[part 3 of 5: package /POWERTRAIN]
AUTOSAR XML (schema 3.2.2)
# Copyright (c) 2016 Daimler AG
package /POWERTRAIN  (continued)
  can cluster POWERTRAIN:  (continued)
    physical channel POWERTRAIN
      frame Ign_Veh_Stat_AR2: id 0x20, from CPC, to ASX ECM FFAP_STAR_2 FSCM ISM TCM, frame-length=8, can-addressing-mode=STANDARD  # Status Zündung/Fahrzeug / Ignition/vehicle state
        pdu Ign_Veh_Stat_AR2: length=64, unused-bit-pattern=0, cyclic-timing=repeating-time=0.1, event-controlled-timing=number-of-repeats=0, minimum-delay=0.0050  # Status Zündung/Fahrzeug / Ignition/vehicle state
          signal BusFlt_PrmntActv: start 35, 1 bit, little-endian, data-type=c01_NoFault_KeptAwake, init-value=lNO_FLT, transfer-property=TRIGGERED-ON-CHANGE, to ECM  # Bus fehlerhaft, permanent aktiv / Bus faulty, permanent active
          signal ContEngRun_Stat: start 36, 2 bit, little-endian, data-type=c02_ContEngRun_Stat, init-value=XDIS_9zsg7nirpdj3g8gia96831vcb/l3, transfer-property=TRIGGERED-ON-CHANGE, to ECM  # Status Motorweiterlaufschaltung / Continuous Engine Running State
          signal CRC_Ign_Stat_Pr2: start 0, 8 bit, little-endian, data-type=c08_CRC_woSNA, init-value=l34, transfer-property=PENDING, to ASX ECM FFAP_STAR_2 FSCM(timeout 1.05 s) ISM TCM  # CRC-Checksumme der Signal Gruppe gemäß AUTOSAR Profil 2 / CRC-checksum of signal group according to AUTOSAR Profile 2
          signal DidA_ExtTest_Pres: start 32, 1 bit, little-endian, data-type=DC_BOOL, init-value=XDIS_h5tcyk98kzbgrc5svasomeyt/lfalse, transfer-property=TRIGGERED-ON-CHANGE, to ASX ECM FFAP_STAR_2 FSCM ISM TCM  # DidA Externer Tester erkannt / DidA external tester present
          signal EngSt_Enbl_Rq_KG: start 28, 1 bit, little-endian, data-type=DC_BOOL, init-value=XDIS_h5tcyk98kzbgrc5svasomeyt/lfalse, transfer-property=TRIGGERED-ON-CHANGE, to ASX ECM FFAP_STAR_2 FSCM(timeout 1.05 s) ISM TCM  # Keyless Go Anlassbedingungen erfüllt / Enable engine start request
          signal ESL_Lk_Rq: start 18, 2 bit, little-endian, data-type=c02_ESL_Lk_Rq, init-value=XDIS_wgd5ub5vm3gd9qfahupgvut1/lDEFAULT, transfer-property=TRIGGERED-ON-CHANGE, to ASX ECM FFAP_STAR_2 FSCM(timeout 1.05 s) ISM TCM  # ELV Verriegelungsanforderung / ESL lock request
          signal Ign_On_StartProc_Inact: start 15, 1 bit, little-endian, data-type=DC_BOOL, init-value=XDIS_h5tcyk98kzbgrc5svasomeyt/lfalse, transfer-property=TRIGGERED-ON-CHANGE, to ASX ECM FFAP_STAR_2 FSCM(timeout 1.05 s) ISM TCM  # Zündung an/Motorstart aus / Ignition is on and starting procedure is inactive (15x)
          signal ISw_Stat: start 12, 3 bit, little-endian, data-type=c03_ISw_Stat, init-value=XDIS_15e0cs7gc4dn7o9pdwabj5z3d/l7, transfer-property=TRIGGERED-ON-CHANGE, to ASX ECM FFAP_STAR_2 FSCM(timeout 1.05 s) ISM TCM  # Klemmenstatus / Ignition switch state
          signal KG_IgnCtrl_Actv: start 16, 1 bit, little-endian, data-type=DC_BOOL, init-value=XDIS_h5tcyk98kzbgrc5svasomeyt/lfalse, transfer-property=TRIGGERED-ON-CHANGE, to ASX ECM FFAP_STAR_2 FSCM(timeout 1.05 s) ISM TCM  # Keyless Go Klemmenansteuerung aktiv / Keyless Go ignition control active
          signal KG_StartSw_Psd: start 17, 1 bit, little-endian, data-type=DC_BOOL, init-value=XDIS_h5tcyk98kzbgrc5svasomeyt/lfalse, transfer-property=TRIGGERED-ON-CHANGE, to ASX ECM FFAP_STAR_2 FSCM(timeout 1.05 s) ISM TCM  # Keyless Go Starttaster betätigt / Keyless Go start switch pressed
          signal Mobile_Chrg_Rq_EIS: start 38, 2 bit, little-endian, data-type=c03_Mobile_Chrg_Rq, init-value=XDIS_1pnuwiuijo5o0phdmlg74ub0g/l3, transfer-property=TRIGGERED-ON-CHANGE, to ECM  # Mobilgerät Status Ladeanforderung / Mobile device charging request
          signal RemSt_IgnCtrl_Actv: start 29, 1 bit, little-endian, data-type=DC_BOOL, init-value=XDIS_h5tcyk98kzbgrc5svasomeyt/lfalse, transfer-property=TRIGGERED-ON-CHANGE, to ASX ECM FFAP_STAR_2 FSCM(timeout 1.05 s) ISM TCM  # Klemmensteuerung Motorfernstart aktiv / Remote start ignition control active
          signal RemSt_IgnCtrl_Info: start 30, 2 bit, little-endian, data-type=c02_RemSt_IgnCtrl_Info, init-value=XDIS_f33ngg3qknqq6hf5cbz1jyfyc/lNO_RQ, transfer-property=TRIGGERED-ON-CHANGE, to ASX ECM FFAP_STAR_2 FSCM(timeout 1.05 s) ISM TCM  # Klemmensteuerung Motorfernstart Information / Remote start ignition control information
          signal RevGr_Engg: start 33, 2 bit, little-endian, data-type=c02_Disengg_Engg, init-value=XDIS_bjt3ib7wqik0sqxbiyd3ycy7c/l3, transfer-property=TRIGGERED-ON-CHANGE, to ECM  # Rückwärtsgang eingelegt / Reverse gear engaged
          signal SPCR_AcustWarn_Rq_EIS: start 23, 1 bit, little-endian, data-type=DC_BOOL, init-value=XDIS_h5tcyk98kzbgrc5svasomeyt/lfalse, transfer-property=TRIGGERED-ON-CHANGE, to ASX ECM FFAP_STAR_2 FSCM(timeout 1.05 s) ISM TCM  # Akustische Warnung SPCR / SPCR acoustical warning request
          signal SPCR_Conf_EIS: start 21, 2 bit, little-endian, data-type=c02_SPCR_Conf, init-value=lNOT_CONF, transfer-property=TRIGGERED-ON-CHANGE, to ASX ECM FFAP_STAR_2 FSCM(timeout 1.05 s) ISM TCM  # Konfiguration Stillstandskoordinator / Stop coordinator configuration
          signal SPCR_Flt_EIS: start 20, 1 bit, little-endian, data-type=DC_BOOL, init-value=XDIS_h5tcyk98kzbgrc5svasomeyt/lfalse, transfer-property=TRIGGERED-ON-CHANGE, to ASX ECM FFAP_STAR_2 FSCM(timeout 1.05 s) ISM TCM  # StopCoordinator Failure EIS
          signal SQC_Ign_Stat_Pr2: start 8, 4 bit, little-endian, data-type=c04_0_15_1_SNA_na, init-value=XDIS_2gdok7is6uk227cngmpgf9wxb/l0, transfer-property=PENDING, to ASX ECM FFAP_STAR_2 FSCM(timeout 1.05 s) ISM TCM  # Sequenzzähler / Sequence counter
          signal TxPkPosn_Emg_Rq: start 25, 1 bit, little-endian, data-type=DC_BOOL, init-value=XDIS_h5tcyk98kzbgrc5svasomeyt/lfalse, transfer-property=TRIGGERED-ON-CHANGE, to ASX ECM FFAP_STAR_2 FSCM(timeout 1.05 s) ISM TCM  # Anforderung Not-"P" / Transmission parking position emergency request
          signal TxPkPosn_Rq: start 24, 1 bit, little-endian, data-type=DC_BOOL, init-value=XDIS_h5tcyk98kzbgrc5svasomeyt/lfalse, transfer-property=TRIGGERED-ON-CHANGE, to ASX ECM FFAP_STAR_2 FSCM(timeout 1.05 s) ISM TCM  # EIS-Wunsch: "P" einlegen / Transmission parking position request
          signal TxPkPosn_Rq_SPCR_Enbl: start 27, 1 bit, little-endian, data-type=DC_BOOL, init-value=XDIS_h5tcyk98kzbgrc5svasomeyt/lfalse, transfer-property=TRIGGERED-ON-CHANGE, to ASX ECM FFAP_STAR_2 FSCM(timeout 1.05 s) ISM TCM  # SPCR-Wunsch: "P" einlegen erlaubt / Transmission parking position request enable
          signal TxPkPosnAuto_Enbl: start 26, 1 bit, little-endian, data-type=DC_BOOL, init-value=XDIS_h5tcyk98kzbgrc5svasomeyt/lfalse, transfer-property=TRIGGERED-ON-CHANGE, to ASX ECM FFAP_STAR_2 FSCM(timeout 1.05 s) ISM TCM  # Auto-"P" enabled / Transmission parking position auto enable
          signal Ign_Stat_Pr2_457i75qk4uen9ahb37ecxdhxz: little-endian, system-signal=[CRC_Ign_Stat_Pr2, EngSt_Enbl_Rq_KG, ESL_Lk_Rq, Ign_On_StartProc_Inact, ISw_Stat, KG_IgnCtrl_Actv, KG_StartSw_Psd, RemSt_IgnCtrl_Actv, RemSt_IgnCtrl_Info, SPCR_AcustWarn_Rq_EIS, SPCR_Conf_EIS, SPCR_Flt_EIS, SQC_Ign_Stat_Pr2, TxPkPosn_Emg_Rq, TxPkPosn_Rq, TxPkPosn_Rq_SPCR_Enbl, TxPkPosnAuto_Enbl], to ASX ECM FFAP_STAR_2 FSCM(timeout 1.05 s) ISM TCM  # Zündungsstatus (degraded) / Ignition state (degraded)
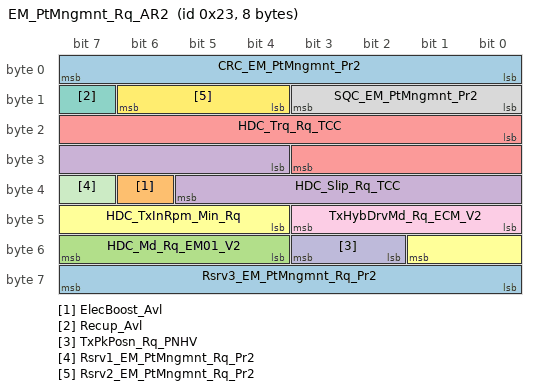
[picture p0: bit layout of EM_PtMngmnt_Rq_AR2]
      frame EM_PtMngmnt_Rq_AR2: id 0x23, from CPC, to ECM TCM, frame-length=8, can-addressing-mode=STANDARD
        pdu EM_PtMngmnt_Rq_AR2: length=64, unused-bit-pattern=0, cyclic-timing={repeating-time=0.02, starting-time=0.0050}
          signal CRC_EM_PtMngmnt_Pr2: start 0, 8 bit, little-endian, data-type=c08_CRC_woSNA, init-value=l74, to ECM TCM  # CRC-Checksumme der Signal Gruppe gemäß AUTOSAR Profil 2 / CRC-checksum of signal group according to AUTOSAR Profile 2
          signal ElecBoost_Avl: start 38, 1 bit, little-endian, data-type=DC_BOOL, init-value=XDIS_h5tcyk98kzbgrc5svasomeyt/lfalse, to ECM TCM  # Elektischer Boost verfügbar / Electrical boost available
          signal HDC_Md_Rq_EM01_V2: start 52, 4 bit, little-endian, data-type=c04_HDC_Md_Rq_EM, init-value=XDIS_8iaq8201r0988d05ciiqwp1g4/lIDLE, to ECM TCM  # Operation-Mode E-Maschine / Electric machine mode
          signal HDC_Slip_Rq_TCC: start 28, 10 bit, little-endian, data-type=c10_rpm_0_1022_1, init-value=XDIS_2gh0e6dr37noeqbe7360vka4a/l1023, to ECM TCM  # Slip request for torque converter lockup clutch
          signal HDC_Trq_Rq_TCC: start 16, 12 bit, little-endian, data-type=c12_Nm_m500_1547k5_0k5, init-value=XDIS_9p4jd6b80gmaaivpmq4d5qs5n/l0, to ECM TCM  # Torque request for torque converter lockup clutch
          signal HDC_TxInRpm_Min_Rq: start 44, 6 bit, little-endian, data-type=c06_rpm_0_6200_100, init-value=XDIS_5wlhhg7dgislovnjkmheyehg9/l63, to ECM TCM  # Anforderung min. Getriebeeingangsdrehzahl / Minimal transmission input RPM request
          signal Recup_Avl: start 15, 1 bit, little-endian, data-type=DC_BOOL, init-value=XDIS_h5tcyk98kzbgrc5svasomeyt/lfalse, to ECM TCM  # Rekuperation verfügbar / Recuperation available
          signal SQC_EM_PtMngmnt_Pr2: start 8, 4 bit, little-endian, data-type=c04_0_15_1_SNA_na, init-value=XDIS_2gdok7is6uk227cngmpgf9wxb/l0, to ECM TCM  # Sequenzzähler / Sequence counter
          signal TxHybDrvMd_Rq_ECM_V2: start 40, 4 bit, little-endian, data-type=c04_TxHybDrvMd_Rq_V2, init-value=lPT_DISENGG, to ECM TCM  # Anforderung Getriebe-Hybridmodus / Transmission hybrid driving mode request
          signal TxPkPosn_Rq_PNHV: start 50, 2 bit, little-endian, data-type=c02_PNHV_TxPkPosn_Rq, init-value=XDIS_dcnxhky8pp02zzvemp22clxcz/l3, to ECM TCM  # Kein Radmoment und keine Radbewegung erlaubt / No wheel torque and no wheel movement allowed
          signal Rsrv1_EM_PtMngmnt_Rq_Pr2: start 39, 1 bit, little-endian, data-type=Rsrv01, init-value=XDIS_e2uhxyvdu33zsyqfjnk549pp2/l0, to ECM TCM  # Reserviert für zukünftige Verwendung / Reserved for future use
          signal Rsrv2_EM_PtMngmnt_Rq_Pr2: start 12, 3 bit, little-endian, data-type=Rsrv03, init-value=XDIS_ds7bx5pu0edqfshg8l8g5rp9z/l0, to ECM TCM  # Reserviert für zukünftige Verwendung / Reserved for future use
          signal Rsrv3_EM_PtMngmnt_Rq_Pr2: start 56, 8 bit, little-endian, data-type=Rsrv08, init-value=XDIS_4flxbk4wkjkdew7cw07d9of66/l0, to ECM TCM  # Reserviert für zukünftige Verwendung / Reserved for future use
          signal EM_PtMngmnt_Pr2_3wxzgy1jeqdhai2x3bxoim0oa: little-endian, system-signal=[CRC_EM_PtMngmnt_Pr2, ElecBoost_Avl, HDC_Md_Rq_EM01_V2, HDC_Slip_Rq_TCC, HDC_Trq_Rq_TCC, HDC_TxInRpm_Min_Rq, Recup_Avl, Rsrv1_EM_PtMngmnt_Rq_Pr2, Rsrv2_EM_PtMngmnt_Rq_Pr2, Rsrv3_EM_PtMngmnt_Rq_Pr2, SQC_EM_PtMngmnt_Pr2, TxHybDrvMd_Rq_ECM_V2, TxPkPosn_Rq_PNHV], transfer-property=PENDING, to ECM TCM  # EM_PtMngmnt_Pr2 (degraded)
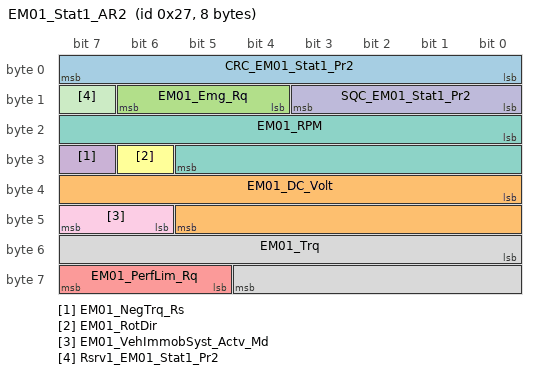
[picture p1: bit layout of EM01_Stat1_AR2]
      frame EM01_Stat1_AR2: id 0x27, from CPC, to ECM TCM, frame-length=8, can-addressing-mode=STANDARD
        pdu EM01_Stat1_AR2: length=64, unused-bit-pattern=0, cyclic-timing=repeating-time=0.01
          signal CRC_EM01_Stat1_Pr2: start 0, 8 bit, little-endian, data-type=c08_CRC_woSNA, init-value=l131, to ECM TCM  # CRC-Checksumme der Signal Gruppe gemäß AUTOSAR Profil 2 / CRC-checksum of signal group according to AUTOSAR Profile 2
          signal EM01_DC_Volt: start 32, 14 bit, little-endian, data-type=c14_V_0_1638k2_0k1, init-value=XDIS_9rrg0shmfwprce4xy23v3tfyt/l16383, to ECM TCM  # E-Maschine DC Spannung / Electric machine DC voltage
          signal EM01_Emg_Rq: start 12, 3 bit, little-endian, data-type=c03_EM01_Emg_Rq, init-value=XDIS_cd3oy5177qa3y14g9h238t663/lIDLE, to ECM TCM  # E-Maschine Notfall-Anforderung / Electric machine emergency request
          signal EM01_NegTrq_Rs: start 31, 1 bit, little-endian, data-type=c01_EM01_NegTrq_Rs, init-value=XDIS_91v13cnwelt8obxl65urhlwfi/lFALSE, to ECM TCM  # EM01 negative Moment-Rückmeldung / EM01 negative torque response
          signal EM01_PerfLim_Rq: start 61, 3 bit, little-endian, data-type=c03_EM01_Cool_Rq_V2, init-value=XDIS_9tk8nsfd7or9qg8w6lzymt0lv/l7, to ECM TCM  # Anforderung E-Maschine Leistungsbegrenzung / Electric machine performance limitation request
          signal EM01_RotDir: start 30, 1 bit, little-endian, data-type=c01_Dir_Same_Opposite, init-value=lSAME, to ECM TCM  # Drehrichtung E-Maschine 2 / Electric machine #2 rotation direction
          signal EM01_RPM: start 16, 14 bit, little-endian, data-type=c14_rpm_0_16382_1, init-value=XDIS_82nfehr3ho0td8jgmxjg4mj72/l16383, to ECM TCM  # Aktuelle Drehzahl E-Maschine / Actual rpm from electric machine
          signal EM01_Trq: start 48, 13 bit, little-endian, data-type=c13_Nm_m500_1547k5_0k25, init-value=XDIS_emg3258s4xg6nj4415gnzzldg/l8191, to ECM TCM  # Aktuelles Drehmoment E-Maschine 2 / Actual electric machine #2 crankshaft torque
          signal EM01_VehImmobSyst_Actv_Md: start 46, 2 bit, little-endian, data-type=c02_Rel_Lock_SNA, init-value=XDIS_9gn5j7uadcycp6vp4d1kfab5z/lREL, to ECM TCM  # FBS: Start Error, Wegfahrsperre aktiv / Vehicle immobilizing system active
          signal SQC_EM01_Stat1_Pr2: start 8, 4 bit, little-endian, data-type=c04_0_15_1_SNA_na, init-value=XDIS_2gdok7is6uk227cngmpgf9wxb/l0, to ECM TCM  # Sequenzzähler / Sequence counter
          signal Rsrv1_EM01_Stat1_Pr2: start 15, 1 bit, little-endian, data-type=Rsrv01, init-value=XDIS_e2uhxyvdu33zsyqfjnk549pp2/l0, to ECM TCM  # Reserviert für zukünftige Verwendung / Reserved for future use
          signal EM01_Stat1_Pr2_4hvri6w0u2vqjawx4ll81022i: little-endian, system-signal=[CRC_EM01_Stat1_Pr2, EM01_DC_Volt, EM01_Emg_Rq, EM01_NegTrq_Rs, EM01_PerfLim_Rq, EM01_RotDir, EM01_RPM, EM01_Trq, EM01_VehImmobSyst_Actv_Md, Rsrv1_EM01_Stat1_Pr2, SQC_EM01_Stat1_Pr2], transfer-property=PENDING, to ECM TCM  # EM01_Stat1_Pr2 (degraded)
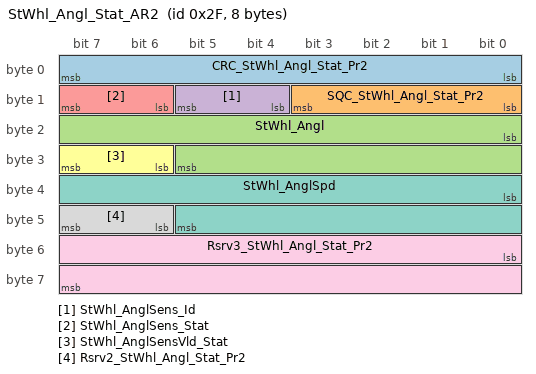
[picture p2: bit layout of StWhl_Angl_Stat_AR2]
      frame StWhl_Angl_Stat_AR2: id 0x2F, from CPC, to TCM, frame-length=8, can-addressing-mode=STANDARD  # Lenkradwinkel / Steering wheel angle
        pdu StWhl_Angl_Stat_AR2: length=64, unused-bit-pattern=0, cyclic-timing={repeating-time=0.1, starting-time=0.04}  # Lenkradwinkel / Steering wheel angle
          signal CRC_StWhl_Angl_Stat_Pr2: start 0, 8 bit, little-endian, data-type=c08_CRC_woSNA, init-value=l83, to TCM  # CRC-Checksumme der Signal Gruppe gemäß AUTOSAR Profil 2 / CRC-checksum of signal group according to AUTOSAR Profile 2
          signal SQC_StWhl_Angl_Stat_Pr2: start 8, 4 bit, little-endian, data-type=c04_0_15_1_SNA_na, init-value=XDIS_2gdok7is6uk227cngmpgf9wxb/l0, to TCM  # Sequenzzähler / Sequence counter
          signal StWhl_Angl: start 16, 14 bit, little-endian, data-type=c14_deg_m819k2_819_0k1, init-value=XDIS_7o500du5tkpdngqoew5gqb2da/l16383, to TCM  # Lenkradwinkel (+ = rechts) / Steering wheel angle (+ means right)
          signal StWhl_AnglSens_Id: start 12, 2 bit, little-endian, data-type=c02_StWhl_AnglSens_Id, init-value=lTEST, to TCM  # Identifikation Lenkradwinkelsensor / Steering wheel angle sensor identification
          signal StWhl_AnglSens_Stat: start 14, 2 bit, little-endian, data-type=c02_StWhl_AnglSens_Stat, init-value=lERR_INI, to TCM  # Status Lenkradwinkelsensor / Steering wheel angle sensor state
          signal StWhl_AnglSensVld_Stat: start 30, 2 bit, little-endian, data-type=c02_StWhl_AnglSensVld_Stat, init-value=lINVLD, to TCM  # Gültigkeitsstatus Lenkwinkelsensor / Steering wheel angle sensor validity state
          signal StWhl_AnglSpd: start 32, 14 bit, little-endian, data-type=c14_deg_p_s_m4096_4095_0k5, init-value=XDIS_bprucmwcs9loym60q0osalcwr/l16383, to TCM  # Lenkradwinkelgeschwindigkeit / Steering wheel angle speed
          signal Rsrv2_StWhl_Angl_Stat_Pr2: start 46, 2 bit, little-endian, data-type=Rsrv02, init-value=XDIS_7jeo5ges9wp8ufla3pohsuw83/l0, to TCM  # Reserviert für zukünftige Verwendung / Reserved for future use
          signal Rsrv3_StWhl_Angl_Stat_Pr2: start 48, 16 bit, little-endian, data-type=Rsrv16, init-value=XDIS_cvmn4avy0ja0228879wthq11/l16383, to TCM  # Reserviert für zukünftige Verwendung / Reserved for future use
          signal StWhl_Angl_Stat_Pr2_c4qb7b59jfa5oc3ih83ubw184: little-endian, system-signal=[CRC_StWhl_Angl_Stat_Pr2, Rsrv2_StWhl_Angl_Stat_Pr2, Rsrv3_StWhl_Angl_Stat_Pr2, SQC_StWhl_Angl_Stat_Pr2, StWhl_Angl, StWhl_AnglSens_Id, StWhl_AnglSens_Stat, StWhl_AnglSensVld_Stat, StWhl_AnglSpd], transfer-property=PENDING, to TCM  # Lenkradwinkel (degraded) / Steering wheel angle (degraded)
      frame SBW_Stat_AR2: id 0x37, from ISM TCM, to CPC ECM TCM, frame-length=8, can-addressing-mode=STANDARD
        pdu SBW_Stat_AR2: length=64, unused-bit-pattern=0, cyclic-timing={repeating-time=0.1, starting-time=0.04}, event-controlled-timing=number-of-repeats=0, minimum-delay=0.01
          signal CRC_SBW_Stat_Pr2: start 0, 8 bit, little-endian, data-type=c08_CRC_woSNA, init-value=l80, transfer-property=PENDING, to CPC ECM TCM  # CRC-Checksumme der Signal Gruppe gemäß AUTOSAR Profil 2 / CRC-checksum of signal group according to AUTOSAR Profile 2
          signal EmgPath_Enbl: start 12, 1 bit, little-endian, data-type=DC_BOOL, init-value=XDIS_h5tcyk98kzbgrc5svasomeyt/lfalse, transfer-property=TRIGGERED-ON-CHANGE, to CPC ECM TCM  # Notfallpfad freigegegeben / Emergency path enabled
          signal EmgPath_Volt: start 24, 8 bit, little-endian, data-type=c08_V_0_25k4_0k1, init-value=XDIS_6h0vlx83b98yborknhrn3o3li/l255, transfer-property=TRIGGERED-ON-CHANGE, to CPC ECM TCM  # Spannung Notfallpfad / Emergency path voltage
          signal ISM_LHOM: start 15, 1 bit, little-endian, data-type=DC_BOOL, init-value=XDIS_h5tcyk98kzbgrc5svasomeyt/lfalse, transfer-property=PENDING, to CPC ECM TCM  # ISM-Notlauf / Intelligent gear shift module in limp-home operation mode
          signal Key_P_Enbl: start 13, 1 bit, little-endian, data-type=DC_BOOL, init-value=XDIS_h5tcyk98kzbgrc5svasomeyt/lfalse, transfer-property=TRIGGERED-ON-CHANGE, to CPC ECM TCM  # Taste "P Einlegen" freigegeben / Key-P-engage enabled
          signal SHW_MnTrctAxl_D_DrvPosn_Enbl: start 52, 1 bit, little-endian, data-type=DC_BOOL, init-value=XDIS_h5tcyk98kzbgrc5svasomeyt/lfalse, transfer-property=TRIGGERED-ON-CHANGE, to CPC ECM TCM  # Hauptantriebsachse Fahrposition D verfügbar / Main traction axle driving position D enabled
          signal SHW_MnTrctAxl_DrvPosn_Tgt_Rq_TCM: start 48, 4 bit, little-endian, data-type=c04_Axl_DrvPosn_TCM, init-value=XDIS_efk9f76682gf9dv40xdoqarq5/l15, transfer-property=TRIGGERED-ON-CHANGE, to CPC ECM TCM  # Fahrstufenanforderungen von TCM / main traction axle driving position target request from TCM
          signal SHW_MnTrctAxl_Flt1: start 40, 1 bit, little-endian, data-type=DC_BOOL, init-value=XDIS_h5tcyk98kzbgrc5svasomeyt/lfalse, transfer-property=TRIGGERED-ON-CHANGE, to CPC ECM TCM  # Shift by wire Hauptantriebsachse Fehler 1 / Shift by wire main traction axle fault 1
          signal SHW_MnTrctAxl_Flt2: start 41, 1 bit, little-endian, data-type=DC_BOOL, init-value=XDIS_h5tcyk98kzbgrc5svasomeyt/lfalse, transfer-property=TRIGGERED-ON-CHANGE, to CPC ECM TCM  # Shift by wire Hauptantriebsachse Fehler 2 / Shift by wire main traction axle fault 2
          signal SHW_MnTrctAxl_Flt3: start 42, 1 bit, little-endian, data-type=DC_BOOL, init-value=XDIS_h5tcyk98kzbgrc5svasomeyt/lfalse, transfer-property=TRIGGERED-ON-CHANGE, to CPC ECM TCM  # Shift by wire Hauptantriebsachse Fehler 3 / Shift by wire main traction axle fault 3
          signal SHW_MnTrctAxl_Flt4: start 43, 1 bit, little-endian, data-type=DC_BOOL, init-value=XDIS_h5tcyk98kzbgrc5svasomeyt/lfalse, transfer-property=TRIGGERED-ON-CHANGE, to CPC ECM TCM  # Shift by wire Hauptantriebsachse Fehler 4 / Shift by wire main traction axle fault 4
          signal SHW_MnTrctAxl_Flt5: start 44, 1 bit, little-endian, data-type=DC_BOOL, init-value=XDIS_h5tcyk98kzbgrc5svasomeyt/lfalse, transfer-property=TRIGGERED-ON-CHANGE, to CPC ECM TCM  # Shift by wire Hauptantriebsachse Fehler 5 / Shift by wire main traction axle fault 5
          signal SHW_MnTrctAxl_Flt6: start 45, 1 bit, little-endian, data-type=DC_BOOL, init-value=XDIS_h5tcyk98kzbgrc5svasomeyt/lfalse, transfer-property=TRIGGERED-ON-CHANGE, to CPC ECM TCM  # Shift by wire Hauptantriebsachse Fehler 6 / Shift by wire main traction axle fault 6
          signal SHW_MnTrctAxl_Flt7: start 46, 1 bit, little-endian, data-type=DC_BOOL, init-value=XDIS_h5tcyk98kzbgrc5svasomeyt/lfalse, transfer-property=TRIGGERED-ON-CHANGE, to CPC ECM TCM  # Shift by wire Hauptantriebsachse Fehler 7 / Shift by wire main traction axle fault 7
          signal SHW_MnTrctAxl_Flt8: start 47, 1 bit, little-endian, data-type=DC_BOOL, init-value=XDIS_h5tcyk98kzbgrc5svasomeyt/lfalse, transfer-property=TRIGGERED-ON-CHANGE, to CPC ECM TCM  # Shift by wire Hauptantriebsachse Fehler 8 / Shift by wire main traction axle fault 8
          signal SHW_MnTrctAxl_N_DrvPosn_Enbl: start 53, 1 bit, little-endian, data-type=DC_BOOL, init-value=XDIS_h5tcyk98kzbgrc5svasomeyt/lfalse, transfer-property=TRIGGERED-ON-CHANGE, to CPC ECM TCM  # Hauptantriebsachse Fahrposition N verfügbar / Main traction axle driving position N enabled
          signal SHW_MnTrctAxl_P_DrvPosn_Enbl: start 55, 1 bit, little-endian, data-type=DC_BOOL, init-value=XDIS_h5tcyk98kzbgrc5svasomeyt/lfalse, transfer-property=TRIGGERED-ON-CHANGE, to CPC ECM TCM  # Hauptantriebsachse Fahrposition P verfügbar / Main traction axle driving position P enabled
          signal SHW_MnTrctAxl_R_DrvPosn_Enbl: start 54, 1 bit, little-endian, data-type=DC_BOOL, init-value=XDIS_h5tcyk98kzbgrc5svasomeyt/lfalse, transfer-property=TRIGGERED-ON-CHANGE, to CPC ECM TCM  # Hauptantriebsachse Fahrposition R verfügbar / Main traction axle driving position R enabled
          signal SPCR_Dsabl_Rq_ISM: start 14, 1 bit, little-endian, data-type=DC_BOOL, init-value=XDIS_h5tcyk98kzbgrc5svasomeyt/lfalse, transfer-property=TRIGGERED-ON-CHANGE, to CPC ECM TCM  # Anforderung Stillstandskoordinator (Hold/Stop) abschalten / Stop coordinator (Hold/Stop) disable request
          signal SQC_SBW_Stat_Pr2: start 8, 4 bit, little-endian, data-type=c04_0_15_1_SNA_na, init-value=XDIS_2gdok7is6uk227cngmpgf9wxb/l0, transfer-property=PENDING, to CPC ECM TCM  # Sequenzzähler / Sequence counter
          signal TSL_Posn_ISM: start 16, 4 bit, little-endian, data-type=c04_TSL_Posn, init-value=XDIS_1tyvwxaq4y58gqcagg85x4e42/l15, transfer-property=TRIGGERED-ON-CHANGE, to CPC ECM TCM  # Getriebewählhebelstellung / Transmission selector lever position
          signal TSL_Posn_ISM_Init: start 38, 2 bit, little-endian, data-type=c02_TSL_Posn_ISM_Init, init-value=lNO_INIT, transfer-property=TRIGGERED-ON-CHANGE, to CPC ECM TCM  # Getriebe-Wählhebel ursprüngliche Position / Transmission selector lever initial position
          signal TSL_Posn_P_ISM: start 37, 1 bit, little-endian, data-type=DC_BOOL, init-value=XDIS_h5tcyk98kzbgrc5svasomeyt/lfalse, transfer-property=TRIGGERED-ON-CHANGE, to CPC ECM TCM  # Getriebewählhebel sicher in Stellung P / Transmission selector lever has reached position P
          signal TSL_Posn_Target: start 20, 4 bit, little-endian, data-type=c04_TSL_Posn_Target, init-value=XDIS_bo54gn5pc8vza1o6cvxoet0d5/l15, transfer-property=TRIGGERED-ON-CHANGE, to CPC ECM TCM  # Ziel-Getriebewählhebelstellung / Transmission selector lever target position
          signal TSL_ShiftLk_Stat: start 32, 2 bit, little-endian, data-type=c02_TSL_ShiftLk_Stat, init-value=XDIS_7yalllmilw1ujjshxp2jku3lj/lIDLE, transfer-property=TRIGGERED-ON-CHANGE, to CPC ECM TCM  # Status Getriebewählhebel Shift-Lock-Sperre / Transmission selector lever shift lock state
          signal TxN_Posn_Rq_D_V2: start 35, 2 bit, little-endian, data-type=c02_InActv_Actv, init-value=XDIS_a7fn7gu0o6trtoxxkozis2zcm/l3, transfer-property=TRIGGERED-ON-CHANGE, to CPC ECM TCM  # Fahrerwunsch "N" einlegen / Transmission neutral position request by driver
          signal TxPkPosn_Emg_Actv: start 34, 1 bit, little-endian, data-type=DC_BOOL, init-value=XDIS_h5tcyk98kzbgrc5svasomeyt/lfalse, transfer-property=TRIGGERED-ON-CHANGE, to CPC ECM TCM  # Not-"P" aktiv / Transmission parking position emergency active
          signal Rsrv1_SBW_Stat_Pr2: start 56, 8 bit, little-endian, data-type=Rsrv08, init-value=XDIS_4flxbk4wkjkdew7cw07d9of66/l0, transfer-property=PENDING, to CPC ECM TCM  # Reserviert für zukünftige Verwendung / Reserved for future use
          signal SBW_Stat_Pr2_ecnxwrof0tv45hxypgialh6k2: little-endian, system-signal=[CRC_SBW_Stat_Pr2, EmgPath_Enbl, EmgPath_Volt, ISM_LHOM, Key_P_Enbl, Rsrv1_SBW_Stat_Pr2, SHW_MnTrctAxl_D_DrvPosn_Enbl, SHW_MnTrctAxl_DrvPosn_Tgt_Rq_TCM, SHW_MnTrctAxl_Flt1, SHW_MnTrctAxl_Flt2, SHW_MnTrctAxl_Flt3, SHW_MnTrctAxl_Flt4, SHW_MnTrctAxl_Flt5, SHW_MnTrctAxl_Flt6, SHW_MnTrctAxl_Flt7, SHW_MnTrctAxl_Flt8, SHW_MnTrctAxl_N_DrvPosn_Enbl, SHW_MnTrctAxl_P_DrvPosn_Enbl, SHW_MnTrctAxl_R_DrvPosn_Enbl, SPCR_Dsabl_Rq_ISM, SQC_SBW_Stat_Pr2, TSL_Posn_ISM, TSL_Posn_ISM_Init, TSL_Posn_P_ISM, TSL_Posn_Target, TSL_ShiftLk_Stat, TxN_Posn_Rq_D_V2, TxPkPosn_Emg_Actv], to CPC ECM TCM  # Shift by wire status (degraded)
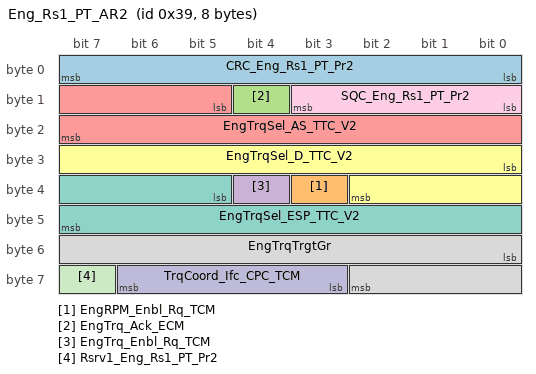
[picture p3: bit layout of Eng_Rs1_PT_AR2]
      frame Eng_Rs1_PT_AR2: id 0x39, from CPC, to DRVU TCM, frame-length=8, can-addressing-mode=STANDARD
        pdu Eng_Rs_1_PT_AR2: length=64, unused-bit-pattern=0, cyclic-timing={repeating-time=0.01, starting-time=0.0}  # Eng_Rs1_PT
          signal CRC_Eng_Rs1_PT_Pr2: start 0, 8 bit, little-endian, data-type=c08_CRC_woSNA, init-value=l106, to DRVU(timeout 0.105 s) TCM  # CRC-Checksumme der Signal Gruppe gemäß AUTOSAR Profil 2 / CRC-checksum of signal group according to AUTOSAR Profile 2
          signal EngRPM_Enbl_Rq_TCM: start 35, 1 bit, little-endian, data-type=DC_BOOL, init-value=XDIS_h5tcyk98kzbgrc5svasomeyt/lfalse, to DRVU(timeout 0.105 s) TCM  # Enable engine speed request by TCM
          signal EngTrq_Ack_ECM: start 12, 1 bit, little-endian, data-type=DC_BOOL, init-value=XDIS_h5tcyk98kzbgrc5svasomeyt/lfalse, to DRVU(timeout 0.105 s) TCM  # Quittierung Momentenanforderung / Engine torque request acknowledgement
          signal EngTrq_Enbl_Rq_TCM: start 36, 1 bit, little-endian, data-type=DC_BOOL, init-value=ltrue, to DRVU(timeout 0.105 s) TCM  # Enable Momentenanforderung TCM / Enable engine torque request by TCM
          signal EngTrqSel_AS_TTC_V2: start 13, 11 bit, little-endian, data-type=c11_Nm_m500_1546k0_1k0, init-value=XDIS_c1d4l3fliyrryv1w2ncd3uiy6/l2047, to DRVU(timeout 0.105 s) TCM  # Vorgabemoment AS inklusive Schubanteil / Selected torque by AS including trailing throttle component
          signal EngTrqSel_D_TTC_V2: start 24, 11 bit, little-endian, data-type=c11_Nm_m500_1546k0_1k0, init-value=XDIS_c1d4l3fliyrryv1w2ncd3uiy6/l2047, to DRVU(timeout 0.105 s) TCM  # Vorgabemoment Fahrer inklusive Schubanteil / Selected torque by driver including trailing throttle component
          signal EngTrqSel_ESP_TTC_V2: start 37, 11 bit, little-endian, data-type=c11_Nm_m500_1546k0_1k0, init-value=XDIS_c1d4l3fliyrryv1w2ncd3uiy6/l2047, to DRVU(timeout 0.105 s) TCM  # Vorgabemoment ESP inklusive Schubanteil / Selected torque by ESP including trailing throttle component
          signal EngTrqTrgtGr: start 48, 11 bit, little-endian, data-type=c11_Nm_m500_1546k0_1k0, init-value=XDIS_c1d4l3fliyrryv1w2ncd3uiy6/l2047, to DRVU(timeout 0.105 s) TCM  # Motormoment im Zielgang / Engine torque at target gear
          signal SQC_Eng_Rs1_PT_Pr2: start 8, 4 bit, little-endian, data-type=c04_0_15_1_SNA_na, init-value=XDIS_2gdok7is6uk227cngmpgf9wxb/l0, to DRVU(timeout 0.105 s) TCM  # Sequenzzähler / Sequence counter
          signal TrqCoord_Ifc_CPC_TCM: start 59, 4 bit, little-endian, data-type=c04_0_15_1_SNA_na, init-value=XDIS_2gdok7is6uk227cngmpgf9wxb/l0, to DRVU(timeout 0.105 s) TCM  # Momentensteuerungs-Interface zwischen CPC und TCM) / Torque coordination interface between CPC and TCM
          signal Rsrv1_Eng_Rs1_PT_Pr2: start 63, 1 bit, little-endian, data-type=Rsrv01, init-value=XDIS_e2uhxyvdu33zsyqfjnk549pp2/l0, to DRVU TCM  # Reserviert für zukünftige Verwendung / Reserved for future use
          signal Eng_Rs1_PT_Pr2_cf9mw3gecnkesr53zjhm61sph: little-endian, system-signal=[CRC_Eng_Rs1_PT_Pr2, EngRPM_Enbl_Rq_TCM, EngTrq_Ack_ECM, EngTrq_Enbl_Rq_TCM, EngTrqSel_AS_TTC_V2, EngTrqSel_D_TTC_V2, EngTrqSel_ESP_TTC_V2, EngTrqTrgtGr, Rsrv1_Eng_Rs1_PT_Pr2, SQC_Eng_Rs1_PT_Pr2, TrqCoord_Ifc_CPC_TCM], transfer-property=PENDING, to DRVU(timeout 0.105 s) TCM  # Motoransprechverhalten Powertrain Management (degraded) / Engine response Powertrain management (degraded)
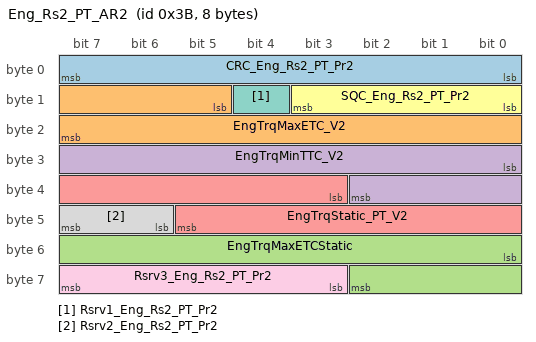
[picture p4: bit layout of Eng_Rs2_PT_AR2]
      frame Eng_Rs2_PT_AR2: id 0x3B, from CPC, to ASX ECM FSCM TCM TGW, frame-length=8, can-addressing-mode=STANDARD  # Motoransprechverhalten Powertrain Management / Engine response Powertrain management
        pdu Eng_Rs_2_PT_AR2: length=64, unused-bit-pattern=0, cyclic-timing={repeating-time=0.01, starting-time=0.0}  # Motoransprechverhalten Powertrain Management / Engine response Powertrain management
          signal CRC_Eng_Rs2_PT_Pr2: start 0, 8 bit, little-endian, data-type=c08_CRC_woSNA, init-value=l241, to ASX(timeout 0.105 s) ECM FSCM TCM TGW(timeout 0.105 s)  # CRC-Checksumme der Signal Gruppe gemäß AUTOSAR Profil 2 / CRC-checksum of signal group according to AUTOSAR Profile 2
          signal EngTrqMaxETC_V2: start 13, 11 bit, little-endian, data-type=c11_Nm_m500_1546k0_1k0, init-value=XDIS_c1d4l3fliyrryv1w2ncd3uiy6/l2047, to ASX(timeout 0.105 s) ECM FSCM TCM TGW(timeout 0.105 s)  # Maximales Moment Verbrenner mit Abgasturbolader / Actual maximum engine torque including dynamic exhaust turbocharger torque
          signal EngTrqMaxETCStatic: start 48, 11 bit, little-endian, data-type=c11_Nm_m500_1546k0_1k0, init-value=XDIS_c1d4l3fliyrryv1w2ncd3uiy6/l2047, to ASX(timeout 0.105 s) ECM FSCM TCM TGW(timeout 0.105 s)  # Maximal-Moment bei maximalem Ladedruck / Maximum torque at maximum ETC pressure
          signal EngTrqMinTTC_V2: start 24, 11 bit, little-endian, data-type=c11_Nm_m500_1546k0_1k0, init-value=XDIS_c1d4l3fliyrryv1w2ncd3uiy6/l2047, to ASX(timeout 0.105 s) ECM FSCM TCM TGW(timeout 0.105 s)  # Motormoment minimal inklusive Schubanteil / Actual mimimum engine torque including trailing throttle component
          signal EngTrqStatic_PT_V2: start 35, 11 bit, little-endian, data-type=c11_Nm_m500_1546k0_1k0, init-value=XDIS_c1d4l3fliyrryv1w2ncd3uiy6/l2047, to ASX(timeout 0.105 s) ECM FSCM TCM TGW(timeout 0.105 s)  # Motormoment statisch / Actual static engine torque
          signal SQC_Eng_Rs2_PT_Pr2: start 8, 4 bit, little-endian, data-type=c04_0_15_1_SNA_na, init-value=XDIS_2gdok7is6uk227cngmpgf9wxb/l0, to ASX(timeout 0.105 s) ECM FSCM TCM TGW(timeout 0.105 s)  # Sequenzzähler / Sequence counter
          signal Rsrv1_Eng_Rs2_PT_Pr2: start 12, 1 bit, little-endian, data-type=Rsrv01, init-value=XDIS_e2uhxyvdu33zsyqfjnk549pp2/l0, to ASX ECM FSCM TCM TGW  # Reserviert für zukünftige Verwendung / Reserved for future use
          signal Rsrv2_Eng_Rs2_PT_Pr2: start 46, 2 bit, little-endian, data-type=Rsrv02, init-value=XDIS_7jeo5ges9wp8ufla3pohsuw83/l0, to ASX ECM FSCM TCM TGW  # Reserviert für zukünftige Verwendung / Reserved for future use
          signal Rsrv3_Eng_Rs2_PT_Pr2: start 59, 5 bit, little-endian, data-type=Rsrv05, init-value=XDIS_e6yko3jf7vueybb3pnb685vj8/l0, to ASX ECM FSCM TCM TGW  # Reserviert für zukünftige Verwendung / Reserved for future use
          signal Eng_Rs2_PT_Pr2_a8h33xdavwvlmc583w9zxcagw: little-endian, system-signal=[CRC_Eng_Rs2_PT_Pr2, EngTrqMaxETC_V2, EngTrqMaxETCStatic, EngTrqMinTTC_V2, EngTrqStatic_PT_V2, Rsrv1_Eng_Rs2_PT_Pr2, Rsrv2_Eng_Rs2_PT_Pr2, Rsrv3_Eng_Rs2_PT_Pr2, SQC_Eng_Rs2_PT_Pr2], transfer-property=PENDING, to ASX(timeout 0.105 s) ECM FSCM TCM TGW(timeout 0.105 s)  # Motoransprechverhalten Powertrain Management (degraded) / Engine response Powertrain management (degraded)
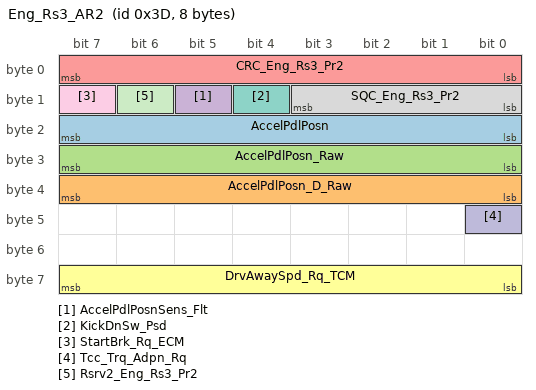
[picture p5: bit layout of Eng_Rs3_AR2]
      frame Eng_Rs3_AR2: id 0x3D, from CPC, to ASX DRVU ECM FFAP_STAR_2 TCM, frame-length=8, can-addressing-mode=STANDARD
        pdu Eng_Rs_3_AR2: length=64, unused-bit-pattern=0, cyclic-timing={repeating-time=0.02, starting-time=0.01}  # Eng_Rs3
          signal AccelPdlPosn: start 16, 8 bit, little-endian, data-type=c08_perc_0_100_0k4, init-value=XDIS_m57vh5549mw8mqr4231e8x8w/l255, to ASX DRVU(timeout 0.21 s) ECM FFAP_STAR_2 TCM  # Pedalwert / Accelerator pedal position
          signal AccelPdlPosn_D_Raw: start 32, 8 bit, little-endian, data-type=c08_perc_0_100_0k4, init-value=XDIS_m57vh5549mw8mqr4231e8x8w/l255, to ASX DRVU(timeout 0.21 s) ECM FFAP_STAR_2 TCM  # Pedalwert mit statischer und dynamischer Überhöhung / Accelerator pedal position with static and dynamic signal elevation
          signal AccelPdlPosn_Raw: start 24, 8 bit, little-endian, data-type=c08_perc_0_100_0k4, init-value=XDIS_m57vh5549mw8mqr4231e8x8w/l255, to ASX DRVU(timeout 0.21 s) ECM FFAP_STAR_2 TCM  # Pedalwert Fahrer / Accelerator pedal position raw value
          signal AccelPdlPosnSens_Flt: start 13, 1 bit, little-endian, data-type=DC_BOOL, init-value=XDIS_h5tcyk98kzbgrc5svasomeyt/lfalse, to ASX DRVU(timeout 0.21 s) ECM FFAP_STAR_2 TCM  # Fehler Pedalwertgeber / Accelerator pedal position sensor fault
          signal CRC_Eng_Rs3_Pr2: start 0, 8 bit, little-endian, data-type=c08_CRC_woSNA, init-value=l55, to ASX DRVU(timeout 0.21 s) ECM FFAP_STAR_2 TCM  # CRC-Checksumme der Signal Gruppe gemäß AUTOSAR Profil 2 / CRC-checksum of signal group according to AUTOSAR Profile 2
          signal DrvAwaySpd_Rq_TCM: start 56, 8 bit, little-endian, data-type=c08_rpm_500_3000_10, init-value=XDIS_77fxcf0bwhvvuz9q4jitpa0mm/l0, transfer-property=PENDING, to TCM  # Zieldrehzahl der Anfahrunterstützung / Drive Away Speed request to TCM
          signal KickDnSw_Psd: start 12, 1 bit, little-endian, data-type=DC_BOOL, init-value=XDIS_h5tcyk98kzbgrc5svasomeyt/lfalse, to ASX DRVU(timeout 0.21 s) ECM FFAP_STAR_2 TCM  # Kickdown betätigt / Kickdown switch pressed
          signal SQC_Eng_Rs3_Pr2: start 8, 4 bit, little-endian, data-type=c04_0_15_1_SNA_na, init-value=XDIS_2gdok7is6uk227cngmpgf9wxb/l0, to ASX DRVU(timeout 0.21 s) ECM FFAP_STAR_2 TCM  # Sequenzzähler / Sequence counter
          signal StartBrk_Rq_ECM: start 15, 1 bit, little-endian, data-type=DC_BOOL, init-value=XDIS_h5tcyk98kzbgrc5svasomeyt/lfalse, to ASX DRVU(timeout 0.21 s) ECM FFAP_STAR_2 TCM  # Bremse anlegen bei Einschaltvorgang von Motor / Brake during start request from ECM
          signal Tcc_Trq_Adpn_Rq: start 40, 1 bit, little-endian, data-type=DC_BOOL, init-value=XDIS_h5tcyk98kzbgrc5svasomeyt/lfalse, transfer-property=PENDING, to TCM  # Signal for TorqueConverter Control for Torque Adaption
          signal Rsrv2_Eng_Rs3_Pr2: start 14, 1 bit, little-endian, data-type=Rsrv01, init-value=XDIS_e2uhxyvdu33zsyqfjnk549pp2/l0, to ASX DRVU ECM FFAP_STAR_2 TCM  # Reserviert für zukünftige Verwendung / Reserved for future use
          signal Eng_Rs3_Pr2_dbt1hpurrces52skcqo6f7f6g: little-endian, system-signal=[AccelPdlPosn, AccelPdlPosn_D_Raw, AccelPdlPosn_Raw, AccelPdlPosnSens_Flt, CRC_Eng_Rs3_Pr2, KickDnSw_Psd, Rsrv2_Eng_Rs3_Pr2, SQC_Eng_Rs3_Pr2, StartBrk_Rq_ECM], transfer-property=PENDING, to ASX DRVU(timeout 0.21 s) ECM FFAP_STAR_2 TCM  # Eng_Rs3_Pr2 (degraded)
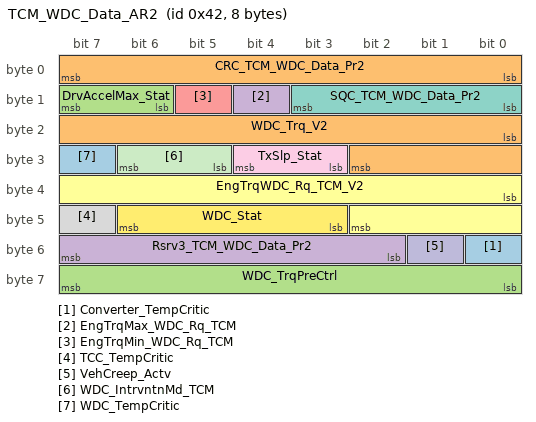
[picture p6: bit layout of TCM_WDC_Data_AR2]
      frame TCM_WDC_Data_AR2: id 0x42, from TCM, to CPC DRVU ECM, frame-length=8, can-addressing-mode=STANDARD
        pdu TCM_WDC_Data_AR2: length=64, unused-bit-pattern=0, cyclic-timing={repeating-time=0.01, starting-time=0.0}
          signal Converter_TempCritic: start 48, 1 bit, little-endian, data-type=DC_BOOL, init-value=XDIS_h5tcyk98kzbgrc5svasomeyt/lfalse, to CPC DRVU(timeout 0.105 s) ECM  # Wandler: Temperatur kritisch / Converter: Temperature critical
          signal CRC_TCM_WDC_Data_Pr2: start 0, 8 bit, little-endian, data-type=c08_CRC_woSNA, init-value=l243, to CPC DRVU(timeout 0.105 s) ECM  # CRC-Checksumme der Signal Gruppe gemäß AUTOSAR Profil 2 / CRC-checksum of signal group according to AUTOSAR Profile 2
          signal DrvAccelMax_Stat: start 14, 2 bit, little-endian, data-type=c02_Off_Enbl_Actv, init-value=XDIS_67um0ctsifexegftsp97takil/lOFF, to CPC DRVU(timeout 0.105 s) ECM  # Status anfahren mit maximaler Beschleunigung (Race Start nur AMG) / Driveaway with maximum acceleration state (Race Start only AMG)
          signal EngTrqMax_WDC_Rq_TCM: start 12, 1 bit, little-endian, data-type=DC_BOOL, init-value=XDIS_h5tcyk98kzbgrc5svasomeyt/lfalse, to CPC DRVU(timeout 0.105 s) ECM  # Anforderung maximierender Eingriff / Maximize Engine torque request
          signal EngTrqMin_WDC_Rq_TCM: start 13, 1 bit, little-endian, data-type=DC_BOOL, init-value=XDIS_h5tcyk98kzbgrc5svasomeyt/lfalse, to CPC DRVU(timeout 0.105 s) ECM  # Anforderung minimierender Eingriff / Minimize Engine torque request
          signal EngTrqWDC_Rq_TCM_V2: start 32, 11 bit, little-endian, data-type=c11_Nm_m500_1546k0_1k0, init-value=XDIS_c1d4l3fliyrryv1w2ncd3uiy6/l2047, to CPC DRVU(timeout 0.105 s) ECM  # Sollmoment am Eingang des Anfahrelementes vom TCM / Engine Torque Wet driveaway clutch request from TCM
          signal SQC_TCM_WDC_Data_Pr2: start 8, 4 bit, little-endian, data-type=c04_0_15_1_SNA_na, init-value=XDIS_2gdok7is6uk227cngmpgf9wxb/l0, to CPC DRVU(timeout 0.105 s) ECM  # Sequenzzähler / Sequence counter
          signal TCC_TempCritic: start 47, 1 bit, little-endian, data-type=DC_BOOL, init-value=XDIS_h5tcyk98kzbgrc5svasomeyt/lfalse, to CPC DRVU(timeout 0.105 s) ECM  # Wandlerüberbrückungskupplung: Temperatur kritisch / torque converter lockup clutch: Temperature critical
          signal TxSlp_Stat: start 27, 2 bit, little-endian, data-type=c02_TxSlp_Stat, init-value=XDIS_4ld9eknd9hbtp85sn1cgsehjf/l3, to CPC DRVU(timeout 0.105 s) ECM  # Getriebe Schlupfanforderungsstatus / Transmission Slip request state
          signal VehCreep_Actv: start 49, 1 bit, little-endian, data-type=DC_BOOL, init-value=XDIS_h5tcyk98kzbgrc5svasomeyt/lfalse, to CPC DRVU(timeout 0.105 s) ECM  # Fahrzeug kriecht / Vehicle is creeping
          signal WDC_IntrvntnMd_TCM: start 29, 2 bit, little-endian, data-type=c02_WDC_IntrvntnMd_TCM, init-value=XDIS_10vorrxz282yylz1thjvk5dvx/lMFC, to CPC DRVU(timeout 0.105 s) ECM  # Anforderung Getriebe Intervention / Wet driveaway Intervention mode
          signal WDC_Stat: start 43, 4 bit, little-endian, data-type=c04_WDC_Stat, init-value=XDIS_6n8ah31u6sz3w1m3lpg434vip/l15, to CPC DRVU(timeout 0.105 s) ECM  # Nasser Fahrweg Kupplungsfunktionsstatus / Wet driveaway clutch function status
          signal WDC_TempCritic: start 31, 1 bit, little-endian, data-type=DC_BOOL, init-value=XDIS_h5tcyk98kzbgrc5svasomeyt/lfalse, to CPC DRVU(timeout 0.105 s) ECM  # Temperatur der Trennkupplung kritisch / Temperature of separating clutch critical
          signal WDC_Trq_V2: start 16, 11 bit, little-endian, data-type=c11_Nm_m500_1546k0_1k0, init-value=XDIS_c1d4l3fliyrryv1w2ncd3uiy6/l2047, to CPC DRVU(timeout 0.105 s) ECM  # Aktuelles Drehmoment nasse Anfahrkupplung / Actual wet driveaway clutch torque
          signal WDC_TrqPreCtrl: start 56, 8 bit, little-endian, data-type=c08_Nm_0_254_1, init-value=XDIS_atdfawq2fo29xmbv147hlg3xp/l255, to CPC DRVU(timeout 0.105 s) ECM  # Vorsteuermoment nasse Anfahrkupplung (0h = passiv)/ Wandlerpumpenmoment / Wet driveaway clutch pre-control torque (0h = passive)/ Wandlerpumpenmoment
          signal Rsrv3_TCM_WDC_Data_Pr2: start 50, 6 bit, little-endian, data-type=Rsrv06, init-value=XDIS_zukcixzhzplmgdoo03mopm29/l0, to CPC DRVU ECM  # Reserviert für zukünftige Verwendung / Reserved for future use
          signal TCM_WDC_Data_Pr2_cdb1pod9rsur54rd7agdaayel: little-endian, system-signal=[Converter_TempCritic, CRC_TCM_WDC_Data_Pr2, DrvAccelMax_Stat, EngTrqMax_WDC_Rq_TCM, EngTrqMin_WDC_Rq_TCM, EngTrqWDC_Rq_TCM_V2, Rsrv3_TCM_WDC_Data_Pr2, SQC_TCM_WDC_Data_Pr2, TCC_TempCritic, TxSlp_Stat, VehCreep_Actv, WDC_IntrvntnMd_TCM, WDC_Stat, WDC_TempCritic, WDC_Trq_V2, WDC_TrqPreCtrl], transfer-property=PENDING, to CPC DRVU(timeout 0.105 s) ECM  # TCM_WDC_Data_Pr2 (degraded)
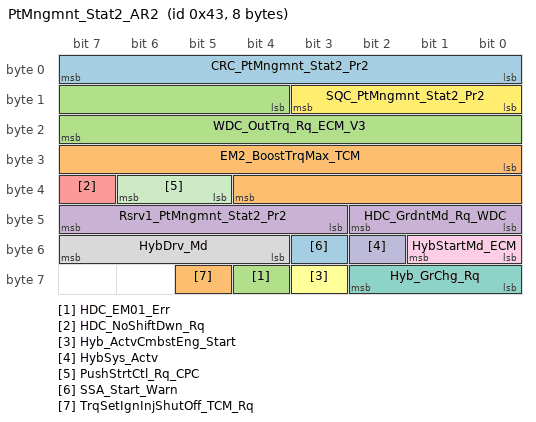
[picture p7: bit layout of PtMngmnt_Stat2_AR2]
      frame PtMngmnt_Stat2_AR2: id 0x43, from CPC, to ECM TCM, frame-length=8, can-addressing-mode=STANDARD  # Powertrain Management Status #2 / Powertrain Management State 2
        pdu PtMngmnt_Stat2_AR2: length=64, unused-bit-pattern=0, cyclic-timing={repeating-time=0.01, starting-time=0.0050}  # Powertrain Management Status #2 / Powertrain Management State 2
          signal CRC_PtMngmnt_Stat2_Pr2: start 0, 8 bit, little-endian, data-type=c08_CRC_woSNA, init-value=l239, to TCM  # CRC-Checksumme der Signal Gruppe gemäß AUTOSAR Profil 2 / CRC-checksum of signal group according to AUTOSAR Profile 2
          signal EM2_BoostTrqMax_TCM: start 24, 13 bit, little-endian, data-type=c13_Nm_m500_1547k5_0k25, init-value=XDIS_emg3258s4xg6nj4415gnzzldg/l8191, to TCM  # Max. Elektischer Boost E-Maschine 2 / Maximum electric maschine #2 boost torque
          signal HDC_EM01_Err: start 60, 1 bit, little-endian, data-type=c01_Ok_Flt_EM01, init-value=XDIS_8bnock8yflgyavdtylluepc9l/lOK, transfer-property=PENDING, to ECM TCM  # Fehlerstatus der E-Maschine / Error on EM01
          signal HDC_GrdntMd_Rq_WDC: start 40, 3 bit, little-endian, data-type=c03_HDC_GrdntMd_Rq_WDC, init-value=XDIS_blyfc6j17ckx0dleyticlsaev/l7, to TCM  # Gradient mode request for wet disengaging clutch
          signal HDC_NoShiftDwn_Rq: start 39, 1 bit, little-endian, data-type=DC_BOOL, init-value=XDIS_h5tcyk98kzbgrc5svasomeyt/lfalse, to TCM  # Unterdrückung Rückschaltung / HDC no shift down request
          signal Hyb_ActvCmbstEng_Start: start 59, 1 bit, little-endian, data-type=DC_BOOL, init-value=XDIS_h5tcyk98kzbgrc5svasomeyt/lfalse, transfer-property=PENDING, to TCM  # Aktiver Verbrennungsmotorstart / Active combustion engine start
          signal Hyb_GrChg_Rq: start 56, 3 bit, little-endian, data-type=c03_Hyb_GrChg_Rq, init-value=XDIS_cc0dp8n5jytppo4a8e0x313gy/lIDLE, transfer-property=PENDING, to TCM  # Hybrid System Gangwechsel Anforderung / Hybrid system requires change of gears
          signal HybDrv_Md: start 52, 4 bit, little-endian, data-type=c04_HybDrv_Md, init-value=lLOAD_VOLT_REG, transfer-property=PENDING, to TCM  # Hybrid-Modus / Hybrid driving mode
          signal HybStartMd_ECM: start 48, 2 bit, little-endian, data-type=c02_HybStartMd, init-value=lSTARTER_ST, transfer-property=PENDING, to ECM TCM  # Hybrid Start Mode
          signal HybSys_Actv: start 50, 1 bit, little-endian, data-type=DC_BOOL, init-value=XDIS_h5tcyk98kzbgrc5svasomeyt/lfalse, transfer-property=PENDING, to TCM  # Hybrid-System aktiv / Hybrid system active
          signal PushStrtCtl_Rq_CPC: start 37, 2 bit, little-endian, data-type=c02_PushStrtCtl_Rq_ECM, init-value=XDIS_zz0bvoayey7hxgtzjt8dx3ui/lPASSIVE, to TCM  # Anforderung und Status Anschiebestart
          signal SQC_PtMngmnt_Stat2_Pr2: start 8, 4 bit, little-endian, data-type=c04_0_15_1_SNA_na, init-value=XDIS_2gdok7is6uk227cngmpgf9wxb/l0, to TCM  # Sequenzzähler / Sequence counter
          signal SSA_Start_Warn: start 51, 1 bit, little-endian, data-type=DC_BOOL, init-value=XDIS_h5tcyk98kzbgrc5svasomeyt/lfalse, transfer-property=PENDING, to ECM TCM  # ASS Vorwarnung Motorstart / Stop/Start automatic announcing coming automatic start
          signal TrqSetIgnInjShutOff_TCM_Rq: start 61, 1 bit, little-endian, data-type=c01_FalseTrue, init-value=XDIS_2iashc329dzvn51tf3v4nxcs8/lFALSE, transfer-property=PENDING, to ECM TCM  # Anforderung Momenteneinstellung über Kraftstoffausblendung vom TCm / torque setting ignition with injection shutoff from TCM
          signal WDC_OutTrq_Rq_ECM_V3: start 12, 12 bit, little-endian, data-type=c12_Nm_m500_1547k5_0k5, init-value=XDIS_eoa5ig83h5a3fm98rgipqj3hz/l4095, to TCM  # Anforderung Ausgangsdrehmoment nasse Anfahrkupplung / Wet driveaway clutch output torque request
          signal Rsrv1_PtMngmnt_Stat2_Pr2: start 43, 5 bit, little-endian, data-type=Rsrv05, init-value=XDIS_e6yko3jf7vueybb3pnb685vj8/l0, to ECM TCM  # Reserviert für zukünftige Verwendung / Reserved for future use
          signal PtMngmnt_Stat2_Pr2_52pi4z2we5iyfdnzwhqxb6f78: little-endian, system-signal=[CRC_PtMngmnt_Stat2_Pr2, EM2_BoostTrqMax_TCM, HDC_GrdntMd_Rq_WDC, HDC_NoShiftDwn_Rq, PushStrtCtl_Rq_CPC, Rsrv1_PtMngmnt_Stat2_Pr2, SQC_PtMngmnt_Stat2_Pr2, WDC_OutTrq_Rq_ECM_V3], transfer-property=PENDING, to TCM  # Powertrain Management Status #2 (degraded) / Powertrain Management State 2 (degraded)
      frame TCM_EngIntrvntn_AR2: id 0x4B, from TCM, to ASX CPC DRVU ECM TGW, frame-length=8, can-addressing-mode=STANDARD
        pdu TCM_EngIntrvntn_AR2: length=64, unused-bit-pattern=0, cyclic-timing={repeating-time=0.01, starting-time=0.01}
          signal BrkRq_TCM: start 56, 2 bit, little-endian, data-type=c02_brkrq_tcm, init-value=XDIS_rtkpsgicnvz0wz7o7glhec19/lIDLE, to ASX(timeout 0.105 s) CPC DRVU(timeout 0.105 s) ECM TGW(timeout 0.105 s)  # Anforderung Bremsmoment / Brake moment request
          signal CRC_TCM_EngIntrvntn_Pr2: start 0, 8 bit, little-endian, data-type=c08_CRC_woSNA, init-value=l196, to ASX(timeout 0.105 s) CPC DRVU(timeout 0.105 s) ECM TGW(timeout 0.105 s)  # CRC-Checksumme der Signal Gruppe gemäß AUTOSAR Profil 2 / CRC-checksum of signal group according to AUTOSAR Profile 2
          signal EngRPM_Ctrl_Rq: start 60, 2 bit, little-endian, data-type=c02_SpdCtrl_Rq, init-value=XDIS_81noapvlbj6bhwcisaskiut23/l3, to ASX(timeout 0.105 s) CPC DRVU(timeout 0.105 s) ECM TGW(timeout 0.105 s)  # Anforderung Motordrehzahlstrategie / engine rpm control strategy request
          signal EngRPM_Rq_TCM: start 40, 12 bit, little-endian, data-type=c12_rpm_0_8188_2, init-value=XDIS_dd6txh2gockdf2ckmql7drv7h/l4095, to ASX(timeout 0.105 s) CPC DRVU(timeout 0.105 s) ECM TGW(timeout 0.105 s)  # Soll-Drehzahl Motor / Engine rpm request
          signal EngSt_Enbl_Rq_TCM: start 31, 1 bit, little-endian, data-type=DC_BOOL, init-value=XDIS_h5tcyk98kzbgrc5svasomeyt/lfalse, to ASX(timeout 0.105 s) CPC DRVU(timeout 0.105 s) ECM TGW(timeout 0.105 s)  # Anlassfreigabe Getriebe / Enable engine start request
          signal EngTrq_Rq_TCM_V2: start 16, 11 bit, little-endian, data-type=c11_Nm_m500_1546k0_1k0, init-value=XDIS_c1d4l3fliyrryv1w2ncd3uiy6/l2047, to ASX(timeout 0.105 s) CPC DRVU(timeout 0.105 s) ECM TGW(timeout 0.105 s)  # Geford. Motormoment / DCT: Momentanforderung des Getriebes (obere Grenze) / Engine torque request / DCT: Gear torque request (upper limit)
          signal EngTrqMax_Rq_TCM: start 29, 1 bit, little-endian, data-type=DC_BOOL, init-value=XDIS_h5tcyk98kzbgrc5svasomeyt/lfalse, to ASX(timeout 0.105 s) CPC DRVU(timeout 0.105 s) ECM TGW(timeout 0.105 s)  # Motormomentenanforderung Max / Engine torque request maximum; 451ev: OnBoard Charger Proximity Detect
          signal EngTrqMin_Rq_TCM: start 30, 1 bit, little-endian, data-type=DC_BOOL, init-value=XDIS_h5tcyk98kzbgrc5svasomeyt/lfalse, to ASX(timeout 0.105 s) CPC DRVU(timeout 0.105 s) ECM TGW(timeout 0.105 s)  # Motormomentenanforderung Min / Engine torque request minimum
          signal IntrvntnMd_TCM: start 12, 2 bit, little-endian, data-type=c02_IntrvntnMd, init-value=XDIS_bjcgahg6rsx9xrvjh2w4f04lk/lMFC, to ASX(timeout 0.105 s) CPC DRVU(timeout 0.105 s) ECM TGW(timeout 0.105 s)  # Eingriffsmodus / Intervention mode
          signal SQC_TCM_EngIntrvntn_Pr2: start 8, 4 bit, little-endian, data-type=c04_0_15_1_SNA_na, init-value=XDIS_2gdok7is6uk227cngmpgf9wxb/l0, to ASX(timeout 0.105 s) CPC DRVU(timeout 0.105 s) ECM TGW(timeout 0.105 s)  # Sequenzzähler / Sequence counter
          signal SSA_Clutch_Stat: start 14, 2 bit, little-endian, data-type=c02_SSA_Clutch_Stat, init-value=XDIS_5p2inx1jl8ttoognylk9cabtm/lDSABL, to ASX(timeout 0.105 s) CPC DRVU(timeout 0.105 s) ECM TGW(timeout 0.105 s)  # Status (Wandlerüberbrückungs-) Kupplung für Stopp/Start-Automatik (Überwachungsebene) / State (torque converter lockup) clutch for Stop/Start Automatic (monitor layer)
          signal TC_Trq: start 32, 8 bit, little-endian, data-type=c08_Nm_m275_p1000_5, init-value=XDIS_7wl5gcuj8x65uixr208rp9qno/l255, to ASX(timeout 0.105 s) CPC DRVU(timeout 0.105 s) ECM TGW(timeout 0.105 s)  # Istmoment
          signal TccPushStrtCtl_TCM: start 62, 2 bit, little-endian, data-type=c02_TccPushStrtCtl_TCM, init-value=XDIS_8tt52gotd7sah7r3hmwlwejm1/lPASSIVE, to ASX(timeout 0.105 s) CPC DRVU(timeout 0.105 s) ECM TGW(timeout 0.105 s)  # Anforderung und Status Anschiebestart
          signal Tx_Safe_Cls: start 59, 1 bit, little-endian, data-type=DC_BOOL, init-value=XDIS_h5tcyk98kzbgrc5svasomeyt/lfalse, to ASX(timeout 0.105 s) CPC DRVU(timeout 0.105 s) ECM TGW(timeout 0.105 s)  # Getriebe befindet sich in einem sicheren Zustand wenn B2- und B3-Kupplung geschlossen ist. / Gear is under safe condition. if B2 and B3 drive coupling is closed
          signal TxHybDrvMd_Sync_Actv: start 27, 1 bit, little-endian, data-type=DC_BOOL, init-value=XDIS_h5tcyk98kzbgrc5svasomeyt/lfalse, to ASX(timeout 0.105 s) CPC DRVU(timeout 0.105 s) ECM TGW(timeout 0.105 s)  # Getriebe-Hybridmod Synchronisation aktiv / Transmission hybrid driving mode synchronisation active
          signal TxHybDrvMd_V2: start 52, 4 bit, little-endian, data-type=c04_TxHybMd_V2, init-value=XDIS_5s8u596gzgg1jcia3zb9rgy8b/l15, to ASX(timeout 0.105 s) CPC DRVU(timeout 0.105 s) ECM TGW(timeout 0.105 s)  # Getriebe-Hybridmodus / Transmission hybrid driving mode
          signal TxOutRPM_Plaus: start 58, 1 bit, little-endian, data-type=DC_BOOL, init-value=XDIS_h5tcyk98kzbgrc5svasomeyt/lfalse, to ASX(timeout 0.105 s) CPC DRVU(timeout 0.105 s) ECM TGW(timeout 0.105 s)  # Plausibilisierung der Getriebeausgangsdrehzahl bestanden / Transmission output RPM plausible
          signal WDC_Boost_Dsabl: start 28, 1 bit, little-endian, data-type=DC_BOOL, init-value=XDIS_h5tcyk98kzbgrc5svasomeyt/lfalse, to ASX(timeout 0.105 s) CPC DRVU(timeout 0.105 s) ECM TGW(timeout 0.105 s)  # Boost deaktiviert für Getriebe Intervention / Boost disable for wet driveaway clutch protection
          signal TCM_EngIntrvntn_Pr2_3yr5mxltfyr8h8xlszlge0nzx: little-endian, system-signal=[BrkRq_TCM, CRC_TCM_EngIntrvntn_Pr2, EngRPM_Ctrl_Rq, EngRPM_Rq_TCM, EngSt_Enbl_Rq_TCM, EngTrq_Rq_TCM_V2, EngTrqMax_Rq_TCM, EngTrqMin_Rq_TCM, IntrvntnMd_TCM, SQC_TCM_EngIntrvntn_Pr2, SSA_Clutch_Stat, TC_Trq, TccPushStrtCtl_TCM, Tx_Safe_Cls, TxHybDrvMd_Sync_Actv, TxHybDrvMd_V2, TxOutRPM_Plaus, WDC_Boost_Dsabl], transfer-property=PENDING, to ASX(timeout 0.105 s) CPC DRVU(timeout 0.105 s) ECM TGW(timeout 0.105 s)  # TCM Engine Intervention Signalgroup (degraded)
      frame Eng_Rs4_AR2: id 0x4C, from ECM, to CPC TCM, frame-length=8, can-addressing-mode=STANDARD  # Eng Rs4 A R2
        pdu Eng_Rs4_AR2: length=64, unused-bit-pattern=0, cyclic-timing={repeating-time=0.01, starting-time=0.0}  # Eng Rs4 A R2
          signal CRC_Eng_Rs4_Pr2: start 0, 8 bit, little-endian, data-type=c08_CRC_woSNA, init-value=l70, to CPC TCM  # CRC-Checksumme der Signal Gruppe gemäß AUTOSAR Profil 2 / CRC-checksum of signal group according to AUTOSAR Profile 2
          signal EngTrq_DynOffset: start 23, 11 bit, little-endian, data-type=c11_Nm_m500_1546k0_1k0, init-value=XDIS_60vl5omr41k0bd97hj1xlgn6g/l0, to CPC TCM  # Motor - Drehmoment - Dynamikanteil / Engine - Torque - dynamic offset
          signal EngTrqMinDyn_TTC: start 12, 11 bit, little-endian, data-type=c11_Nm_m500_1546k0_1k0, init-value=XDIS_c1d4l3fliyrryv1w2ncd3uiy6/l2047, to CPC TCM  # Motormoment bei ZW_Min Wirkungsgrad / Engine torque at ZW_Min effectiveness
          signal SQC_Eng_Rs4_Pr2: start 8, 4 bit, little-endian, data-type=c04_0_15_1_SNA_na, init-value=XDIS_2gdok7is6uk227cngmpgf9wxb/l0, to CPC TCM  # Sequenzzähler / Sequence counter
          signal Rsrv0_Eng_Rs4_Pr2: start 34, 14 bit, little-endian, data-type=Rsrv14, init-value=XDIS_ei6iywhjasod43zzayamrf7c3/l0, to CPC TCM  # Reserviert für zukünftige Verwendung / Reserved for future use
          signal Rsrv1_Eng_Rs4_Pr2: start 48, 16 bit, little-endian, data-type=Rsrv16, init-value=XDIS_dn8lf2t3vtro1vkmqfxqg05qy/l0, to CPC TCM  # Reserviert für zukünftige Verwendung / Reserved for future use
          signal Eng_Rs4_Pr2_dg8les6g8bd4zh1pem3ucc29t: little-endian, system-signal=[CRC_Eng_Rs4_Pr2, EngTrq_DynOffset, EngTrqMinDyn_TTC, Rsrv0_Eng_Rs4_Pr2, Rsrv1_Eng_Rs4_Pr2, SQC_Eng_Rs4_Pr2], transfer-property=PENDING, to CPC TCM  # Motoransprechverhalten 4 (degraded) / Engine response 4 (degraded)
      frame FBL_CFG_Star2_AR: id 0x68, from CPC, to ECM, frame-length=1, can-addressing-mode=STANDARD
        pdu FBL_Cfg_Star2_AR: length=8, unused-bit-pattern=0, cyclic-timing=repeating-time=0.2  # FBL Konfigurationsinfo für Star2 / FBL configuration info for Star2
          signal Platform_Stat_Star2: start 0, 8 bit, little-endian, data-type=c08_Platform_Stat, init-value=lSTAR2, transfer-property=PENDING, to ECM  # Plattformstatus / Platform state
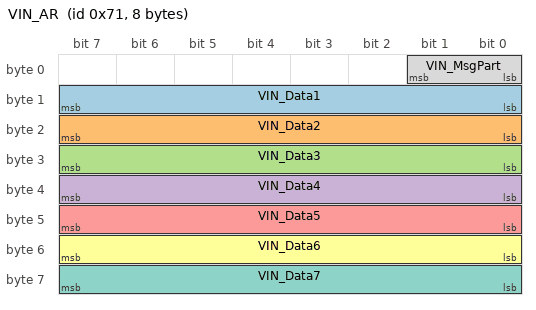
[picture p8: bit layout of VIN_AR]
      frame VIN_AR: id 0x71, from CPC, to ASX FSCM TCM, frame-length=8, can-addressing-mode=STANDARD  # Vehicle Identification Number
        pdu VIN_AR: length=64, unused-bit-pattern=0, event-controlled-timing=number-of-repeats=0, minimum-delay=0.01  # Vehicle Identification Number
          signal VIN_Data1: start 8, 8 bit, little-endian, data-type=c08_UInt_SNA_na, init-value=XDIS_924qw6koy0pgxo1lr9qanbbdz/l255, to ASX FSCM TCM  # VIN Signalteil-Daten / VIN digits (8 bit ascii encoded)
          signal VIN_Data2: start 16, 8 bit, little-endian, data-type=c08_UInt_SNA_na, init-value=XDIS_924qw6koy0pgxo1lr9qanbbdz/l255, to ASX FSCM TCM  # VIN Signalteil-Daten / VIN digits (8 bit ascii encoded)
          signal VIN_Data3: start 24, 8 bit, little-endian, data-type=c08_UInt_SNA_na, init-value=XDIS_924qw6koy0pgxo1lr9qanbbdz/l255, to ASX FSCM TCM  # VIN Signalteil-Daten / VIN digits (8 bit ascii encoded)
          signal VIN_Data4: start 32, 8 bit, little-endian, data-type=c08_UInt_SNA_na, init-value=XDIS_924qw6koy0pgxo1lr9qanbbdz/l255, to ASX FSCM TCM  # VIN Signalteil-Daten / VIN digits (8 bit ascii encoded)
          signal VIN_Data5: start 40, 8 bit, little-endian, data-type=c08_UInt_SNA_na, init-value=XDIS_924qw6koy0pgxo1lr9qanbbdz/l255, to ASX FSCM TCM  # VIN Signalteil-Daten / VIN digits (8 bit ascii encoded)
          signal VIN_Data6: start 48, 8 bit, little-endian, data-type=c08_UInt_SNA_na, init-value=XDIS_924qw6koy0pgxo1lr9qanbbdz/l255, to ASX FSCM TCM  # VIN Signalteil-Daten / VIN digits (8 bit ascii encoded)
          signal VIN_Data7: start 56, 8 bit, little-endian, data-type=c08_UInt_SNA_na, init-value=XDIS_924qw6koy0pgxo1lr9qanbbdz/l255, to ASX FSCM TCM  # VIN Signalteil-Daten / VIN digits (8 bit ascii encoded)
          signal VIN_MsgPart: start 0, 2 bit, little-endian, data-type=c02_VIN, init-value=XDIS_b2vio5hx9hk9i8xkusx6f9nkf/l3, to ASX FSCM TCM  # VIN Signalteil-Nummer / VIN message part
          signal VIN_401s6nk38eqdoqdeo893qnj2y: little-endian, system-signal=[VIN_Data1, VIN_Data2, VIN_Data3, VIN_Data4, VIN_Data5, VIN_Data6, VIN_Data7, VIN_MsgPart], transfer-property=TRIGGERED, to ASX FSCM TCM  # Fahrzeug-Identnummer (degraded) / Vehicle Identification Number (degraded)
      frame BrkSys_Stat_AR2: id 0x87, from CPC, to ECM FFAP_STAR_2 ISM TCM, frame-length=8, can-addressing-mode=STANDARD
        pdu BrkSys_Stat_AR2: length=64, unused-bit-pattern=0, cyclic-timing=repeating-time=0.02  # Status Bremssystem / Brake system state
          signal Brk_Stat: start 12, 2 bit, little-endian, data-type=c02_Brk_Stat, init-value=XDIS_8z0kx9i590v6kt4gu7vxxhvcm/l3, to ECM FFAP_STAR_2 ISM TCM  # Status Bremse / Brake state
          signal BrkIntrvntn_Actv_AS: start 57, 1 bit, little-endian, data-type=DC_BOOL, init-value=XDIS_h5tcyk98kzbgrc5svasomeyt/lfalse, to ECM FFAP_STAR_2 ISM TCM  # Assistenzsystem-Bremseneingriff aktiv / Brake intervention by assistance system active
          signal BrkIntrvntn_Actv_CWA: start 55, 1 bit, little-endian, data-type=DC_BOOL, init-value=XDIS_h5tcyk98kzbgrc5svasomeyt/lfalse, to ECM FFAP_STAR_2 ISM TCM  # Seitenwindassistent-Bremseneingriff aktiv / Crosswind assist brake intervention active
          signal BrkIntrvntn_Actv_EPKB: start 58, 1 bit, little-endian, data-type=DC_BOOL, init-value=XDIS_h5tcyk98kzbgrc5svasomeyt/lfalse, to ECM FFAP_STAR_2 ISM TCM  # EPKB-Bremseneingriff aktiv / Brake intervention by EPKB active
          signal BrkIntrvntn_Actv_ESP: start 56, 1 bit, little-endian, data-type=DC_BOOL, init-value=XDIS_h5tcyk98kzbgrc5svasomeyt/lfalse, to ECM FFAP_STAR_2 ISM TCM  # ESP-Bremseneingriff aktiv / Brake intervention by ESP active
          signal BrkPdl_Stat: start 14, 2 bit, little-endian, data-type=c02_Pdl_Stat, init-value=XDIS_4qu7eufkaqbzjiqze2el5aejn/l3, to ECM FFAP_STAR_2 ISM TCM  # Status Bremspedal / Brake pedal state
          signal BrkRq_PT_Enbl: start 46, 2 bit, little-endian, data-type=c02_BrkRq_PT_Enbl, init-value=lTHS_DSABL, to ECM FFAP_STAR_2 ISM TCM  # Umsetzung der Anforderung für aktives Bremsmoment durch RBS möglich. / Brake request by powertrain enabled
          signal BrkTrq_D_V2: start 32, 13 bit, little-endian, data-type=c13_Nm_0_24570_3, init-value=XDIS_dzq15i09jdpilg2seasjx6evl/l8191, to ECM FFAP_STAR_2 ISM TCM  # Vom Fahrer angefordertes Bremsmoment / Brake torque requested by driver
          signal BrkTrq_V2: start 16, 13 bit, little-endian, data-type=c13_Nm_0_24570_3, init-value=XDIS_dzq15i09jdpilg2seasjx6evl/l8191, to ECM FFAP_STAR_2 ISM TCM  # Eingestelltes Bremsmoment der Betriebsbremse (d.h. ohne Bremsmoment der E-Maschine) / Actual driving brake torque (i.e. without brake torque of electrical machine)
          signal CRC_BrkSys_Stat_Pr2: start 0, 8 bit, little-endian, data-type=c08_CRC_woSNA, init-value=l16, to ECM FFAP_STAR_2 ISM TCM  # CRC-Checksumme der Signal Gruppe gemäß AUTOSAR Profil 2 / CRC-checksum of signal group according to AUTOSAR Profile 2
          signal DSR_Actv: start 62, 1 bit, little-endian, data-type=DC_BOOL, init-value=XDIS_h5tcyk98kzbgrc5svasomeyt/lfalse, to ECM FFAP_STAR_2 ISM TCM  # Downhill Speed Regulation aktiv / Downhill speed regulation active
          signal DSR_Sys_Flt: start 63, 1 bit, little-endian, data-type=DC_BOOL, init-value=XDIS_h5tcyk98kzbgrc5svasomeyt/lfalse, to ECM FFAP_STAR_2 ISM TCM  # Systemfehler Downhill Speed Regulation / Downhill speed regulation system fault
          signal EmgBrk_Actv: start 30, 1 bit, little-endian, data-type=DC_BOOL, init-value=XDIS_h5tcyk98kzbgrc5svasomeyt/lfalse, to ECM FFAP_STAR_2 ISM TCM  # Notbremsung / Emergency braking
          signal ESP_Oprtn_Stat_AS_V2: start 48, 4 bit, little-endian, data-type=c04_ESP_Oprtn_Stat_AS_V2, init-value=XDIS_eazlpb63im4v75gekmzelypm9/lNORM, to ECM FFAP_STAR_2 ISM TCM  # Betriebszustand ESP für Assistenzsysteme / ESP operation state for assistance systems
          signal ESP_Sys_Stat_V2: start 52, 3 bit, little-endian, data-type=c03_ESP_Sys_Stat, init-value=XDIS_yx540jbnz7p1msygozw5vzp8/lNORM, to ECM FFAP_STAR_2 ISM TCM  # ESP Systemzustand / ESP system state
          signal FTW_PressDrop_Stat: start 59, 3 bit, little-endian, data-type=c03_FTW_PressDrop_Stat, init-value=XDIS_1hrjz35hano4wz5acruqrrcn7/l7, to ECM FFAP_STAR_2 ISM TCM  # Druckverlust-Status Plattrollwarner / Flat tire warning pressure drop state
          signal FullBrk_Actv: start 31, 1 bit, little-endian, data-type=DC_BOOL, init-value=XDIS_h5tcyk98kzbgrc5svasomeyt/lfalse, to ECM FFAP_STAR_2 ISM TCM  # Vollbremsung (ABS regelt alle 4 Räder) / Full braking (ABS regulates all wheels)
          signal SQC_BrkSys_Stat_Pr2: start 8, 4 bit, little-endian, data-type=c04_0_15_1_SNA_na, init-value=XDIS_2gdok7is6uk227cngmpgf9wxb/l0, to ECM FFAP_STAR_2 ISM TCM  # Sequenzzähler / Sequence counter
          signal SSA_EmgBrk_Actv: start 29, 1 bit, little-endian, data-type=DC_BOOL, init-value=XDIS_h5tcyk98kzbgrc5svasomeyt/lfalse, to ECM FFAP_STAR_2 ISM TCM  # Unterdrückung des automatischen Stopp wg. Notbremsung / Automatic stop inhibition due to emergency braking
          signal Rsrv5_BrkSys_Stat_Pr2: start 45, 1 bit, little-endian, data-type=Rsrv01, init-value=XDIS_e2uhxyvdu33zsyqfjnk549pp2/l0, to ECM FFAP_STAR_2 ISM TCM  # Reserviert für zukünftige Verwendung / Reserved for future use
          signal BrkSys_Stat_Pr2_7r9ilu941lyckw1hfocaygals: little-endian, system-signal=[Brk_Stat, BrkIntrvntn_Actv_AS, BrkIntrvntn_Actv_CWA, BrkIntrvntn_Actv_EPKB, BrkIntrvntn_Actv_ESP, BrkPdl_Stat, BrkRq_PT_Enbl, BrkTrq_D_V2, BrkTrq_V2, CRC_BrkSys_Stat_Pr2, DSR_Actv, DSR_Sys_Flt, EmgBrk_Actv, ESP_Oprtn_Stat_AS_V2, ESP_Sys_Stat_V2, FTW_PressDrop_Stat, FullBrk_Actv, Rsrv5_BrkSys_Stat_Pr2, SQC_BrkSys_Stat_Pr2, SSA_EmgBrk_Actv], transfer-property=PENDING, to ECM FFAP_STAR_2 ISM TCM  # Status Bremssystem (degraded) / Brake system state (degraded)
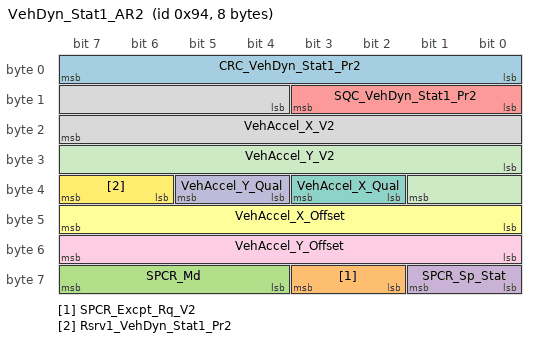
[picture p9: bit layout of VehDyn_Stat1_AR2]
      frame VehDyn_Stat1_AR2: id 0x94, from CPC, to ECM FSCM ISM TCM, frame-length=8, can-addressing-mode=STANDARD
        pdu VehDyn_Stat1_AR2: length=64, unused-bit-pattern=0, cyclic-timing={repeating-time=0.02, starting-time=0.0050}
          signal CRC_VehDyn_Stat1_Pr2: start 0, 8 bit, little-endian, data-type=c08_CRC_woSNA, init-value=l247, to ECM(timeout 0.205 s) FSCM(timeout 0.205 s) ISM(timeout 0.205 s) TCM(timeout 0.205 s)  # CRC-Checksumme der Signal Gruppe gemäß AUTOSAR Profil 2 / CRC-checksum of signal group according to AUTOSAR Profile 2
          signal SPCR_Excpt_Rq_V2: start 58, 2 bit, little-endian, data-type=c02_SPCR_Excpt_Rq_V2, init-value=lAS_ENBL, to ECM(timeout 0.205 s) FSCM(timeout 0.205 s) ISM(timeout 0.205 s) TCM(timeout 0.205 s)  # Stillstands-Koordinator Ausnahme-Anforderung / Stop coordinator exception request
          signal SPCR_Md: start 60, 4 bit, little-endian, data-type=c04_SPCR_Md, init-value=XDIS_evtq29vnc82ir0skkaa0j816s/lIDLE, to ECM(timeout 0.205 s) FSCM(timeout 0.205 s) ISM(timeout 0.205 s) TCM(timeout 0.205 s)  # Modus Stillstands-Koordinator / Stop coordinator mode
          signal SPCR_Sp_Stat: start 56, 2 bit, little-endian, data-type=c02_SPCR_Sp_Stat, init-value=XDIS_a0mnckcw51hoouji6de3yexpn/lIDLE, to ECM(timeout 0.205 s) FSCM(timeout 0.205 s) ISM(timeout 0.205 s) TCM(timeout 0.205 s)  # Status Stillstand / Stop coordinator stop state
          signal SQC_VehDyn_Stat1_Pr2: start 8, 4 bit, little-endian, data-type=c04_0_15_1_SNA_na, init-value=XDIS_2gdok7is6uk227cngmpgf9wxb/l0, to ECM(timeout 0.205 s) FSCM(timeout 0.205 s) ISM(timeout 0.205 s) TCM(timeout 0.205 s)  # Sequenzzähler / Sequence counter
          signal VehAccel_X_Offset: start 40, 8 bit, little-endian, data-type=c08_m_p_sq_s_m2k56_2k52_0k02, init-value=XDIS_3574ocltinkktr2wwgz9j67w1/l255, to ECM(timeout 0.205 s) FSCM(timeout 0.205 s) ISM(timeout 0.205 s) TCM(timeout 0.205 s)  # Offset der Fahrzeuglängsbeschleunigung (+ = vorwärts) / Offset of vehicle longitudinal acceleration (+ means forward)
          signal VehAccel_X_Qual: start 34, 2 bit, little-endian, data-type=c02_Signal_Qual, init-value=lELEC, to ECM(timeout 0.205 s) FSCM(timeout 0.205 s) ISM(timeout 0.205 s) TCM(timeout 0.205 s)  # Qualität der Fahrzeuglängsbeschleunigung / Quality of vehicle longitudinal acceleration
          signal VehAccel_X_V2: start 12, 12 bit, little-endian, data-type=c12_m_p_sq_s_m40d96_p40d92_0d02, init-value=XDIS_5e62jzeb2fc0ic26itktsmydt/l4095, to ECM(timeout 0.205 s) FSCM(timeout 0.205 s) ISM(timeout 0.205 s) TCM(timeout 0.205 s)  # Fahrzeuglängsbeschleunigung (+ = vorwärts) / Vehicle longitudinal acceleration (+ means forward)
          signal VehAccel_Y_Offset: start 48, 8 bit, little-endian, data-type=c08_m_p_sq_s_m2k56_2k52_0k02, init-value=XDIS_3574ocltinkktr2wwgz9j67w1/l255, to ECM(timeout 0.205 s) FSCM(timeout 0.205 s) ISM(timeout 0.205 s) TCM(timeout 0.205 s)  # Offset der Fahrzeugquerbeschleunigung im Schwerpunkt (+ = links) / Offset of vehicle lateral acceleration (+ means left)
          signal VehAccel_Y_Qual: start 36, 2 bit, little-endian, data-type=c02_Signal_Qual, init-value=lELEC, to ECM(timeout 0.205 s) FSCM(timeout 0.205 s) ISM(timeout 0.205 s) TCM(timeout 0.205 s)  # Qualität der Fahrzeugquerbeschleunigung / Quality of vehicle lateral acceleration
          signal VehAccel_Y_V2: start 24, 10 bit, little-endian, data-type=c10_m_p_sq_s_m10k24_p10k2_0k02, init-value=XDIS_drqm7m0w6ph9omeq6ml23fh7e/l1023, to ECM(timeout 0.205 s) FSCM(timeout 0.205 s) ISM(timeout 0.205 s) TCM(timeout 0.205 s)  # Fahrzeugquerbeschleunigung im Schwerpunkt (+ = links, Schwerpunkts-bezogen und Roll-korrigiert) / Vehicle lateral acceleration (+ means left, specific to center of gravity and roll corrected)
          signal Rsrv1_VehDyn_Stat1_Pr2: start 38, 2 bit, little-endian, data-type=Rsrv02, init-value=XDIS_7jeo5ges9wp8ufla3pohsuw83/l0, to ECM FSCM ISM TCM  # Reserviert für zukünftige Verwendung / Reserved for future use
          signal VehDyn_Stat1_Pr2_b566uuutl7t3vy8bytjwtuogy: little-endian, system-signal=[CRC_VehDyn_Stat1_Pr2, Rsrv1_VehDyn_Stat1_Pr2, SPCR_Excpt_Rq_V2, SPCR_Md, SPCR_Sp_Stat, SQC_VehDyn_Stat1_Pr2, VehAccel_X_Offset, VehAccel_X_Qual, VehAccel_X_V2, VehAccel_Y_Offset, VehAccel_Y_Qual, VehAccel_Y_V2], transfer-property=PENDING, to ECM(timeout 0.205 s) FSCM(timeout 0.205 s) ISM(timeout 0.205 s) TCM(timeout 0.205 s)  # Fahrdynamik-Status (degraded) / Vehicle dynamics state (degraded)
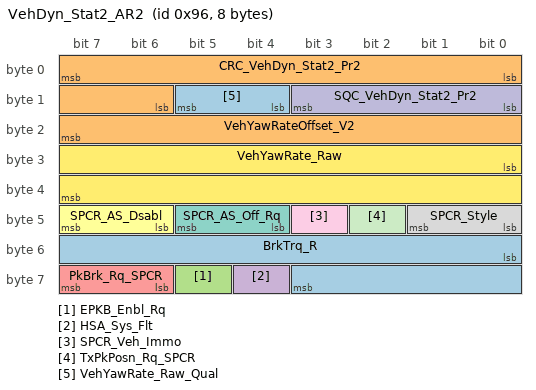
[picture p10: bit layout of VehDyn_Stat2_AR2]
      frame VehDyn_Stat2_AR2: id 0x96, from CPC, to ECM ISM TCM, frame-length=8, can-addressing-mode=STANDARD
        pdu VehDyn_Stat2_AR2: length=64, unused-bit-pattern=0, cyclic-timing={repeating-time=0.02, starting-time=0.01}
          signal BrkTrq_R: start 48, 12 bit, little-endian, data-type=c12_Nm_0_12282_3, init-value=XDIS_8lat4df4nlo7dz90hid6xl14r/l4095, to ECM ISM(timeout 0.205 s) TCM(timeout 0.205 s)  # Eingestelltes Bremsmoment Hinterachse (ohne Bremsmoment E-Maschine) / Actual brake torque rear axle (without brake torque of electrical machine)
          signal CRC_VehDyn_Stat2_Pr2: start 0, 8 bit, little-endian, data-type=c08_CRC_woSNA, init-value=l173, to ECM ISM(timeout 0.205 s) TCM(timeout 0.205 s)  # CRC-Checksumme der Signal Gruppe gemäß AUTOSAR Profil 2 / CRC-checksum of signal group according to AUTOSAR Profile 2
          signal EPKB_Enbl_Rq: start 61, 1 bit, little-endian, data-type=DC_BOOL, init-value=XDIS_h5tcyk98kzbgrc5svasomeyt/lfalse, to ECM ISM(timeout 0.205 s) TCM(timeout 0.205 s)  # Anforderung EPKB zulassen / Enable EPKB request
          signal HSA_Sys_Flt: start 60, 1 bit, little-endian, data-type=DC_BOOL, init-value=XDIS_h5tcyk98kzbgrc5svasomeyt/lfalse, to ECM ISM(timeout 0.205 s) TCM(timeout 0.205 s)  # Systemfehler Berganfahrhilfe / Hill start assist system fault
          signal PkBrk_Rq_SPCR: start 62, 2 bit, little-endian, data-type=c02_PkBrk_Rq_ESP, init-value=XDIS_zagt0434oztx3kr7c6elmean/lIDLE, to ECM ISM(timeout 0.205 s) TCM(timeout 0.205 s)  # Feststellbremsenanforderung / Parking brake request
          signal SPCR_AS_Dsabl: start 46, 2 bit, little-endian, data-type=c02_SPCR_AS_Dsabl, init-value=XDIS_6c0ho8dqug272cu2mxvfyusfu/lIDLE, to ECM ISM(timeout 0.205 s) TCM(timeout 0.205 s)  # Abschaltung Assistenzsystem / Disable assistance system
          signal SPCR_AS_Off_Rq: start 44, 2 bit, little-endian, data-type=c02_SPCR_AS_Off_Rq, init-value=XDIS_13ry15l7m1nqhgsb8pw451blv/lIDLE, to ECM ISM(timeout 0.205 s) TCM(timeout 0.205 s)  # Anforderung Assistenzsystem aus / Assistance system off request
          signal SPCR_Style: start 40, 2 bit, little-endian, data-type=c02_SPCR_Style, init-value=XDIS_ed014lb60hw74udh9elmget2z/l3, to ECM ISM(timeout 0.205 s) TCM(timeout 0.205 s)  # Stop Coordinator Style
          signal SPCR_Veh_Immo: start 43, 1 bit, little-endian, data-type=DC_BOOL, init-value=XDIS_h5tcyk98kzbgrc5svasomeyt/lfalse, to ECM ISM(timeout 0.205 s) TCM(timeout 0.205 s)  # Stillstands-Koordinator hat Fahrzeug gesichert / Vehicle immobilized by stop coordinator
          signal SQC_VehDyn_Stat2_Pr2: start 8, 4 bit, little-endian, data-type=c04_0_15_1_SNA_na, init-value=XDIS_2gdok7is6uk227cngmpgf9wxb/l0, to ECM ISM(timeout 0.205 s) TCM(timeout 0.205 s)  # Sequenzzähler / Sequence counter
          signal TxPkPosn_Rq_SPCR: start 42, 1 bit, little-endian, data-type=DC_BOOL, init-value=XDIS_h5tcyk98kzbgrc5svasomeyt/lfalse, to ECM ISM(timeout 0.205 s) TCM(timeout 0.205 s)  # SPCR-Wunsch: "P" einlegen / Transmission parking position request
          signal VehYawRate_Raw: start 24, 16 bit, little-endian, data-type=c16_deg_p_s_m327k68_327k66_0k01, init-value=XDIS_2ti1tb937zofciy7tyx78817u/l65535, to ECM ISM(timeout 0.205 s) TCM(timeout 0.205 s)  # Rohsignal Gierrate ohne Abgleich/Filterung (+ = links) / Vehicle yaw rate unfiltered/unadjusted (+ means left)
          signal VehYawRate_Raw_Qual: start 12, 2 bit, little-endian, data-type=c02_Signal_Qual, init-value=lELEC, to ECM ISM(timeout 0.205 s) TCM(timeout 0.205 s)  # Qualität des Rohsignals Gierrate ohne Abgleich/Filterung / Quality of Vehicle yaw rate unfiltered/unadjusted
          signal VehYawRateOffset_V2: start 14, 10 bit, little-endian, data-type=c10_deg_p_s_m5d12_p5d1_0d01, init-value=XDIS_9at492ayvc0eu41j1vsg7u9fh/l1023, to ECM ISM(timeout 0.205 s) TCM(timeout 0.205 s)  # Offset des Rohsignal Gierrate ohne Abgleich/Filterung (+ = links) / Offset of vehicle yaw rate unfiltered/unadjusted (+ means left)
          signal VehDyn_Stat2_Pr2_10f6ms25t3ycbau4qljpm984z: little-endian, system-signal=[BrkTrq_R, CRC_VehDyn_Stat2_Pr2, EPKB_Enbl_Rq, HSA_Sys_Flt, PkBrk_Rq_SPCR, SPCR_AS_Dsabl, SPCR_AS_Off_Rq, SPCR_Style, SPCR_Veh_Immo, SQC_VehDyn_Stat2_Pr2, TxPkPosn_Rq_SPCR, VehYawRate_Raw, VehYawRate_Raw_Qual, VehYawRateOffset_V2], transfer-property=PENDING, to ECM ISM(timeout 0.205 s) TCM(timeout 0.205 s)  # Fahrdynamik-Status (degraded) / Vehicle dynamics state (degraded)
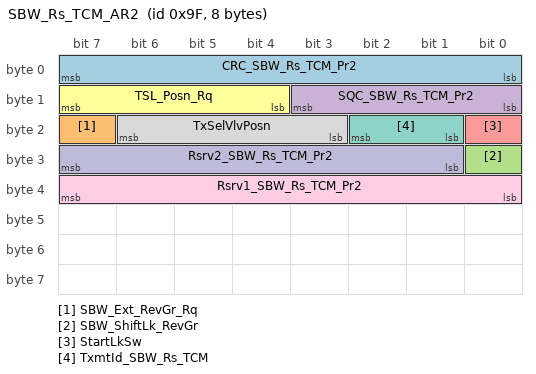
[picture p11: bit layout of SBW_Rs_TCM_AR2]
      frame SBW_Rs_TCM_AR2: id 0x9F, from TCM, to ISM, frame-length=8, can-addressing-mode=STANDARD
        pdu SBW_Resp_TCM_AR2: length=64, unused-bit-pattern=0, cyclic-timing={repeating-time=0.02, starting-time=0.02}, event-controlled-timing=number-of-repeats=0, minimum-delay=0.0050  # Shift by Wire Response TCM
          signal CRC_SBW_Rs_TCM_Pr2: start 0, 8 bit, little-endian, data-type=c08_CRC_woSNA, init-value=l245, transfer-property=PENDING, to ISM  # CRC-Checksumme der Signal Gruppe gemäß AUTOSAR Profil 2 / CRC-checksum of signal group according to AUTOSAR Profile 2
          signal SBW_Ext_RevGr_Rq: start 23, 1 bit, little-endian, data-type=DC_BOOL, init-value=XDIS_h5tcyk98kzbgrc5svasomeyt/lfalse, transfer-property=PENDING, to ISM  # SBW Externe Anforderung: Rückwärtsgang / SBW External Reverse Gear Request
          signal SBW_ShiftLk_RevGr: start 24, 1 bit, little-endian, data-type=DC_BOOL, init-value=XDIS_h5tcyk98kzbgrc5svasomeyt/lfalse, transfer-property=PENDING, to ISM  # SBW Schaltsperre Rückwärtsgang / SBW Encoding Shift-lock Reverse Gear
          signal SQC_SBW_Rs_TCM_Pr2: start 8, 4 bit, little-endian, data-type=c04_0_15_1_SNA_na, init-value=XDIS_2gdok7is6uk227cngmpgf9wxb/l0, transfer-property=PENDING, to ISM  # Sequenzzähler / Sequence counter
          signal StartLkSw: start 16, 1 bit, little-endian, data-type=DC_BOOL, init-value=XDIS_h5tcyk98kzbgrc5svasomeyt/lfalse, transfer-property=PENDING, to ISM  # Anlasssperrkontakt (nur bei EGS52) / Starter lockout switch (only EGS52)
          signal TSL_Posn_Rq: start 12, 4 bit, little-endian, data-type=c04_TSL_Posn_Rq, init-value=XDIS_d6tvoxnbt7llon5hsxajrlmsy/l15, transfer-property=PENDING, to ISM  # Anforderung Getriebewählhebelstellung / Transmission selector lever position request
          signal TxmtId_SBW_Rs_TCM: start 17, 2 bit, little-endian, data-type=c02_TxmtId_SBW_Rs_TCM, init-value=lVGS_NAG2, transfer-property=PENDING, to ISM  # Senderkennung / Transmitter identification
          signal TxSelVlvPosn: start 19, 4 bit, little-endian, data-type=c04_TxSelVlvPos_Actl, init-value=XDIS_8i34raomewkyeoeuimjig1t87/l15, transfer-property=TRIGGERED-ON-CHANGE, to ISM  # Iststellung Wählbereichsschieber im Getriebe / Actual position transmission selector valve
          signal Rsrv1_SBW_Rs_TCM_Pr2: start 32, 8 bit, little-endian, data-type=Rsrv08, init-value=XDIS_4flxbk4wkjkdew7cw07d9of66/l0, transfer-property=PENDING, to ISM  # Reserviert für zukünftige Verwendung / Reserved for future use
          signal Rsrv2_SBW_Rs_TCM_Pr2: start 25, 7 bit, little-endian, data-type=Rsrv07, init-value=XDIS_1uvqkcvexva3vp6bv7zoxjawg/l0, transfer-property=PENDING, to ISM  # Reserviert für zukünftige Verwendung / Reserved for future use
          signal SBW_Rs_TCM_Pr2_dym3b88zatlkmtnb9qcuvfn90: little-endian, system-signal=[CRC_SBW_Rs_TCM_Pr2, Rsrv1_SBW_Rs_TCM_Pr2, Rsrv2_SBW_Rs_TCM_Pr2, SBW_Ext_RevGr_Rq, SBW_ShiftLk_RevGr, SQC_SBW_Rs_TCM_Pr2, StartLkSw, TSL_Posn_Rq, TxmtId_SBW_Rs_TCM, TxSelVlvPosn], to ISM  # Shift by Wire Response TCM (degraded)
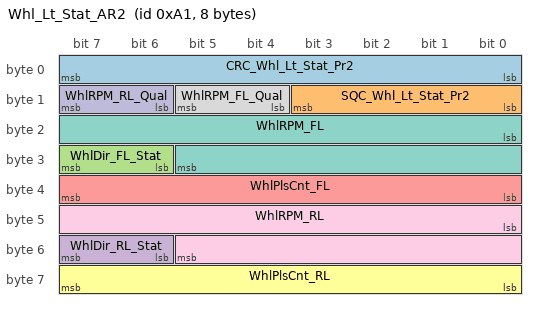
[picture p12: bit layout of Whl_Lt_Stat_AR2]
      frame Whl_Lt_Stat_AR2: id 0xA1, from CPC, to ECM ISM TCM, frame-length=8, can-addressing-mode=STANDARD  # Status Räder links / Left wheels state
        pdu Whl_Lt_Stat_AR2: length=64, unused-bit-pattern=0, cyclic-timing=repeating-time=0.02  # Status Räder links / Left wheels state
          signal CRC_Whl_Lt_Stat_Pr2: start 0, 8 bit, little-endian, data-type=c08_CRC_woSNA, init-value=XDIS_di356mmt5w3a9njzuhn01zxwt/l0, to ECM ISM TCM  # CRC-Checksumme der Signal Gruppe gemäß AUTOSAR Profil 2 / CRC-checksum of signal group according to AUTOSAR Profile 2
          signal SQC_Whl_Lt_Stat_Pr2: start 8, 4 bit, little-endian, data-type=c04_0_15_1_SNA_na, init-value=XDIS_2gdok7is6uk227cngmpgf9wxb/l0, to ECM ISM TCM  # Sequenzzähler / Sequence counter
          signal WhlDir_FL_Stat: start 30, 2 bit, little-endian, data-type=c02_WhlDir, init-value=XDIS_1qop2uga8u6pailb3xixw6g6t/l3, to ECM ISM TCM  # Drehrichtung Rad vorne links (SNA falls Senor nicht vorhanden) / Direction of rotation of front left wheel (SNA if sensor not present)
          signal WhlDir_RL_Stat: start 54, 2 bit, little-endian, data-type=c02_WhlDir, init-value=XDIS_1qop2uga8u6pailb3xixw6g6t/l3, to ECM ISM TCM  # Drehrichtung Rad hinten links (SNA falls Senor nicht vorhanden) / Direction of rotation of rear left wheel (SNA if sensor not present)
          signal WhlPlsCnt_FL: start 32, 8 bit, little-endian, data-type=c08_Impulses_0_254_1, init-value=XDIS_a8d4ztmqyi6w3ybp8z5ft5e0/l255, to ECM ISM TCM  # Impuls-Ringzähler Rad vorne links (96 pro Umdrehung) / Wheel pulse counter front left (96 per rotation)
          signal WhlPlsCnt_RL: start 56, 8 bit, little-endian, data-type=c08_Impulses_0_254_1, init-value=XDIS_a8d4ztmqyi6w3ybp8z5ft5e0/l255, to ECM ISM TCM  # Impuls-Ringzähler Rad hinten links (96 pro Umdrehung) / Wheel pulse counter rear left (96 per rotation)
          signal WhlRPM_FL: start 16, 14 bit, little-endian, data-type=c14_rpm_0_8191_0k5, init-value=XDIS_eso3tkwpkvbawn94lsv7hjxdg/l16383, to ECM ISM TCM  # Raddrehzahl vorne links / Wheel rpm front left
          signal WhlRPM_FL_Qual: start 12, 2 bit, little-endian, data-type=c02_Signal_Qual, init-value=lELEC, to ECM ISM TCM  # Qualität der Raddrehzahl vorne links / Quality of wheel rpm front left
          signal WhlRPM_RL: start 40, 14 bit, little-endian, data-type=c14_rpm_0_8191_0k5, init-value=XDIS_eso3tkwpkvbawn94lsv7hjxdg/l16383, to ECM ISM TCM  # Raddrehzahl hinten links / Wheel rpm rear left
          signal WhlRPM_RL_Qual: start 14, 2 bit, little-endian, data-type=c02_Signal_Qual, init-value=lELEC, to ECM ISM TCM  # Qualität der Raddrehzahl hinten links / Quality of wheel rpm rear left
          signal Whl_Lt_Stat_Pr2_s0yl1k4cam60smahrd06qo1g: little-endian, system-signal=[CRC_Whl_Lt_Stat_Pr2, SQC_Whl_Lt_Stat_Pr2, WhlDir_FL_Stat, WhlDir_RL_Stat, WhlPlsCnt_FL, WhlPlsCnt_RL, WhlRPM_FL, WhlRPM_FL_Qual, WhlRPM_RL, WhlRPM_RL_Qual], transfer-property=PENDING, to ECM ISM TCM  # Status Räder links (degraded) / Left wheels state (degraded)
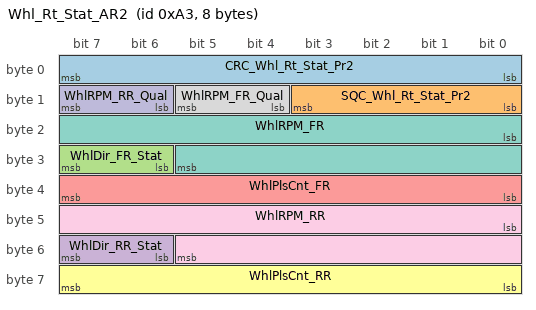
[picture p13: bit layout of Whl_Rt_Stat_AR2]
      frame Whl_Rt_Stat_AR2: id 0xA3, from CPC, to ECM ISM TCM, frame-length=8, can-addressing-mode=STANDARD  # Status Räder rechts / Right wheels state
        pdu Whl_Rt_Stat_AR2: length=64, unused-bit-pattern=0, cyclic-timing=repeating-time=0.02  # Status Räder rechts / Right wheels state
          signal CRC_Whl_Rt_Stat_Pr2: start 0, 8 bit, little-endian, data-type=c08_CRC_woSNA, init-value=l144, to ECM ISM TCM  # CRC-Checksumme der Signal Gruppe gemäß AUTOSAR Profil 2 / CRC-checksum of signal group according to AUTOSAR Profile 2
          signal SQC_Whl_Rt_Stat_Pr2: start 8, 4 bit, little-endian, data-type=c04_0_15_1_SNA_na, init-value=XDIS_2gdok7is6uk227cngmpgf9wxb/l0, to ECM ISM TCM  # Sequenzzähler / Sequence counter
          signal WhlDir_FR_Stat: start 30, 2 bit, little-endian, data-type=c02_WhlDir, init-value=XDIS_1qop2uga8u6pailb3xixw6g6t/l3, to ECM ISM TCM  # Drehrichtung Rad vorne rechts (SNA falls Senor nicht vorhanden) / Direction of rotation of front right wheel (SNA if sensor not present)
          signal WhlDir_RR_Stat: start 54, 2 bit, little-endian, data-type=c02_WhlDir, init-value=XDIS_1qop2uga8u6pailb3xixw6g6t/l3, to ECM ISM TCM  # Drehrichtung Rad hinten rechts (SNA falls Senor nicht vorhanden) / Direction of rotation of rear right wheel (SNA if sensor not present)
          signal WhlPlsCnt_FR: start 32, 8 bit, little-endian, data-type=c08_Impulses_0_254_1, init-value=XDIS_a8d4ztmqyi6w3ybp8z5ft5e0/l255, to ECM ISM TCM  # Impuls-Ringzähler Rad vorne rechts (96 pro Umdrehung) / Wheel pulse counter front right (96 per rotation)
          signal WhlPlsCnt_RR: start 56, 8 bit, little-endian, data-type=c08_Impulses_0_254_1, init-value=XDIS_a8d4ztmqyi6w3ybp8z5ft5e0/l255, to ECM ISM TCM  # Impuls-Ringzähler Rad hinten rechts (96 pro Umdrehung) / Wheel pulse counter rear right (96 per rotation)
          signal WhlRPM_FR: start 16, 14 bit, little-endian, data-type=c14_rpm_0_8191_0k5, init-value=XDIS_eso3tkwpkvbawn94lsv7hjxdg/l16383, to ECM ISM TCM  # Raddrehzahl vorne rechts / Wheel rpm front right
          signal WhlRPM_FR_Qual: start 12, 2 bit, little-endian, data-type=c02_Signal_Qual, init-value=lELEC, to ECM ISM TCM  # Qualität der Raddrehzahl vorne rechts / Quality of wheel rpm front right
          signal WhlRPM_RR: start 40, 14 bit, little-endian, data-type=c14_rpm_0_8191_0k5, init-value=XDIS_eso3tkwpkvbawn94lsv7hjxdg/l16383, to ECM ISM TCM  # Raddrehzahl hinten rechts / Wheel rpm rear right
          signal WhlRPM_RR_Qual: start 14, 2 bit, little-endian, data-type=c02_Signal_Qual, init-value=lELEC, to ECM ISM TCM  # Qualität der Raddrehzahl hinten rechts / Quality of wheel rpm rear right
          signal Whl_Rt_Stat_Pr2_5rdhw8834wvrtpb3zqsdx2byz: little-endian, system-signal=[CRC_Whl_Rt_Stat_Pr2, SQC_Whl_Rt_Stat_Pr2, WhlDir_FR_Stat, WhlDir_RR_Stat, WhlPlsCnt_FR, WhlPlsCnt_RR, WhlRPM_FR, WhlRPM_FR_Qual, WhlRPM_RR, WhlRPM_RR_Qual], transfer-property=PENDING, to ECM ISM TCM  # Status Räder rechts (degraded) / Right wheels state (degraded)
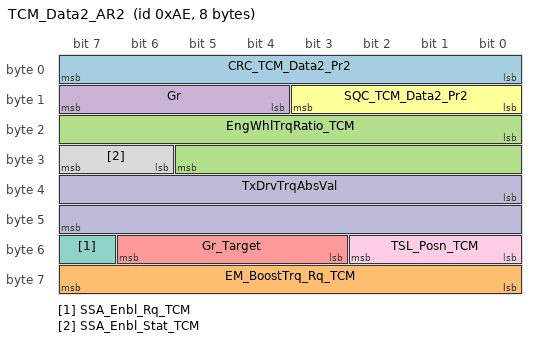
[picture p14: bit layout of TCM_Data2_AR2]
      frame TCM_Data2_AR2: id 0xAE, from TCM, to ASX CPC DRVU ECM, frame-length=8, can-addressing-mode=STANDARD
        pdu TCM_Data2_AR2: length=64, unused-bit-pattern=0, cyclic-timing={repeating-time=0.02, starting-time=0.03}
          signal CRC_TCM_Data2_Pr2: start 0, 8 bit, little-endian, data-type=c08_CRC_woSNA, init-value=l115, to ASX CPC DRVU(timeout 0.21 s) ECM  # CRC-Checksumme der Signal Gruppe gemäß AUTOSAR Profil 2 / CRC-checksum of signal group according to AUTOSAR Profile 2
          signal EM_BoostTrq_Rq_TCM: start 56, 8 bit, little-endian, data-type=c08_Nm_0_508_2, init-value=XDIS_6eq3dok2smxmzb9ovf38bf5xt/l255, to ASX CPC DRVU(timeout 0.21 s) ECM  # Durch das Getriebe angefordertes Boostmoment / Boost torque request from TCM
          signal EngWhlTrqRatio_TCM: start 16, 14 bit, little-endian, data-type=c14_0_163k82_0k01, init-value=XDIS_9cv1zr7d4o7iodto62m2lekxl/l16383, to ASX CPC DRVU(timeout 0.21 s) ECM  # Faktor Kurbelwellenmoment zu Radmoment / Crankshaft torque to wheel torque ratio
          signal Gr: start 12, 4 bit, little-endian, data-type=c04_Gr, init-value=XDIS_dez57pzmykmhphfykjtcbqq8k/l15, to ASX CPC DRVU(timeout 0.21 s) ECM  # Ist-Gang / Actual gear
          signal Gr_Target: start 51, 4 bit, little-endian, data-type=c04_Gr_Target, init-value=XDIS_atinj15as1edtr54we098gq70/l15, to ASX CPC DRVU(timeout 0.21 s) ECM  # Ziel-Gang / Target gear
          signal SQC_TCM_Data2_Pr2: start 8, 4 bit, little-endian, data-type=c04_0_15_1_SNA_na, init-value=XDIS_2gdok7is6uk227cngmpgf9wxb/l0, to ASX CPC DRVU(timeout 0.21 s) ECM  # Sequenzzähler / Sequence counter
          signal SSA_Enbl_Rq_TCM: start 55, 1 bit, little-endian, data-type=DC_BOOL, init-value=XDIS_h5tcyk98kzbgrc5svasomeyt/lfalse, to ASX CPC DRVU(timeout 0.21 s) ECM  # ASS enable (P2: "Laden im Stand" erlaubt) / Enable stop/start automatic request (P2: Enable charge while standing)
          signal SSA_Enbl_Stat_TCM: start 30, 2 bit, little-endian, data-type=c02_SSA_ENBL_DSABL_PNA_TCM, init-value=lSSA_ENBL, to ASX CPC DRVU(timeout 0.21 s) ECM  # TCM Stopp/Start-Automatik Freigabestatus / SSA enabling stat
          signal TSL_Posn_TCM: start 48, 3 bit, little-endian, data-type=c03_TSL_Posn, init-value=XDIS_33c02c3rpodye2msroia5xjdy/l7, to ASX CPC DRVU(timeout 0.21 s) ECM  # Getriebewählhebelstellung / Transmission selector lever position
          signal TxDrvTrqAbsVal: start 32, 16 bit, little-endian, data-type=c16_Nm_0_65534_1, init-value=XDIS_bt22q3rlqrhrx8ewv1le28p03/l65535, to ASX CPC DRVU(timeout 0.21 s) ECM  # Betrag des Gesamtseitenwellenmoment im Anfahrbereich / Absolute value of the transmission overall drive shaft torque for driveaway
          signal TCM_Data2_Pr2_3aes4m38p3xyalmhl6p5hhgww: little-endian, system-signal=[CRC_TCM_Data2_Pr2, EM_BoostTrq_Rq_TCM, EngWhlTrqRatio_TCM, Gr, Gr_Target, SQC_TCM_Data2_Pr2, SSA_Enbl_Rq_TCM, SSA_Enbl_Stat_TCM, TSL_Posn_TCM, TxDrvTrqAbsVal], transfer-property=PENDING, to ASX CPC DRVU(timeout 0.21 s) ECM  # TCM Data 2 (degraded) / TCM Date 2 (degraded)
      frame TCM_Data3_AR2: id 0xAF, from TCM, to CPC DRVU ECM, frame-length=8, can-addressing-mode=STANDARD
        pdu TCM_Data3_AR2: length=64, unused-bit-pattern=0, cyclic-timing={repeating-time=0.02, starting-time=0.025}
          signal Clutch_Actv_Stat: start 54, 2 bit, little-endian, data-type=c02_Clutch_Actv_Stat, init-value=XDIS_4q3sxcq1uglc3l4vfg73a7rs7/l3, transfer-property=PENDING, to CPC ECM  # Kupplungsbewegung status / Clutch activity status
          signal Clutch_Stat: start 51, 3 bit, little-endian, data-type=c03_Clutch_Stat, init-value=lDISENGG, transfer-property=PENDING, to CPC ECM  # Status (Wandlerüberbrückungs-) Kupplung / State (torque converter lockup) clutch
          signal CRC_TCM_Data3_Pr2: start 0, 8 bit, little-endian, data-type=c08_CRC_woSNA, init-value=l204, to CPC DRVU(timeout 0.21 s) ECM  # CRC-Checksumme der Signal Gruppe gemäß AUTOSAR Profil 2 / CRC-checksum of signal group according to AUTOSAR Profile 2
          signal EM_Trq_RecupGrdnt_Max: start 59, 4 bit, little-endian, data-type=c04_EM_Trq_RecupGrdnt_Max, init-value=XDIS_2mdcyyt3qya3c0y8ckut05qg9/l0, transfer-property=PENDING, to CPC  # Maximaler Gradient E-Maschine Drehmoment für Rekuperation / Maximum gradient of EM torque for recuperation
          signal EngTrqMax_Rq_TCM: start 38, 1 bit, little-endian, data-type=DC_BOOL, init-value=XDIS_h5tcyk98kzbgrc5svasomeyt/lfalse, to CPC DRVU(timeout 0.21 s) ECM  # Motormomentenanforderung Max / Engine torque request maximum; 451ev: OnBoard Charger Proximity Detect
          signal EngTrqMin_Rq_TCM: start 39, 1 bit, little-endian, data-type=DC_BOOL, init-value=XDIS_h5tcyk98kzbgrc5svasomeyt/lfalse, to CPC DRVU(timeout 0.21 s) ECM  # Motormomentenanforderung Min / Engine torque request minimum
          signal Gr_Target_TxShiftRcmmnd: start 40, 4 bit, little-endian, data-type=c04_Gr_Target_Disp_Rq, init-value=XDIS_3wemiyqgjwvlumaoj8nb1rfke/l15, transfer-property=PENDING, to CPC ECM  # Zielgang der Schaltempfehlung / Target gear for shift recommendation
          signal PwrFreeD_Actv: start 47, 1 bit, little-endian, data-type=DC_BOOL, init-value=XDIS_h5tcyk98kzbgrc5svasomeyt/lfalse, transfer-property=PENDING, to CPC ECM  # "Kraftfrei in D" aktiv / "Power-free in D" active
          signal Ratio_Chg_Actv: start 56, 1 bit, little-endian, data-type=DC_BOOL, init-value=XDIS_h5tcyk98kzbgrc5svasomeyt/lfalse, transfer-property=PENDING, to CPC ECM  # Übersetzungsänderung aktiv / Ratio change active
          signal Ratio_Chg_Cont_Actv: start 44, 1 bit, little-endian, data-type=DC_BOOL, init-value=XDIS_h5tcyk98kzbgrc5svasomeyt/lfalse, transfer-property=PENDING, to CPC  # Ratio Change Continuous Active
          signal SQC_TCM_Data3_Pr2: start 8, 4 bit, little-endian, data-type=c04_0_15_1_SNA_na, init-value=XDIS_2gdok7is6uk227cngmpgf9wxb/l0, to CPC DRVU(timeout 0.21 s) ECM  # Sequenzzähler / Sequence counter
          signal StartBrk_Rq_TCM: start 63, 1 bit, little-endian, data-type=DC_BOOL, init-value=XDIS_h5tcyk98kzbgrc5svasomeyt/lfalse, transfer-property=PENDING, to CPC  # Bremse anlegen bei Einschaltvorgang / Brake during start request
          signal TCC_NoLoad: start 50, 1 bit, little-endian, data-type=DC_BOOL, init-value=XDIS_h5tcyk98kzbgrc5svasomeyt/lfalse, transfer-property=PENDING, to CPC ECM  # Wandlerüberbrückungskupplung lastfrei / Torque converter lockup clutch no load
          signal TCM_EngIdleRPM_Lvl_Rq: start 48, 2 bit, little-endian, data-type=c02_TCM_EngIdleRPM_Lvl_Rq, init-value=XDIS_6aph7vt7h588vh2n3ky4tffzu/lIDLE, transfer-property=PENDING, to CPC ECM  # Anforderung Leerlaufdrehzahlniveau / Engine idle speed level request
          signal Tx_Safe_Cls: start 36, 1 bit, little-endian, data-type=DC_BOOL, init-value=XDIS_h5tcyk98kzbgrc5svasomeyt/lfalse, to CPC DRVU(timeout 0.21 s) ECM  # Getriebe befindet sich in einem sicheren Zustand wenn B2- und B3-Kupplung geschlossen ist. / Gear is under safe condition. if B2 and B3 drive coupling is closed
          signal TxOutRPM_Plaus: start 37, 1 bit, little-endian, data-type=DC_BOOL, init-value=XDIS_h5tcyk98kzbgrc5svasomeyt/lfalse, to CPC DRVU(timeout 0.21 s) ECM  # Plausibilisierung der Getriebeausgangsdrehzahl bestanden / Transmission output RPM plausible
          signal TxOutRPM_V2: start 24, 12 bit, little-endian, data-type=c12_rpm_0_16376_4, init-value=XDIS_c5ocfhi8et6dfyhtan4nkmz07/l4095, to CPC DRVU(timeout 0.21 s) ECM  # Aktuelle Getriebeausgangsdrehzahl / Actual transmission output rpm
          signal TxRatioChgRq_Actv: start 46, 1 bit, little-endian, data-type=DC_BOOL, init-value=XDIS_h5tcyk98kzbgrc5svasomeyt/lfalse, transfer-property=PENDING, to CPC  # Signalisierung Gangwechsel wird eingeleitet / Transmission ratio change request active
          signal TxTurbineRPM_V2: start 12, 12 bit, little-endian, data-type=c12_rpm_0_8188_2, init-value=XDIS_dd6txh2gockdf2ckmql7drv7h/l4095, to CPC DRVU(timeout 0.21 s) ECM  # Aktuelle Turbinendrehzahl / Actual transmission turbine rpm
          signal TCM_Data3_Pr2_4mdu2ave4pajazfn4q4pmyvzw: little-endian, system-signal=[CRC_TCM_Data3_Pr2, EngTrqMax_Rq_TCM, EngTrqMin_Rq_TCM, SQC_TCM_Data3_Pr2, Tx_Safe_Cls, TxOutRPM_Plaus, TxOutRPM_V2, TxTurbineRPM_V2], transfer-property=PENDING, to CPC DRVU(timeout 0.21 s) ECM  # TCM Rpms (degraded)
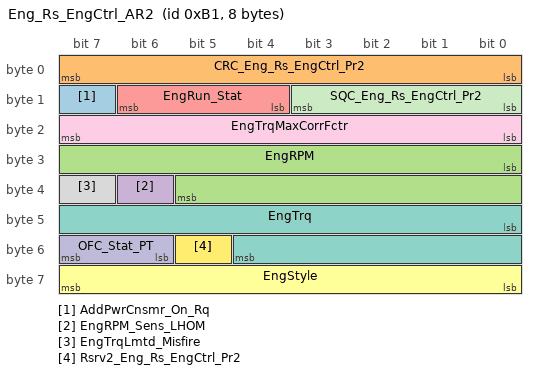
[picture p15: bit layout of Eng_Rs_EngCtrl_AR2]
      frame Eng_Rs_EngCtrl_AR2: id 0xB1, from ECM, to ASX CPC DRVU FFAP_STAR_2 FSCM ISM TCM TGW, frame-length=8, can-addressing-mode=STANDARD  # Motoransprechverhalten Engine Control / Engine response Engine Control
        pdu Eng_Rs_EngCtrl_AR2: length=64, unused-bit-pattern=0, cyclic-timing={repeating-time=0.01, starting-time=0.0050}  # Motoransprechverhalten Engine Control / Engine response Engine Control
          signal AddPwrCnsmr_On_Rq: start 15, 1 bit, little-endian, data-type=DC_BOOL, init-value=XDIS_h5tcyk98kzbgrc5svasomeyt/lfalse, to ASX CPC DRVU(timeout 0.105 s) FFAP_STAR_2 FSCM(timeout 0.105 s) ISM TCM TGW(timeout 1.005 s)  # Anforderung zusätzliche Stromverbraucher einschalten / Additional power consumers on request
          signal CRC_Eng_Rs_EngCtrl_Pr2: start 0, 8 bit, little-endian, data-type=c08_CRC_woSNA, init-value=l97, to ASX CPC DRVU(timeout 0.105 s) FFAP_STAR_2 FSCM(timeout 0.105 s) ISM TCM TGW(timeout 1.005 s)  # CRC-Checksumme der Signal Gruppe gemäß AUTOSAR Profil 2 / CRC-checksum of signal group according to AUTOSAR Profile 2
          signal EngRPM: start 24, 14 bit, little-endian, data-type=c14_rpm_0_16382_1, init-value=XDIS_82nfehr3ho0td8jgmxjg4mj72/l16383, to ASX CPC DRVU(timeout 0.105 s) FFAP_STAR_2 FSCM(timeout 0.105 s) ISM TCM TGW(timeout 1.005 s)  # Motordrehzahl / Actual engine rpm
          signal EngRPM_Sens_LHOM: start 38, 1 bit, little-endian, data-type=DC_BOOL, init-value=XDIS_h5tcyk98kzbgrc5svasomeyt/lfalse, to ASX CPC DRVU(timeout 0.105 s) FFAP_STAR_2 FSCM(timeout 0.105 s) ISM TCM TGW(timeout 1.005 s)  # Motordrehzahlgeber im Notlaufbetrieb / Engine rpm sensor in limp-home operation mode
          signal EngRun_Stat: start 12, 3 bit, little-endian, data-type=c03_EngRun_Stat, init-value=XDIS_1ps1d53o7u62lv4xtueyronz7/l7, to ASX CPC DRVU(timeout 0.105 s) FFAP_STAR_2 FSCM(timeout 0.105 s) ISM TCM TGW(timeout 1.005 s)  # Status Motorlauf / Engine running state
          signal EngStyle: start 56, 8 bit, little-endian, data-type=c08_EngStyle, init-value=XDIS_8avi24l4s7lv1vscy4ses376c/l255, to ASX CPC DRVU(timeout 0.105 s) FFAP_STAR_2 FSCM(timeout 0.105 s) ISM TCM TGW(timeout 1.005 s)  # Motor (Bit 7: Benziner => 0, Diesel => 1) / Engine (Bit 7: Otto-engine => 0, Diesel-engine => 1)
          signal EngTrq: start 40, 13 bit, little-endian, data-type=c13_Nm_m500_1547k5_0k25, init-value=XDIS_emg3258s4xg6nj4415gnzzldg/l8191, to ASX CPC DRVU(timeout 0.105 s) FFAP_STAR_2 FSCM(timeout 0.105 s) ISM TCM TGW(timeout 1.005 s)  # Aktuelles Motormoment (nur STAR1, STAR2, 190 Benzin-Motoren mit NAG3: aktuelles Maximal-Moment) / Actual engine torque (only STAR1, STAR2, 190 gasoline engines with NAG3 actual maximum torque)
          signal EngTrqLmtd_Misfire: start 39, 1 bit, little-endian, data-type=DC_BOOL, init-value=XDIS_h5tcyk98kzbgrc5svasomeyt/lfalse, to ASX CPC DRVU(timeout 0.105 s) FFAP_STAR_2 FSCM(timeout 0.105 s) ISM TCM TGW(timeout 1.005 s)  # Motormomentenbegrenzung wegen Zündausfall / Engine Torque Limited due to misfire detection
          signal EngTrqMaxCorrFctr: start 16, 8 bit, little-endian, data-type=c08_0_1k98_0k0078, init-value=XDIS_327f49tzxohck8g8esrcyugmz/l255, to ASX CPC DRVU(timeout 0.105 s) FFAP_STAR_2 FSCM(timeout 0.105 s) ISM TCM TGW(timeout 1.005 s)  # Faktor für Abwert. d. max. Mom. bei abneh. A.druck / Correction factor of maximum engine torque depending on falling atmospheric pressure
          signal OFC_Stat_PT: start 54, 2 bit, little-endian, data-type=c02_OFC_Stat, init-value=XDIS_e20gnm5txixk6vheaqfbd4u3b/lIDLE, to ASX CPC DRVU(timeout 0.105 s) FFAP_STAR_2 FSCM(timeout 0.105 s) ISM TCM TGW(timeout 1.005 s)  # Schubabschaltung / Overrun fuel cutoff active
          signal SQC_Eng_Rs_EngCtrl_Pr2: start 8, 4 bit, little-endian, data-type=c04_0_15_1_SNA_na, init-value=XDIS_2gdok7is6uk227cngmpgf9wxb/l0, to ASX CPC DRVU(timeout 0.105 s) FFAP_STAR_2 FSCM(timeout 0.105 s) ISM TCM TGW(timeout 1.005 s)  # Sequenzzähler / Sequence counter
          signal Rsrv2_Eng_Rs_EngCtrl_Pr2: start 53, 1 bit, little-endian, data-type=Rsrv01, init-value=XDIS_e2uhxyvdu33zsyqfjnk549pp2/l0, to ASX CPC DRVU FFAP_STAR_2 FSCM ISM TCM TGW  # Reserviert für zukünftige Verwendung / Reserved for future use
          signal Eng_Rs_EngCtrl_Pr2_1g6e1wh7aspfj509n9mt9fl55: little-endian, system-signal=[AddPwrCnsmr_On_Rq, CRC_Eng_Rs_EngCtrl_Pr2, EngRPM, EngRPM_Sens_LHOM, EngRun_Stat, EngStyle, EngTrq, EngTrqLmtd_Misfire, EngTrqMaxCorrFctr, OFC_Stat_PT, Rsrv2_Eng_Rs_EngCtrl_Pr2, SQC_Eng_Rs_EngCtrl_Pr2], transfer-property=PENDING, to ASX CPC DRVU(timeout 0.105 s) FFAP_STAR_2 FSCM(timeout 0.105 s) ISM TCM TGW(timeout 1.005 s)  # Motoransprechverhalten Engine Control (degraded) / Engine response Engine Control (degraded)
      frame PtMngmnt_Rq_AR2: id 0xB3, from CPC, to ASX DRVU ECM TCM TGW, frame-length=8, can-addressing-mode=STANDARD  # Schaltanforderung von Powertrain Management / Request from Powertrain management
        pdu PtMngmnt_Rq_AR2: length=64, unused-bit-pattern=0, cyclic-timing={repeating-time=0.02, starting-time=0.0}  # Anforderung von Powertrain Management / Request from Powertrain management
          signal CRC_PtMngmnt_Rq_Pr2: start 0, 8 bit, little-endian, data-type=c08_CRC_woSNA, init-value=l193, to ECM TCM  # CRC-Checksumme der Signal Gruppe gemäß AUTOSAR Profil 2 / CRC-checksum of signal group according to AUTOSAR Profile 2
          signal ECM_Creep_Abort_Stat: start 59, 2 bit, little-endian, data-type=c02_NotActv_Actv_NDef, init-value=XDIS_7rsnpoiiencgp952qxy5gtc8v/l3, transfer-property=PENDING, to TCM  # TCM Momentreduzierung Kriechen Abbruchstatus / Creep abort state
          signal ESP_Intrvntn_Stat_ECM: start 57, 2 bit, little-endian, data-type=c02_ESP_Intrvntn_Stat_ECM, init-value=lNO_INTRVNTN, transfer-property=PENDING, to TCM  # Status ESP Momenteneingriff / State ESP torque intervention
          signal ExhstFlap_Stg_AMG: start 40, 3 bit, little-endian, data-type=c03_ExhstFlap_Stg, init-value=XDIS_dj236vlj8xzzdctuelqz8u9rt/lIDLE, transfer-property=PENDING, to ASX(timeout 0.21 s) DRVU(timeout 1.05 s) TGW(timeout 0.21 s)  # Rückmeldung der Abgasklappenstellung (nur AMG) / Response exhaust flap stage (AMG only)
          signal GrMax_Rq_ECM_V2: start 28, 4 bit, little-endian, data-type=c04_GrMax_Rq_v2, init-value=XDIS_7uq2qghvjbhki2cbg83r4b55h/lPASSIVE, to ECM TCM  # Sollgang, obere Grenze / Requested gear, upper limit
          signal GrMin_Rq_ECM_V2: start 24, 4 bit, little-endian, data-type=c04_GrMin_Rq_v2, init-value=XDIS_9m6sblz9nzl5h9osu1t5bxtb7/lPASSIVE, to ECM TCM  # Sollgang, untere Grenze / Requested gear, lower limit
          signal PwrFreeD_Rq_ECM: start 63, 1 bit, little-endian, data-type=DC_BOOL, init-value=XDIS_h5tcyk98kzbgrc5svasomeyt/lfalse, transfer-property=PENDING, to TCM  # 'Power-free in D' ECM request (Segeln) / 'Power-free in D' ECM request
          signal Recup_Dsabl_Rq_PT: start 32, 2 bit, little-endian, data-type=c02_Enable_Disable, init-value=lENBL, to ECM TCM  # Rekuperation abschalten / Recuperation disable request
          signal SQC_PtMngmnt_Rq_Pr2: start 8, 4 bit, little-endian, data-type=c04_0_15_1_SNA_na, init-value=XDIS_2gdok7is6uk227cngmpgf9wxb/l0, to ECM TCM  # Sequenzzähler / Sequence counter
          signal SSA_EngSp: start 14, 1 bit, little-endian, data-type=DC_BOOL, init-value=XDIS_h5tcyk98kzbgrc5svasomeyt/lfalse, to ECM TCM  # ASS Motorstopp, 1=Stopp, 0=Normalbetrieb / Stop/start automatic has engine stopped
          signal SSA_Sp_Warn: start 15, 1 bit, little-endian, data-type=DC_BOOL, init-value=XDIS_h5tcyk98kzbgrc5svasomeyt/lfalse, to ECM TCM  # ASS Vorwarnung Motorstopp / Stop/Start automatic pre-warning engine stop
          signal TCC_Opn_RemainTm_HDC: start 50, 6 bit, little-endian, data-type=c06_s_0_6d2_0d1, init-value=XDIS_6nmd1urt4d1stcmz9cbruyn1m/l0, transfer-property=PENDING  # Verbleibende Zeitdauer bis zum Öffnen der Wandlerüberbrückungskupplung nach Relevanzprüfung durch die Betriebsstrategie / Remaining time till opening of torque converter lockup clutch after relevance check by hybrid drive control
          signal TCM_DHill_ShftChrDsp_Rq: start 62, 1 bit, little-endian, data-type=DC_BOOL, init-value=XDIS_h5tcyk98kzbgrc5svasomeyt/lfalse, transfer-property=PENDING, to TCM  # Anforderung Abschaltung bergab Schaltlinienverschiebung / Downhill Shift characteristic displacement request
          signal TxPkPosn_Rq_ECM: start 12, 2 bit, little-endian, data-type=c02_TxPkPos_Rq, init-value=XDIS_2db0f8ngs6vghwr5wq6rrafpy/lIDLE, to ECM TCM  # EPKB-Wunsch: "P" einlegen / Transmission parking position request
          signal WDC_Intrvntn_ECM: start 61, 1 bit, little-endian, data-type=DC_BOOL, init-value=XDIS_h5tcyk98kzbgrc5svasomeyt/lfalse, transfer-property=PENDING, to TCM  # Anforderung Motor Intervention, e.g. rocking clutch / Engine requests Intervention
          signal Rsrv1_PtMngmnt_Rq_Pr2: start 34, 6 bit, little-endian, data-type=Rsrv06, init-value=XDIS_zukcixzhzplmgdoo03mopm29/l0, to ASX DRVU ECM TCM TGW  # Reserviert für zukünftige Verwendung / Reserved for future use
          signal Rsrv2_PtMngmnt_Rq_Pr2: start 16, 8 bit, little-endian, data-type=Rsrv08, init-value=XDIS_4flxbk4wkjkdew7cw07d9of66/l0, to ASX DRVU ECM TCM TGW  # Rsrv2 Pt Mngmnt Rq Pr2
          signal PtMngmnt_Rq_Pr2_czcqfhcxlfzoeyleoslpc91wg: little-endian, system-signal=[CRC_PtMngmnt_Rq_Pr2, GrMax_Rq_ECM_V2, GrMin_Rq_ECM_V2, Recup_Dsabl_Rq_PT, Rsrv1_PtMngmnt_Rq_Pr2, Rsrv2_PtMngmnt_Rq_Pr2, SQC_PtMngmnt_Rq_Pr2, SSA_EngSp, SSA_Sp_Warn, TxPkPosn_Rq_ECM], transfer-property=PENDING, to ECM TCM  # Anforderung vom Powertrain Management (degraded) / Request from Powertrain management (degraded)
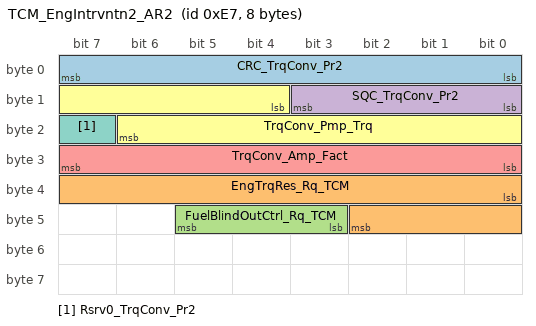
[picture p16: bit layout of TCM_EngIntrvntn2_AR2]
      frame TCM_EngIntrvntn2_AR2: id 0xE7, from TCM, to CPC ECM, frame-length=8, can-addressing-mode=STANDARD
        pdu TCM_EngIntrvntn2_AR2: length=64, unused-bit-pattern=0, cyclic-timing={repeating-time=0.01, starting-time=0.0050}
          signal CRC_TrqConv_Pr2: start 0, 8 bit, little-endian, data-type=c08_CRC_woSNA, init-value=l35, to CPC  # CRC-Checksumme der Signal Gruppe gemäß AUTOSAR Profil 2 / CRC-checksum of signal group according to AUTOSAR Profile 2
          signal EngTrqRes_Rq_TCM: start 32, 11 bit, little-endian, data-type=c11_Nm_m500_1546k0_1k0, init-value=XDIS_c1d4l3fliyrryv1w2ncd3uiy6/l2047, transfer-property=PENDING, to CPC  # Momentenanforderung über Luftpfad / Reserve / Engine torque request reserve by TCM
          signal FuelBlindOutCtrl_Rq_TCM: start 43, 3 bit, little-endian, data-type=cFuelBlindOutCtrl_Rq_TCM, init-value=lNOT_ACTV, transfer-property=PENDING, to CPC ECM  # (Kraftstoff) Ausblendesteuerung Anforderung Getriebe / Fuel blind out control request by TCM
          signal SQC_TrqConv_Pr2: start 8, 4 bit, little-endian, data-type=c04_0_15_1_SNA_na, init-value=XDIS_2gdok7is6uk227cngmpgf9wxb/l0, to CPC  # Sequenzzähler / Sequence counter
          signal TrqConv_Amp_Fact: start 24, 8 bit, little-endian, data-type=c08_0k5_3_0k01, init-value=XDIS_ew010c64wkf2naegyf4kegrn/l255, to CPC  # Wandler Verstärkungsfaktor / Torque converter amplification factor
          signal TrqConv_Pmp_Trq: start 12, 11 bit, little-endian, data-type=c11_Nm_m500_1546k0_1k0, init-value=XDIS_c1d4l3fliyrryv1w2ncd3uiy6/l2047, to CPC  # Wandler Pumpenmoment / Torque converter pump torque
          signal Rsrv0_TrqConv_Pr2: start 23, 1 bit, little-endian, data-type=Rsrv01, init-value=XDIS_e2uhxyvdu33zsyqfjnk549pp2/l0, to CPC ECM  # Reserviert für zukünftige Verwendung / Reserved for future use
          signal TrqConv_Pr2_d41hb9de6igapvaa0xr920t3b: little-endian, system-signal=[CRC_TrqConv_Pr2, Rsrv0_TrqConv_Pr2, SQC_TrqConv_Pr2, TrqConv_Amp_Fact, TrqConv_Pmp_Trq], transfer-property=PENDING, to CPC  # Torque Converter (degraded)
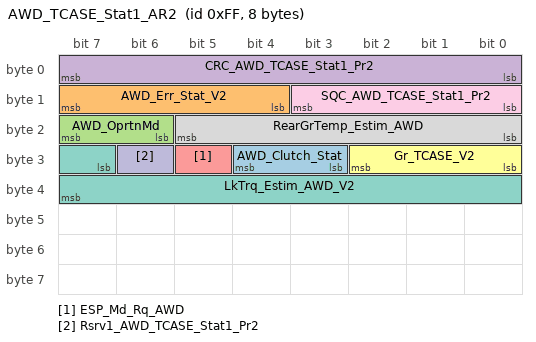
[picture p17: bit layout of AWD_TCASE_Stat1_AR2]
      frame AWD_TCASE_Stat1_AR2: id 0xFF, from CPC, to ECM TCM, frame-length=8, can-addressing-mode=STANDARD
        pdu AWD_TCASE_Stat1_AR2: length=64, unused-bit-pattern=0, cyclic-timing=repeating-time=0.02
          signal AWD_Clutch_Stat: start 27, 2 bit, little-endian, data-type=c02_Opn_Slip_Cls, init-value=XDIS_8tx3f7ckagrzwkrx5whhfvm3h/l3, to ECM TCM  # Status Allradantriebskupplung / All whell drive clutch state
          signal AWD_Err_Stat_V2: start 12, 4 bit, little-endian, data-type=c04_AWD_Err_Stat_V2, init-value=XDIS_5lx6mbkgozmiuxgrncigny9gq/l15, to ECM TCM  # AWD Fehlerstatus / AWD error state
          signal AWD_OprtnMd: start 22, 2 bit, little-endian, data-type=c02_AWD_OprtnMd, init-value=XDIS_7eryo4j0uk38grwid6m4x71mx/lNORMAL, to ECM TCM  # Betriebsmodus Allradantrieb / All wheel drive operation mode
          signal CRC_AWD_TCASE_Stat1_Pr2: start 0, 8 bit, little-endian, data-type=c08_CRC_woSNA, init-value=l47, to ECM TCM  # CRC-Checksumme der Signal Gruppe gemäß AUTOSAR Profil 2 / CRC-checksum of signal group according to AUTOSAR Profile 2
          signal ESP_Md_Rq_AWD: start 29, 1 bit, little-endian, data-type=DC_BOOL, init-value=XDIS_h5tcyk98kzbgrc5svasomeyt/lfalse, to ECM TCM  # Anforderung ESP-Modus / ESP mode request
          signal Gr_TCASE_V2: start 24, 3 bit, little-endian, data-type=c02_Gr_TCASE_V2, init-value=XDIS_dmnv8c42ay2tyyqj6pd44a0cd/l7, to ECM TCM  # Aktueller Gang Verteilergetriebe / Actual transfer case gear
          signal LkTrq_Estim_AWD_V2: start 31, 9 bit, little-endian, data-type=c09_Nm_0_2550_5, init-value=XDIS_5o7arrtv1ss14lripulpcuxnk/l0, to ECM TCM  # Geschätzte Sperr-Moment / Estimated locking torque All Wheel Drive
          signal RearGrTemp_Estim_AWD: start 16, 6 bit, little-endian, data-type=c06_perc_0_100_2, init-value=XDIS_2qf0xexx71gb6ldbah24rtevt/l63, to ECM TCM  # Die geschätzte Erwärmung des HAGs [%] / Estimated rear axle temperature [%]
          signal SQC_AWD_TCASE_Stat1_Pr2: start 8, 4 bit, little-endian, data-type=c04_0_15_1_SNA_na, init-value=XDIS_2gdok7is6uk227cngmpgf9wxb/l0, to ECM TCM  # Sequenzzähler / Sequence counter
          signal Rsrv1_AWD_TCASE_Stat1_Pr2: start 30, 1 bit, little-endian, data-type=Rsrv01, init-value=XDIS_e2uhxyvdu33zsyqfjnk549pp2/l0, to ECM TCM  # Reserviert für zukünftige Verwendung / Reserved for future use
          signal AWD_TCASE_Stat1_Pr2_3ufw8rot8ihm8nnppmgv2dnz0: little-endian, system-signal=[AWD_Clutch_Stat, AWD_Err_Stat_V2, AWD_OprtnMd, CRC_AWD_TCASE_Stat1_Pr2, ESP_Md_Rq_AWD, Gr_TCASE_V2, LkTrq_Estim_AWD_V2, RearGrTemp_Estim_AWD, Rsrv1_AWD_TCASE_Stat1_Pr2, SQC_AWD_TCASE_Stat1_Pr2], transfer-property=PENDING, to ECM TCM  # Status Allradantrieb und Verteilergetriebe (degraded) / All wheel drive and transfer case state (degraded)
      frame SSP_RS_AR: id 0x114, from SSP, to TCM, frame-length=4, can-addressing-mode=STANDARD
        pdu SSP_Rs_AR: length=32, unused-bit-pattern=0, cyclic-timing={repeating-time=0.02, starting-time=0.0}
          signal CurrDtyCyc_Actl: start 8, 8 bit, little-endian, data-type=c08_perc_0_100_0k5, init-value=XDIS_7gd3auxmk1537dxoewcnzblfs/l255, transfer-property=PENDING, to TCM  # Ist-Strom (Tastverhältnis) / Actual current duty cycle
          signal SSP_Diag_Stat: start 0, 8 bit, little-endian, data-type=c08_SSP_Diag_Stat, init-value=XDIS_ehiwrlaxe2swhpb7nvelu4but/lOK, transfer-property=PENDING, to TCM  # SSP Diagnose Status / SSP diagnostics state
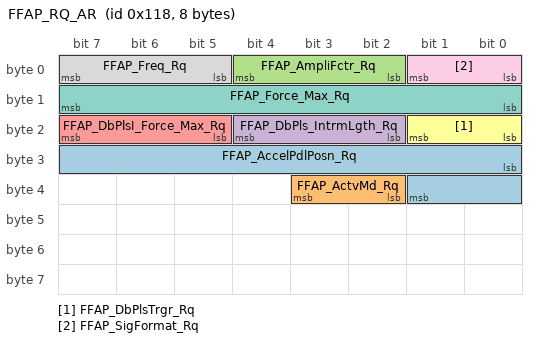
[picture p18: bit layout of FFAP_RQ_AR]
      frame FFAP_RQ_AR: id 0x118, from CPC, to FFAP_STAR_2 TCM, frame-length=8, can-addressing-mode=STANDARD
        pdu FFAP_Rq_AR: length=64, unused-bit-pattern=0, cyclic-timing={repeating-time=0.1, starting-time=0.015}, event-controlled-timing=number-of-repeats=0, minimum-delay=0.02
          signal FFAP_AccelPdlPosn_Rq: start 24, 10 bit, little-endian, data-type=c10_perc_0_100_0k1, init-value=XDIS_39a0u0s1i4hro531fl4hhze0m/l0, transfer-property=TRIGGERED-ON-CHANGE, to FFAP_STAR_2 TCM  # FFAP Soll-Gaspedalstellung für Fahrerfuss / FFAP Accelerator pedal position Request
          signal FFAP_ActvMd_Rq: start 34, 2 bit, little-endian, data-type=c02_FFAP_ActvMd, init-value=XDIS_aybv6ycjlpcbqdlifi85r6ucj/lOFF, transfer-property=PENDING, to FFAP_STAR_2  # FFAP Aktivierung Funktionalität / FFAP activation mode request
          signal FFAP_AmpliFctr_Rq: start 2, 3 bit, little-endian, data-type=c03_FFAP_AmpliFctr, init-value=lAMPL_0, to FFAP_STAR_2  # FFAP Jitter Amplitude (Maximalkraft) des Pedals / FFAP Amplitude Factor
          signal FFAP_DbPls_IntrmLgth_Rq: start 18, 3 bit, little-endian, data-type=c03_FFAP_DbPls_IntrmLgth_Rq, init-value=lLGTH_50, transfer-property=PENDING, to FFAP_STAR_2  # FFAP Intermediate Length for Double Impulse
          signal FFAP_DbPlsI_Force_Max_Rq: start 21, 3 bit, little-endian, data-type=c03_FFAP_DbPlsI_Force_Max, init-value=lFORCE_0, transfer-property=PENDING, to FFAP_STAR_2  # FFAP Maximalkraft für Double Impulse / FFAP Maximum Force for Double Impulse
          signal FFAP_DbPlsTrgr_Rq: start 16, 2 bit, little-endian, data-type=c02_FFAP_DbPlsTrgr_Rq, init-value=lNO_DBPLSTRGR, transfer-property=TRIGGERED-ON-CHANGE, to FFAP_STAR_2  # FFAP Double Impulse Trigger
          signal FFAP_Force_Max_Rq: start 8, 8 bit, little-endian, data-type=c08_N_0_30_0d12, init-value=XDIS_5xemvfg590iym6h4wtm0j7kst/l0, transfer-property=TRIGGERED-ON-CHANGE, to FFAP_STAR_2  # FFAP Maximalkraft (Gegenkraft) im übertretenen Bereich / FFAP Maximum Force
          signal FFAP_Freq_Rq: start 5, 3 bit, little-endian, data-type=c03_FFAP_Frequency, init-value=lHZ_5, to FFAP_STAR_2  # FFAP Jitter Frequenz / FFAP Frequency Request
          signal FFAP_SigFormat_Rq: start 0, 2 bit, little-endian, data-type=c03_FFAP_SigFormat, init-value=XDIS_etkgb0ahlv2vzx54do643cq63/l3, to FFAP_STAR_2  # FFAP Jitter Signalform / FFAP Signal Format Request
          signal FFAP_DbPls_Rq_e3ruoxgpxxjtw75hktbk3o88g: little-endian, system-signal=[FFAP_DbPls_IntrmLgth_Rq, FFAP_DbPlsI_Force_Max_Rq, FFAP_DbPlsTrgr_Rq], to FFAP_STAR_2  # FFAP_DbPls_Rq (degraded)
          signal FFAP_SignalAttr_Rq_apxko4gwe2i7ye3haduu5o5qj: little-endian, system-signal=[FFAP_AmpliFctr_Rq, FFAP_Freq_Rq, FFAP_SigFormat_Rq], transfer-property=PENDING, to FFAP_STAR_2  # FFAP Signaleigenschaften (degraded) / FFAP Signal attribute request (degraded)
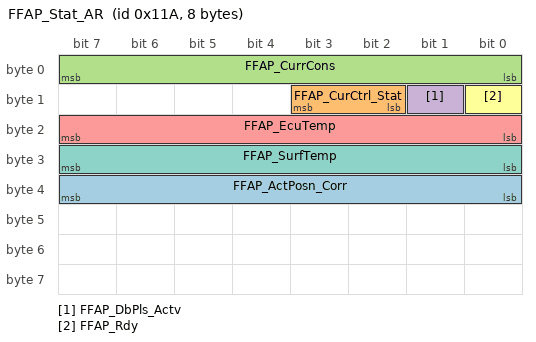
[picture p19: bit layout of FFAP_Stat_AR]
      frame FFAP_Stat_AR: id 0x11A, from FFAP_STAR_2, to CPC, frame-length=8, can-addressing-mode=STANDARD
        pdu FFAP_Stat_AR: length=64, unused-bit-pattern=0, cyclic-timing={repeating-time=0.1, starting-time=0.0}, event-controlled-timing=number-of-repeats=0, minimum-delay=0.02
          signal FFAP_ActPosn_Corr: start 32, 8 bit, little-endian, data-type=c08_perc_0_100_0k4, init-value=XDIS_5dn2zgpfmcdlqbsmco91plwk2/l0, transfer-property=PENDING, to CPC  # FFAP Aktuatorposition (mit Korrektur) / FFAP Actuator Position (with correction)
          signal FFAP_CurCtrl_Stat: start 10, 2 bit, little-endian, data-type=c02_FFAP_CurCtrl, init-value=XDIS_23a4hkjw60ovp13lkco2u4r84/l3, transfer-property=PENDING, to CPC  # FFAP Umsetzungsstatus Stromregler / FFAP Current Contoller State
          signal FFAP_CurrCons: start 0, 8 bit, little-endian, data-type=c08_A_0_15_0k06, init-value=XDIS_5k29pyc5m6vm6v3rbqmtacxgc/l0, transfer-property=TRIGGERED-ON-CHANGE, to CPC  # FFAP aktuelle Stromaufnahme / FFAP Actual Current Consumption
          signal FFAP_DbPls_Actv: start 9, 1 bit, little-endian, data-type=DC_BOOL, init-value=XDIS_h5tcyk98kzbgrc5svasomeyt/lfalse, transfer-property=TRIGGERED-ON-CHANGE, to CPC  # FFAP Double Impulse aktiv / FFAP Double Impulse active
          signal FFAP_EcuTemp: start 16, 8 bit, little-endian, data-type=c08_degC_m40_150_SNA_1, init-value=XDIS_df0ppdzkk2y7b69g4p1e9moaw/l0, transfer-property=PENDING, to CPC  # FFAP ECU Temperatur (in der Nähe der Leistungs-FETs) / FFAP ECU Temperature (near power FETs)
          signal FFAP_Rdy: start 8, 1 bit, little-endian, data-type=DC_BOOL, init-value=XDIS_h5tcyk98kzbgrc5svasomeyt/lfalse, transfer-property=PENDING, to CPC  # FFAP bereit / FFAP ready
          signal FFAP_SurfTemp: start 24, 8 bit, little-endian, data-type=c08_degC_m40_150_SNA_1, init-value=XDIS_df0ppdzkk2y7b69g4p1e9moaw/l0, transfer-property=PENDING, to CPC  # FFAP Aktuator Temperatur (Oberfläche) / FFAP Actuator Temperature (surface temperature)
      frame Tx_Rq_PtMngmnt_ECM_AR2: id 0x11C, from ECM, to CPC ISM TCM, frame-length=8, can-addressing-mode=STANDARD
        pdu Tx_Rq_PtMngmnt_ECM_AR2: length=64, unused-bit-pattern=0, cyclic-timing={repeating-time=0.02, starting-time=0.0}
          signal ActvDnShift_Rq_ECM: start 56, 1 bit, little-endian, data-type=DC_BOOL, init-value=XDIS_h5tcyk98kzbgrc5svasomeyt/lfalse, transfer-property=PENDING, to ISM TCM  # Aktive Rückschaltung ECM / Active down shift ECM
          signal CoastMd_Dsabl_Rq_ECM: start 60, 1 bit, little-endian, data-type=DC_BOOL, init-value=XDIS_h5tcyk98kzbgrc5svasomeyt/lfalse, transfer-property=PENDING, to CPC TCM  # Anzeigeanforderung Segeln koordiniert vom ECM / Coast Mode Disable Request Coordinated from ECM
          signal CRC_Tx_Rq_PtMngmnt_ECM_Pr2: start 0, 8 bit, little-endian, data-type=c08_CRC_woSNA, init-value=l168, to CPC ISM TCM  # CRC-Checksumme der Signal Gruppe gemäß AUTOSAR Profil 2 / CRC-checksum of signal group according to AUTOSAR Profile 2
          signal Creep_Off_Rq: start 23, 1 bit, little-endian, data-type=DC_BOOL, init-value=XDIS_h5tcyk98kzbgrc5svasomeyt/lfalse, to CPC ISM TCM  # Kriechen ausschalten / Creep mode off request
          signal ECM_LHOM_Stat: start 24, 8 bit, little-endian, data-type=c08_ECM_LHOM_Stat, init-value=lNO_LHOM, to CPC ISM TCM  # Engine control module in limp-home state (bitcodiert) / Engine control module in limp-home state (bitcodied)
          signal EngExhstAfterTreat_Actv: start 20, 1 bit, little-endian, data-type=DC_BOOL, init-value=XDIS_h5tcyk98kzbgrc5svasomeyt/lfalse, to CPC ISM TCM  # Motor-Abgasnachbehandlung aktiv (Diesel) / Engine exhaust-gas aftertreatment active (Diesel)
          signal EngIdleRPM_Lvl: start 62, 2 bit, little-endian, data-type=c02_EngIdleRPM_Lvl, init-value=lIDLE_WARM, transfer-property=PENDING, to CPC ISM TCM  # Motor Leerlaufdrehzahlniveau / Engine idle speed level
          signal EngTrq_Unstbl_Stat: start 57, 3 bit, little-endian, data-type=c03_EngTrq_Unstbl_Stat, init-value=lSTABLE, transfer-property=PENDING, to CPC ISM TCM  # Motormoment instabil / Engine torque unstable
          signal EngTrqMaxNxtGr: start 32, 8 bit, little-endian, data-type=c08_Nm_0_1265_5, init-value=XDIS_f0jm83g6n4vnto6hmbi72xlou/l255, to CPC ISM TCM  # Maximal mögliches Motormoment im Folgegang / maximum possible engine torque for next gear
          signal Gr1_Rq_ECM: start 18, 1 bit, little-endian, data-type=DC_BOOL, init-value=XDIS_h5tcyk98kzbgrc5svasomeyt/lfalse, to CPC ISM TCM  # MS-Wunsch: "Anfahren 1.Gang" / Request driveaway with 1st gear by ECM
          signal OFC_Decel_Rdy: start 19, 1 bit, little-endian, data-type=DC_BOOL, init-value=XDIS_h5tcyk98kzbgrc5svasomeyt/lfalse, to CPC ISM TCM  # Verzögerung-Schubabschaltung bereit / Decceleration overrun fuel cutoff ready
          signal PtTrq_noTCMIntrvntn: start 40, 11 bit, little-endian, data-type=c11_Nm_m500_1546k0_1k0, init-value=XDIS_c1d4l3fliyrryv1w2ncd3uiy6/l2047, transfer-property=PENDING, to TCM  # Antriebsmoment ohne TCM-Eingriff / Torque without TCM intervention
          signal ShftChrDsp_Rq: start 12, 4 bit, little-endian, data-type=c04_ShftChrDsp_Rq, init-value=lSKL0, to CPC ISM TCM  # Anforderung Schaltlinienverschiebung / Shift characteristic displacement request
          signal SQC_Tx_Rq_PtMngmnt_ECM_Pr2: start 8, 4 bit, little-endian, data-type=c04_0_15_1_SNA_na, init-value=XDIS_2gdok7is6uk227cngmpgf9wxb/l0, to CPC ISM TCM  # Sequenzzähler / Sequence counter
          signal SSA_Dsabl_Eng: start 61, 1 bit, little-endian, data-type=DC_BOOL, init-value=XDIS_h5tcyk98kzbgrc5svasomeyt/lfalse, transfer-property=PENDING, to CPC  # Stop/start automatisch von Motor deaktiviert / Stop/start automatic disabled by engine
          signal TCC_Rq: start 16, 2 bit, little-endian, data-type=c02_TCC_Rq, init-value=XDIS_78dwd9co71eo75ypbfqjg5emx/l3, to CPC ISM TCM  # Kueb-Sollzustand Offen/Schlupfend / Torque converter lockup clutch request
          signal Rsrv4_Tx_Rq_PtMngmnt_ECM_Pr2: start 21, 2 bit, little-endian, data-type=Rsrv02, init-value=XDIS_7jeo5ges9wp8ufla3pohsuw83/l0, to CPC ISM TCM  # Reserviert für zukünftige Verwendung / Reserved for future use
          signal Tx_Rq_PtMngmnt_ECM_Pr2_esuvr5ltdwin8dor1y7m13584: little-endian, system-signal=[CRC_Tx_Rq_PtMngmnt_ECM_Pr2, Creep_Off_Rq, ECM_LHOM_Stat, EngExhstAfterTreat_Actv, EngTrqMaxNxtGr, Gr1_Rq_ECM, OFC_Decel_Rdy, Rsrv4_Tx_Rq_PtMngmnt_ECM_Pr2, ShftChrDsp_Rq, SQC_Tx_Rq_PtMngmnt_ECM_Pr2, TCC_Rq], transfer-property=PENDING, to CPC ISM TCM  # Schaltanforderung von Powertrain Management (degraded) / Transmission request from Powertrain management (degraded)
      frame PN14_Stat_AR: id 0x122, from CPC, to ASX ECM FFAP_STAR_2 FSCM ISM TCM, frame-length=8, can-addressing-mode=STANDARD  # Status 14V Bordnetz / Powernet 14V state
        pdu PN14_Stat_AR: length=64, unused-bit-pattern=0, cyclic-timing=repeating-time=0.1, event-controlled-timing=number-of-repeats=0, minimum-delay=0.0050  # Status 14V Bordnetz / Powernet 14V state
          signal DPM_ExtMd_Enbl_Rq: start 26, 2 bit, little-endian, data-type=c02_Ndef_NoExt_Ext, init-value=XDIS_2ww10q9x8mhbjoiy8rtqj5oin/lEXT, transfer-property=TRIGGERED-ON-CHANGE, to ECM FSCM TCM  # Freigabe External Mode durch dezentrales Power-Management / Decentral power management external mode enable request
          signal DPM_MdLmt_Rq: start 24, 2 bit, little-endian, data-type=c02_Sleep_Local_Ext, init-value=XDIS_e0f4j0yy4zy31nyz9m3jukr04/lEXT, transfer-property=TRIGGERED-ON-CHANGE, to ECM FSCM TCM  # Modus-Obergrenze dezentrales Power-Management / Decentral power management mode limit request
          signal LHC_ComfSys_Rq: start 63, 1 bit, little-endian, data-type=DC_BOOL, init-value=XDIS_h5tcyk98kzbgrc5svasomeyt/lfalse, transfer-property=TRIGGERED-ON-CHANGE  # Notabschaltung Komfortsysteme / Limp-home cutoff Comfort systems request
          signal LHC_CoolBox_R_Rq: start 55, 1 bit, little-endian, data-type=DC_BOOL, init-value=XDIS_h5tcyk98kzbgrc5svasomeyt/lfalse, transfer-property=TRIGGERED-ON-CHANGE  # Notabschaltung Fond-Kühlbox / Limp-home cutoff rear cooler box request
          signal LHC_EBL_Rq: start 47, 1 bit, little-endian, data-type=DC_BOOL, init-value=XDIS_h5tcyk98kzbgrc5svasomeyt/lfalse, transfer-property=TRIGGERED-ON-CHANGE  # Notabschaltung Heckscheibenheizung / Limp-home cutoff electric backlite heater request
          signal LHC_EngFan_50_Rq: start 39, 1 bit, little-endian, data-type=DC_BOOL, init-value=XDIS_h5tcyk98kzbgrc5svasomeyt/lfalse, transfer-property=TRIGGERED-ON-CHANGE, to ECM  # Notabschaltung Motorlüfter auf 50% / Limp-home cutoff engine fan to 50 % request
          signal LHC_ICH_Rq: start 54, 1 bit, little-endian, data-type=DC_BOOL, init-value=XDIS_h5tcyk98kzbgrc5svasomeyt/lfalse, transfer-property=TRIGGERED-ON-CHANGE  # Notabschaltung Standheizung / Limp-home cutoff independant car heater request
          signal LHC_IntFan_F_50_Rq: start 50, 1 bit, little-endian, data-type=DC_BOOL, init-value=XDIS_h5tcyk98kzbgrc5svasomeyt/lfalse, transfer-property=TRIGGERED-ON-CHANGE  # Notabschaltung Innenlüfter vorne auf 50% / Limp-home cutoff front interior fan to 50 % request
          signal LHC_IntFan_R_0_Rq: start 52, 1 bit, little-endian, data-type=DC_BOOL, init-value=XDIS_h5tcyk98kzbgrc5svasomeyt/lfalse, transfer-property=TRIGGERED-ON-CHANGE  # Limp-home cutoff rear interior fan to 0 % request
          signal LHC_IntFan_R_50_Rq: start 51, 1 bit, little-endian, data-type=DC_BOOL, init-value=XDIS_h5tcyk98kzbgrc5svasomeyt/lfalse, transfer-property=TRIGGERED-ON-CHANGE  # Notabschaltung Innenlüfter hinten auf 50% / Limp-home cutoff rear interior fan to 50 % request
          signal LHC_MirrHt_Rq: start 46, 1 bit, little-endian, data-type=DC_BOOL, init-value=XDIS_h5tcyk98kzbgrc5svasomeyt/lfalse, transfer-property=TRIGGERED-ON-CHANGE  # Notabschaltung Außenspiegelbeheizung / Limp-home cutoff mirror heater Request
          signal LHC_PkLmp_Rq: start 56, 1 bit, little-endian, data-type=DC_BOOL, init-value=XDIS_h5tcyk98kzbgrc5svasomeyt/lfalse, transfer-property=TRIGGERED-ON-CHANGE  # Abschaltanforderung Parklichter / Limp-home cutoff parking lamps request
          signal LHC_PosnLmp_Rq: start 57, 1 bit, little-endian, data-type=DC_BOOL, init-value=XDIS_h5tcyk98kzbgrc5svasomeyt/lfalse, transfer-property=TRIGGERED-ON-CHANGE  # Abschaltanforderung Standlicht / Limp-home cutoff position lamps request
          signal LHC_PT_Stg1_Rq: start 61, 1 bit, little-endian, data-type=DC_BOOL, init-value=XDIS_h5tcyk98kzbgrc5svasomeyt/lfalse, transfer-property=TRIGGERED-ON-CHANGE, to ECM  # Notabschaltung Antriebsstrang Stufe 1 / Limp-home cutoff powertrain stage 1 request
          signal LHC_PT_Stg2_Rq: start 62, 1 bit, little-endian, data-type=DC_BOOL, init-value=XDIS_h5tcyk98kzbgrc5svasomeyt/lfalse, transfer-property=TRIGGERED-ON-CHANGE, to ECM  # Notabschaltung Antriebsstrang Stufe 2 / Limp-home cutoff powertrain stage 2 request
          signal LHC_PTC1_Rq: start 38, 1 bit, little-endian, data-type=DC_BOOL, init-value=XDIS_h5tcyk98kzbgrc5svasomeyt/lfalse, transfer-property=TRIGGERED-ON-CHANGE, to ECM  # Notabschaltung PTC 1. Zweig / Limp-home cutoff PTC 1st branch request
          signal LHC_PTC2_Rq: start 37, 1 bit, little-endian, data-type=DC_BOOL, init-value=XDIS_h5tcyk98kzbgrc5svasomeyt/lfalse, transfer-property=TRIGGERED-ON-CHANGE, to ECM  # Notabschaltung PTC 2. Zweig / Limp-home cutoff PTC 2nd branch request
          signal LHC_PTC3_Rq: start 36, 1 bit, little-endian, data-type=DC_BOOL, init-value=XDIS_h5tcyk98kzbgrc5svasomeyt/lfalse, transfer-property=TRIGGERED-ON-CHANGE, to ECM  # Notabschaltung PTC 3. Zweig / Limp-home cutoff PTC 3rd branch request
          signal LHC_PTC4_Rq: start 35, 1 bit, little-endian, data-type=DC_BOOL, init-value=XDIS_h5tcyk98kzbgrc5svasomeyt/lfalse, transfer-property=TRIGGERED-ON-CHANGE, to ECM  # Notabschaltung PTC 4. Zweig / Limp-home cutoff PTC 4th branch request
          signal LHC_PTC5_Rq: start 34, 1 bit, little-endian, data-type=DC_BOOL, init-value=XDIS_h5tcyk98kzbgrc5svasomeyt/lfalse, transfer-property=TRIGGERED-ON-CHANGE, to ECM  # Notabschaltung PTC 5. Zweig / Limp-home cutoff PTC 5th branch request
          signal LHC_PTC6_Rq: start 33, 1 bit, little-endian, data-type=DC_BOOL, init-value=XDIS_h5tcyk98kzbgrc5svasomeyt/lfalse, transfer-property=TRIGGERED-ON-CHANGE, to ECM  # Notabschaltung PTC 6. Zweig / Limp-home cutoff PTC 6th branch request
          signal LHC_RHU_Rq: start 53, 1 bit, little-endian, data-type=DC_BOOL, init-value=XDIS_h5tcyk98kzbgrc5svasomeyt/lfalse, transfer-property=TRIGGERED-ON-CHANGE  # Notabschaltung Restwärmenutzung / Limp-home cutoff residual heat utilization request
          signal LHC_SeatHtStg1_Rq: start 42, 1 bit, little-endian, data-type=DC_BOOL, init-value=XDIS_h5tcyk98kzbgrc5svasomeyt/lfalse, transfer-property=TRIGGERED-ON-CHANGE  # Notabschaltung Sitzheizung Stufe 1 / Limp-home cutoff seat heating stage 1 request
          signal LHC_SeatHtStg2_Rq: start 41, 1 bit, little-endian, data-type=DC_BOOL, init-value=XDIS_h5tcyk98kzbgrc5svasomeyt/lfalse, transfer-property=TRIGGERED-ON-CHANGE  # Notabschaltung Sitzheizung Stufe 2 / Limp-home cutoff seat heating stage 2 request
          signal LHC_SeatHtStg3_Rq: start 40, 1 bit, little-endian, data-type=DC_BOOL, init-value=XDIS_h5tcyk98kzbgrc5svasomeyt/lfalse, transfer-property=TRIGGERED-ON-CHANGE  # Notabschaltung Sitzheizung Stufe 3 / Limp-home cutoff seat heating stage 3 request
          signal LHC_SeatVn_Rq: start 43, 1 bit, little-endian, data-type=DC_BOOL, init-value=XDIS_h5tcyk98kzbgrc5svasomeyt/lfalse, transfer-property=TRIGGERED-ON-CHANGE  # Notabschaltung Sitzbelüftung / Limp-home cutoff seat ventilation request
          signal LHC_StW_Ht_Rq: start 44, 1 bit, little-endian, data-type=DC_BOOL, init-value=XDIS_h5tcyk98kzbgrc5svasomeyt/lfalse, transfer-property=TRIGGERED-ON-CHANGE  # Notabschaltung Lenkradbeheizung / Limp-home cutoff steering wheel heater request
          signal LHC_Taxi_Rq: start 49, 1 bit, little-endian, data-type=DC_BOOL, init-value=XDIS_h5tcyk98kzbgrc5svasomeyt/lfalse, transfer-property=TRIGGERED-ON-CHANGE  # Notabschaltung Taxidachzeichen / Limp-home cutoff taxi roofsign/printer request
          signal LHC_Tlm_Rq: start 32, 1 bit, little-endian, data-type=DC_BOOL, init-value=XDIS_h5tcyk98kzbgrc5svasomeyt/lfalse, transfer-property=TRIGGERED-ON-CHANGE  # Notabschaltung Telematik/Audio/Telefon/GPS / Limp-home cutoff Telematics/Audio/Phone/GPS request
          signal LHC_TrkSock_Rq: start 59, 1 bit, little-endian, data-type=DC_BOOL, init-value=XDIS_h5tcyk98kzbgrc5svasomeyt/lfalse, transfer-property=TRIGGERED-ON-CHANGE  # Notabschaltung Kofferraumsteckdose/Zigarrenanzünder / Limp-home cutoff trunk socket/cigarette lighter request
          signal LHC_TrlrSock_Rq: start 58, 1 bit, little-endian, data-type=DC_BOOL, init-value=XDIS_h5tcyk98kzbgrc5svasomeyt/lfalse, transfer-property=TRIGGERED-ON-CHANGE  # Notabschaltung Anhängersteckdose / Limp-home cutoff trailer socket request
          signal LHC_WprPkHt_Rq: start 45, 1 bit, little-endian, data-type=DC_BOOL, init-value=XDIS_h5tcyk98kzbgrc5svasomeyt/lfalse, transfer-property=TRIGGERED-ON-CHANGE  # Notabschaltung Wischerablagenheizung / Limp-home cutoff wiper park position heater request
          signal LHC_WShHt_50_Rq: start 60, 1 bit, little-endian, data-type=DC_BOOL, init-value=XDIS_h5tcyk98kzbgrc5svasomeyt/lfalse, transfer-property=TRIGGERED-ON-CHANGE  # Notabschaltung Frontscheibenheizung auf 50% / Limp-home cutoff windshield heater to 50 % request
          signal LHC_WShHt_Rq: start 48, 1 bit, little-endian, data-type=DC_BOOL, init-value=XDIS_h5tcyk98kzbgrc5svasomeyt/lfalse, transfer-property=TRIGGERED-ON-CHANGE  # Notabschaltung Frontscheibenheizung / Limp-home cutoff windshield heater request
          signal PN14_eHeV_Enbl: start 30, 1 bit, little-endian, data-type=DC_BOOL, init-value=XDIS_h5tcyk98kzbgrc5svasomeyt/lfalse, transfer-property=PENDING  # eHeat/eVent erlaubt / eHeat/eVent enabled
          signal PN14_LHC_Actv: start 31, 1 bit, little-endian, data-type=DC_BOOL, init-value=XDIS_h5tcyk98kzbgrc5svasomeyt/lfalse, transfer-property=TRIGGERED-ON-CHANGE, to ECM TCM  # 14V-BN Notabschaltung aktiv / 14 V powernet limp-home cutoff active
          signal PN14_SupBat_Curr: start 8, 11 bit, little-endian, data-type=c11_A_m102k4_102k2_0k1, init-value=XDIS_1493hz1qjdm1qmt6pdh34vxlu/l2047, to ASX ECM FFAP_STAR_2 FSCM(timeout 10.05 s) ISM TCM  # Versorgungsbatterie Iststrom / Supply battery current
          signal PN14_SupBat_Volt: start 0, 8 bit, little-endian, data-type=c08_V_0_25k4_0k1, init-value=XDIS_6h0vlx83b98yborknhrn3o3li/l255, to ASX ECM FFAP_STAR_2 FSCM(timeout 10.05 s) ISM TCM  # Versorgungsbatterie Istspannung / Supply battery voltage
          signal PN14_SupBatCutSw_Stat: start 19, 2 bit, little-endian, data-type=c02_BatCutSw_Stat, init-value=XDIS_28in454bjabczdszdzybakplk/lCLS, to ASX ECM FFAP_STAR_2 FSCM(timeout 10.05 s) ISM TCM  # Status Batterietrennschalter / Supply battery cutoff switch state
          signal PN14_TransMd_Stat: start 28, 2 bit, little-endian, data-type=c02_TransMd_Stat, init-value=XDIS_csegq0grcmpyfro5u6kyzxmql/l3, transfer-property=TRIGGERED-ON-CHANGE, to ASX ECM FFAP_STAR_2 FSCM ISM TCM  # Bordnetz Status Transportmodus / Powernet transport mode status
          signal PN14_TransMd_Updt_Rq: start 22, 1 bit, little-endian, data-type=DC_BOOL, init-value=XDIS_h5tcyk98kzbgrc5svasomeyt/lfalse, transfer-property=TRIGGERED-ON-CHANGE  # Bordnetz Anforderung Update Transportmodus / Powernet transport mode update request
          signal SSA_EngRestart_Actv: start 21, 1 bit, little-endian, data-type=DC_BOOL, init-value=XDIS_h5tcyk98kzbgrc5svasomeyt/lfalse, transfer-property=PENDING  # ASS automatischer Motorwiederstart aktiv / Stop/start automatic engine restart active
          signal PN14_SupBat_Stat_aleu8fy7bsux9kh42xfztkzmi: little-endian, system-signal=[PN14_SupBat_Curr, PN14_SupBat_Volt, PN14_SupBatCutSw_Stat], transfer-property=PENDING, to ASX ECM FFAP_STAR_2 FSCM(timeout 10.05 s) ISM TCM  # Bordnetz 14V Status Verbraucherbatterie (degraded) / Powernet 14V Supply battery status (degraded)
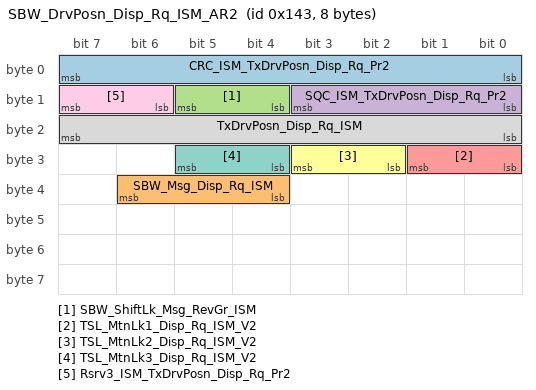
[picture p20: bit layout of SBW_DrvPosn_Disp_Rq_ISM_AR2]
      frame SBW_DrvPosn_Disp_Rq_ISM_AR2: id 0x143, from ISM, to CPC DRVU, frame-length=8, can-addressing-mode=STANDARD  # Anzeige Shift by Wire und Fahrstufe / Shift by wire and driving position display request
        pdu SBW_DrvPosn_Disp_Rq_ISM_AR2: length=64, unused-bit-pattern=0, cyclic-timing={repeating-time=0.2, starting-time=0.07}, event-controlled-timing=number-of-repeats=0, minimum-delay=0.02  # Anzeige Shift by Wire und Fahrstufe / Shift by wire and driving position display request
          signal CRC_ISM_TxDrvPosn_Disp_Rq_Pr2: start 0, 8 bit, little-endian, data-type=c08_CRC_woSNA, init-value=l155, transfer-property=PENDING, to CPC DRVU  # CRC-Checksumme der Signal Gruppe gemäß AUTOSAR Profil 2 / CRC-checksum of signal group according to AUTOSAR Profile 2
          signal SBW_Msg_Disp_Rq_ISM: start 36, 3 bit, little-endian, data-type=c03_SBW_Msg_Disp_Rq, init-value=XDIS_1btwp40vfzysklfc9vhyfb8lg/lIDLE, transfer-property=TRIGGERED-ON-CHANGE, to CPC  # Anforderung Shift by wire Meldung anzeigen / Shift by wire message display request
          signal SBW_ShiftLk_Msg_RevGr_ISM: start 12, 2 bit, little-endian, data-type=c02_SBW_ShiftLk_Msg_RevGr_TCM, init-value=XDIS_5ky3lk60o7o5ndyw6cx2aook/l3, transfer-property=TRIGGERED-ON-CHANGE, to CPC DRVU  # SBW Nachricht ISM "Bremse betätigen, um Rückwärtsgang einzulegen" / SBW Message from ISM "Press Brake to orient Reverse Gear"
          signal SQC_ISM_TxDrvPosn_Disp_Rq_Pr2: start 8, 4 bit, little-endian, data-type=c04_0_15_1_SNA_na, init-value=XDIS_2gdok7is6uk227cngmpgf9wxb/l0, transfer-property=PENDING, to CPC DRVU  # Sequenzzähler / Sequence counter
          signal TSL_MtnLk1_Disp_Rq_ISM_V2: start 24, 2 bit, little-endian, data-type=c02_TSL_MtnLk_Disp_Rq_V2, init-value=XDIS_46hl4413mztp2ukvqdcv4cwpj/lIDLE, transfer-property=TRIGGERED-ON-CHANGE, to CPC  # Anforderung Getriebewählhebelsperre 1 Anzeigeanforderung / Transmission selector lever motion lock 1 display request
          signal TSL_MtnLk2_Disp_Rq_ISM_V2: start 26, 2 bit, little-endian, data-type=c02_TSL_MtnLk2_3_Disp_Rq_V2, init-value=XDIS_ekoet742eksgh9ctith6nex6m/lIDLE, transfer-property=TRIGGERED-ON-CHANGE, to CPC  # Anforderung Getriebewählhebelsperre 2 Anzeigeanforderung / Transmission selector lever motion lock 2 display request
          signal TSL_MtnLk3_Disp_Rq_ISM_V2: start 28, 2 bit, little-endian, data-type=c02_TSL_MtnLk2_3_Disp_Rq_V2, init-value=XDIS_ekoet742eksgh9ctith6nex6m/lIDLE, transfer-property=TRIGGERED-ON-CHANGE, to CPC  # Anforderung Getriebewählhebelsperre 3 Anzeigeanforderung / Transmission selector lever motion lock 3 display request
          signal TxDrvPosn_Disp_Rq_ISM: start 16, 8 bit, little-endian, data-type=c08_TxDrvPosn, init-value=XDIS_1cx5hyudrxwg04ni87gsdlad7/l255, transfer-property=TRIGGERED-ON-CHANGE, to CPC DRVU  # Anforderung Anzeige Getriebefahrstufe / Transmission driving position display request
          signal Rsrv3_ISM_TxDrvPosn_Disp_Rq_Pr2: start 14, 2 bit, little-endian, data-type=Rsrv02, init-value=XDIS_7jeo5ges9wp8ufla3pohsuw83/l0, transfer-property=PENDING, to CPC DRVU  # Reserviert für zukünftige Verwendung / Reserved for future use
          signal ISM_TxDrvPosn_Disp_Rq_Pr2_epuwuk6swsjmfffk3fikh4w52: little-endian, system-signal=[CRC_ISM_TxDrvPosn_Disp_Rq_Pr2, Rsrv3_ISM_TxDrvPosn_Disp_Rq_Pr2, SBW_ShiftLk_Msg_RevGr_ISM, SQC_ISM_TxDrvPosn_Disp_Rq_Pr2, TxDrvPosn_Disp_Rq_ISM], to CPC DRVU  # Anforderung Anzeige Getriebefahrstufe (degraded) / Transmission driving position display request (degraded)
      frame PT_ThermM_AR2: id 0x149, from ECM, to CPC FSCM TCM, frame-length=2, can-addressing-mode=STANDARD  # Powertrain Thermal Management
        pdu PT_ThermM_AR2: length=16, unused-bit-pattern=0, cyclic-timing={repeating-time=0.5, starting-time=0.075}, event-controlled-timing=number-of-repeats=0, minimum-delay=0.1  # Powertrain Thermal Management
          signal EngOilTemp: start 0, 8 bit, little-endian, data-type=c08_degC_m40_160_1, init-value=XDIS_8zts0kx160si29lg57dawvd0v/l255, transfer-property=PENDING, to CPC FSCM TCM  # Motoröltemperatur / Engine oil temperature
          signal HtPwr_Stat: start 8, 2 bit, little-endian, data-type=c02_HtPwr_Stat, init-value=XDIS_7qoj6r9colqyo5dpw709poxq6/l3, transfer-property=TRIGGERED-ON-CHANGE, to CPC  # Status Heizleistung / Heating power state
      frame PtMngmnt_Stat_AR2: id 0x151, from CPC, to ASX DRVU ECM FSCM ISM TCM TGW, frame-length=8, can-addressing-mode=STANDARD  # Powertrain Management state
        pdu PtMngmnt_Stat_AR2: length=64, unused-bit-pattern=0, cyclic-timing={repeating-time=0.1, starting-time=0.0}, event-controlled-timing=number-of-repeats=0, minimum-delay=0.02  # Powertrain Management Status / Powertrain Management state
          signal Clutch_Disengg: start 0, 1 bit, little-endian, data-type=DC_BOOL, init-value=XDIS_h5tcyk98kzbgrc5svasomeyt/lfalse, transfer-property=TRIGGERED-ON-CHANGE  # Kupplung getreten / Clutch is disengaged
          signal CoastMd_Disp_Rq: start 29, 2 bit, little-endian, data-type=c02_CoastMd_Disp_Rq, init-value=lCOAST_INACTV, transfer-property=TRIGGERED-ON-CHANGE, to TCM  # Anzeigeanforderung Segeln / Coasting mode display request
          signal CRC_PT_Stat_Pr2: start 48, 8 bit, little-endian, data-type=c08_CRC_woSNA, init-value=l183, to DRVU(timeout 1.05 s) ECM FSCM ISM TCM  # CRC-Checksumme der Signal Gruppe gemäß AUTOSAR Profil 2 / CRC-checksum of signal group according to AUTOSAR Profile 2
          signal DL_AllDr_Stat_CPC: start 7, 1 bit, little-endian, data-type=c01_DL_AllDr_Stat_CPC, init-value=lALL_CLS, transfer-property=TRIGGERED-ON-CHANGE, to ASX TCM TGW  # Status aller Türen und Heckklappe / State of all doors and deck lid
          signal DPC_GlobalMd_TrgRq_CPC: start 42, 1 bit, little-endian, data-type=DC_BOOL, init-value=XDIS_h5tcyk98kzbgrc5svasomeyt/lfalse, transfer-property=TRIGGERED-ON-CHANGE, to TCM  # Fahrprogrammwahl: Global erneut anfordern / Driving program control: global mode trigger request
          signal DPC_Md_ASX_Rq_CPC: start 43, 4 bit, little-endian, data-type=c04_DPC_Md_ASX, init-value=XDIS_ee6lf6fesmlxx9pcig2c90tw0/lINIT, transfer-property=TRIGGERED-ON-CHANGE, to ASX(timeout 1.05 s) TGW(timeout 1.05 s)  # Fahrprogrammwahl: Anforderung ASX / Driving program control: ASX mode request
          signal DPC_Md_eDrv_Rs: start 27, 2 bit, little-endian, data-type=c02_NDef_On_Off, init-value=XDIS_3y644026va6c2x8rschu8ysp4/lOFF, transfer-property=TRIGGERED-ON-CHANGE, to DRVU(timeout 1.05 s)  # Fahrprogrammwahl: Antwort eDrive / Driving program control: eDrive response
          signal DPC_Md_ExhstFlap_Rs: start 31, 3 bit, little-endian, data-type=c03_DPC_Md_ExhaustFlap, init-value=XDIS_b6gytuw1gs6hpmeqn7dp2mvre/lCOMFORT, transfer-property=TRIGGERED-ON-CHANGE, to DRVU(timeout 1.05 s)  # Fahrprogrammwahl: Rückmeldung Abgasklappe Modus / Driving program control: ExhaustFlap mode response
          signal DPC_Md_SSA_Rs: start 25, 2 bit, little-endian, data-type=c02_DPC_Md_SSA, init-value=lSSA_ON, transfer-property=TRIGGERED-ON-CHANGE, to DRVU(timeout 1.05 s)  # Fahrprogrammwahl: Antwort Stopp/Start-Automatik / Driving program control: stop start automatic mode response
          signal EngRun_Edrive_Stat: start 40, 2 bit, little-endian, data-type=c02_Off_OnIdle_NDef, init-value=XDIS_e2t9m2m3ca6n6meo150yhdrbk/lOFF, transfer-property=TRIGGERED-ON-CHANGE, to TCM  # Status Verbrennungsmotor während elektrischem Fahren / Combustion Engine status during electric drive
          signal EngTrq_Ctrl_PT_Actv: start 39, 1 bit, little-endian, data-type=DC_BOOL, init-value=XDIS_h5tcyk98kzbgrc5svasomeyt/lfalse, transfer-property=TRIGGERED-ON-CHANGE, to TCM  # Powertrain Momentenführung aktiv / Powertrain Torque control active
          signal EngTrqInc_Enbl_TCM: start 1, 1 bit, little-endian, data-type=DC_BOOL, init-value=XDIS_h5tcyk98kzbgrc5svasomeyt/lfalse, transfer-property=PENDING, to TCM  # Enable Motordrehmoment-Erhöhung TCM / Enable engine torque increase request
          signal EngTrqIncChk_Avl: start 2, 1 bit, little-endian, data-type=DC_BOOL, init-value=XDIS_h5tcyk98kzbgrc5svasomeyt/lfalse, transfer-property=PENDING, to TCM  # Plausibilitätscheck für Motordrehmoment-Erhöhung vorhanden / Engine torque increase plausibility check available
          signal GrN_Engg_MTX: start 3, 1 bit, little-endian, data-type=DC_BOOL, init-value=XDIS_h5tcyk98kzbgrc5svasomeyt/lfalse, transfer-property=PENDING, to ECM  # "N" (neutral) eingelegt (nur Schaltgetriebe) / Gear "N" (neutral) engaged (only manual transmission)
          signal HVAC_CompOff_Rq: start 37, 1 bit, little-endian, data-type=DC_BOOL, init-value=XDIS_h5tcyk98kzbgrc5svasomeyt/lfalse, transfer-property=TRIGGERED-ON-CHANGE  # Anforderung HVAC Kompressor Aus / HVAC Compressor Off Rq
          signal HVAC_CompTrq_Max: start 8, 8 bit, little-endian, data-type=c08_Nm_0_63k5_0k25, init-value=XDIS_3tke51neyh9tc3i280hit3n6t/l255, transfer-property=PENDING  # Begrenzungs-Moment (Kurbelwelle) Klima-Kompressor / Maximum aircon compressor crankshaft torque
          signal LowFuelQual_Dtct: start 4, 1 bit, little-endian, data-type=DC_BOOL, init-value=XDIS_h5tcyk98kzbgrc5svasomeyt/lfalse, transfer-property=PENDING, to TCM  # Schlechtkraftstoff erkannt / Low fuel quality detected
          signal PT_Rdy_V2: start 60, 2 bit, little-endian, data-type=c02_PT_Rdy_V2, init-value=lPT_NOT_RDY, to DRVU(timeout 1.05 s) ECM FSCM ISM TCM  # Antrieb bereit / Powertrain ready
          signal RevGr_Engg_MTX_ECM: start 5, 2 bit, little-endian, data-type=c02_Disengg_Engg, init-value=XDIS_bjt3ib7wqik0sqxbiyd3ycy7c/l3, transfer-property=TRIGGERED-ON-CHANGE, to ECM  # Rückwärtsgang eingelegt (nur Schaltgetriebe) / Reverse gear engaged (only manual transmission)
          signal SQC_PT_Stat_Pr2: start 56, 4 bit, little-endian, data-type=c04_0_15_1_SNA_na, init-value=XDIS_2gdok7is6uk227cngmpgf9wxb/l0, to DRVU(timeout 1.05 s) ECM FSCM ISM TCM  # Sequenzzähler / Sequence counter
          signal SSA_Standby_Stat: start 62, 2 bit, little-endian, data-type=c02_SSA_Standby_Stat, init-value=XDIS_cl9hhu1gng8x671c0kz6fdpur/lDEFAULT, to DRVU(timeout 1.05 s) ECM FSCM ISM TCM  # Stop Start Standby Status
          signal SSP_Pwr_Rq: start 34, 2 bit, little-endian, data-type=c02_SSP_Pwr_Rq, init-value=XDIS_en42on5yw1lm3gyhbsc51ikyg/lNO_RQ, transfer-property=PENDING, to TCM  # Diagnoseanforderung der Zusatzölpumpe für Leistungserhöhung / SSP power request
          signal TargetRPM_TCM_Ack_Lmtd: start 38, 1 bit, little-endian, data-type=DC_BOOL, init-value=XDIS_h5tcyk98kzbgrc5svasomeyt/lfalse, transfer-property=TRIGGERED-ON-CHANGE, to TCM  # Angeforderte Solldrehzahl von PT umgesetzt, aber limitiert / Target engine RPM requested by TCM will be provided, but limited by powertrain
          signal TC_Start_Reset_Trgr: start 36, 1 bit, little-endian, data-type=DC_BOOL, init-value=XDIS_h5tcyk98kzbgrc5svasomeyt/lfalse, transfer-property=PENDING, to TCM  # Reiserechner "Ab Start Reset" Trigger / Trip computer start reset trigger
          signal VehFixMaxSpd_V2: start 16, 9 bit, little-endian, data-type=c09_km_p_h_0_500_1, init-value=l250, transfer-property=PENDING  # Feste Höchstgeschwindigkeit / Vehicle fixed maximum speed
          signal PT_Stat_Pr2_3par937a8yr160hqtiylu66k8: little-endian, system-signal=[CRC_PT_Stat_Pr2, PT_Rdy_V2, SQC_PT_Stat_Pr2, SSA_Standby_Stat], transfer-property=PENDING, update-indication-bit-position=47, to DRVU(timeout 1.05 s) ECM FSCM ISM TCM  # Powertrain status (degraded) / Powertrain stat (degraded)
      frame TCM_State3_AR2: id 0x15D, from TCM, to CPC DRVU ECM, frame-length=8, can-addressing-mode=STANDARD
        pdu TCM_State3_AR2: length=64, unused-bit-pattern=0, cyclic-timing={repeating-time=0.1, starting-time=0.05}, event-controlled-timing=number-of-repeats=0, minimum-delay=0.01
          signal Adap_K0: start 18, 1 bit, little-endian, data-type=DC_BOOL, init-value=XDIS_h5tcyk98kzbgrc5svasomeyt/lfalse, transfer-property=PENDING, to CPC ECM  # K0 fordert Adaptionszustand an
          signal Adap_KUEB: start 19, 1 bit, little-endian, data-type=DC_BOOL, init-value=XDIS_h5tcyk98kzbgrc5svasomeyt/lfalse, transfer-property=PENDING, to CPC ECM  # KÜB fordert Adaptionszustand an
          signal AdapTrq_Rq: start 28, 1 bit, little-endian, data-type=DC_BOOL, init-value=XDIS_h5tcyk98kzbgrc5svasomeyt/lfalse, transfer-property=PENDING, to CPC ECM  # Adaptionsanforderung / Request for adaption torque
          signal BasShftProg_Ok: start 23, 1 bit, little-endian, data-type=DC_BOOL, init-value=XDIS_h5tcyk98kzbgrc5svasomeyt/lfalse, transfer-property=PENDING, to CPC ECM  # Grundschaltprogramm o.k. / Basic shifting program ok
          signal CoastMd_Stat_TCM: start 26, 2 bit, little-endian, data-type=c02_CoastMd_Stat, init-value=lCOAST_DASBL, transfer-property=TRIGGERED-ON-CHANGE, to CPC DRVU(timeout 1.05 s) ECM  # Status Segeln vom TCM / Coasting mode state from TCM
          signal CylCutoff_Enbl_TCM: start 54, 1 bit, little-endian, data-type=DC_BOOL, init-value=XDIS_h5tcyk98kzbgrc5svasomeyt/lfalse, transfer-property=TRIGGERED-ON-CHANGE, to CPC ECM  # Zylinderabschaltung erlaubt / Cylinder cutoff enabled
          signal CylCutoff_Shift_Enbl: start 55, 1 bit, little-endian, data-type=c01_Disabled_Enabled, init-value=XDIS_6tykre2bg23tt4ujbskjxzeqb/lDSABL, transfer-property=TRIGGERED-ON-CHANGE, to CPC ECM  # ZAS shift enable
          signal DPC_Md_PwrFreeD_Plus_Rs: start 30, 2 bit, little-endian, data-type=c02_NDef_On_Off, init-value=XDIS_3y644026va6c2x8rschu8ysp4/lOFF, transfer-property=TRIGGERED-ON-CHANGE, to CPC DRVU(timeout 1.05 s)  # Fahrprogrammwahl: Antwort "Kraftfrei in D +" / Driving program control: "Power free in D +" response
          signal DPC_Md_Tx_Rs: start 52, 2 bit, little-endian, data-type=c02_NDef_Man_Auto, init-value=lAUTO, transfer-property=TRIGGERED-ON-CHANGE, to CPC DRVU(timeout 1.05 s)  # Fahrprogrammwahl: Antwort Getriebe (nur AMG) / Driving program control: transmission mode response (only AMG)
          signal DrvAwElmtAdap_Rq: start 29, 1 bit, little-endian, data-type=DC_BOOL, init-value=XDIS_h5tcyk98kzbgrc5svasomeyt/lfalse, transfer-property=TRIGGERED-ON-CHANGE, to CPC  # Adaptionswunsch Anfahrelement / Drive away element requests adaption
          signal DrvRst_Hi: start 5, 1 bit, little-endian, data-type=DC_BOOL, init-value=XDIS_h5tcyk98kzbgrc5svasomeyt/lfalse, transfer-property=PENDING, to CPC ECM  # Fahrwiderstand hoch / Drive resistance high
          signal MIL_On_Rq_TCM: start 4, 1 bit, little-endian, data-type=DC_BOOL, init-value=XDIS_h5tcyk98kzbgrc5svasomeyt/lfalse, transfer-property=PENDING, to CPC ECM  # Diagnose Kontrolllampe (OBD II) / Malfunction indicator lamp on request (OBD II)
          signal TCC_Opn_RemainTm_TCM: start 56, 6 bit, little-endian, data-type=c06_s_0_6d2_0d1, init-value=XDIS_9vf8oyj79fjmg5flnq3b19drd/l63, transfer-property=PENDING, to CPC  # Verbleibende Zeitdauer bis zum Öffnen der Wandlerüberbrückungskupplung / Remaining time till opening of torque converter lockup clutch
          signal TCC_Opn_Trgr: start 63, 1 bit, little-endian, data-type=DC_BOOL, init-value=XDIS_h5tcyk98kzbgrc5svasomeyt/lfalse, transfer-property=TRIGGERED-ON-CHANGE, to CPC  # Trigger zum Öffnen der Wandlerüberbrückungskupplung / Trigger for opening orque converter lockup clutch
          signal Tx_Agility_Stat: start 32, 8 bit, little-endian, data-type=c08_0_254_1, init-value=XDIS_1zhllr2xfwzb4a7tpzx4f54fs/l0, transfer-property=PENDING, to CPC  # Getriebe Fahrzustand / Transmission agility state
          signal TxDrvProgMan_Actv: start 7, 1 bit, little-endian, data-type=DC_BOOL, init-value=XDIS_h5tcyk98kzbgrc5svasomeyt/lfalse, transfer-property=PENDING, to CPC DRVU(timeout 1.05 s) ECM  # Fahrprogramm "Manuell" aktiv / Transmission driving program "Manual" active
          signal TxDrvProgManTemp_Actv: start 17, 1 bit, little-endian, data-type=DC_BOOL, init-value=XDIS_h5tcyk98kzbgrc5svasomeyt/lfalse, transfer-property=PENDING, to CPC DRVU(timeout 1.05 s) ECM  # Getriebefahrprogramm "Manuell Temporär" aktiv / Transmission driving program "Manual Temporarily" active
          signal TxLHOM2_Gr_Hold: start 49, 1 bit, little-endian, data-type=c01_TxLHOM2_Gr_Hold, init-value=XDIS_d9d4j8pud1bc2gccx30bxvgll/lNO_ERR, to CPC  # Gang wird gehalten / Gear is hold
          signal TxLHOM2_Gr_Lock: start 48, 1 bit, little-endian, data-type=c01_TxLHOM2_Gr_Lock, init-value=XDIS_19bpc3qki6ufb0nd2g04yymzw/lNO_ERR, to CPC  # Gänge sind verriegelt / Gears are locked
          signal TxLHOM2_Stat_Clutch: start 40, 4 bit, little-endian, data-type=c04_TxLHOM2_Stat_Clutch, init-value=XDIS_9wnti3b86z86vp5lluf598xvm/lNO_ERR, to CPC  # Getriebe Fehlerzustände Kupplung / Error condition Clutch
          signal TxLHOM2_Stat_Hybrid: start 46, 1 bit, little-endian, data-type=c01_TxLHOM2_Stat_Hybrid, init-value=XDIS_3d8w0ml35eo9p3omdramavqlz/lNO_ERR, to CPC  # Fehlerzustände Hybrid / Error Condition Hybrid
          signal TxLHOM2_Stat_OilPump: start 44, 2 bit, little-endian, data-type=c02_TxLHOM2_Stat_OilPump, init-value=XDIS_f4w4lghlkvlrhdq7uf1qiqcx8/lNO_ERR, to CPC  # Fehlerzustände Getriebeölpumpe / Error conditions oil pump
          signal TxLHOM2_TX_Hydr: start 51, 1 bit, little-endian, data-type=c01_TxLHOM2_TX_Hydr, init-value=XDIS_3wraeq63y46f1h635edz2q693/lNO_ERR, to CPC  # Hydraulischer Notlaufbetrieb / Hydraulic limp-home mode
          signal TxLHOM2_TX_PwrFree: start 50, 1 bit, little-endian, data-type=c01_TxLHOM2_TX_PwrFree, init-value=XDIS_eciuz8f875mp8z8df48vic54u/lNO_ERR, to CPC  # Getriebe ist kraftfrei / Transmission is power-free
          signal TxLHOM2_TX_Tractn: start 47, 1 bit, little-endian, data-type=c01_TxLHOM2_TX_Tractn, init-value=XDIS_19ur4oy7prrsmc5v5u3gi9jtd/lNO_ERR, to CPC  # Getrieb hält Traktion aufrecht / Transmission maintains traction
          signal TxMechStyle_V2: start 20, 3 bit, little-endian, data-type=c03_TxMechStyle, init-value=XDIS_7vktjk568kyyf5dxsiqxdhljy/l7, transfer-property=PENDING, to CPC  # Getriebemechanik-Variante / Transmission mechanics style
          signal TxOffRd_Actv: start 16, 1 bit, little-endian, data-type=DC_BOOL, init-value=XDIS_h5tcyk98kzbgrc5svasomeyt/lfalse, transfer-property=PENDING, to CPC ECM  # Geländegang aktiv / Transmission off-road active
          signal TxOil_Recirc_Rq: start 62, 1 bit, little-endian, data-type=DC_BOOL, init-value=XDIS_h5tcyk98kzbgrc5svasomeyt/lfalse, transfer-property=PENDING, to CPC  # Getriebeöl: Umwälzungsanforderung / Transmission Oil Recirculation Request
          signal TxOilTemp: start 8, 8 bit, little-endian, data-type=c08_degC_m50_204_1, init-value=XDIS_1qgh8ijswcrhuty1cyrfufsk3/l255, transfer-property=PENDING, to CPC DRVU(timeout 1.05 s) ECM  # Getriebeöltemperatur / Transmission oil temperature
          signal TxShiftStyle_V2: start 24, 2 bit, little-endian, data-type=c02_TxShiftStyle_V2, init-value=XDIS_6q0nuqtid6q3bbxouehdfsw29/l3, transfer-property=PENDING, to CPC  # Getriebe-Schaltungsvariante / Transmission shifting style
          signal TxTemp_Excess: start 6, 1 bit, little-endian, data-type=DC_BOOL, init-value=XDIS_h5tcyk98kzbgrc5svasomeyt/lfalse, transfer-property=PENDING, to CPC ECM  # Übertemperatur Getriebe / Excessive transmission temperature
          signal VehDrvProg_TCM_V3: start 0, 4 bit, little-endian, data-type=c04_VehDrvProg_V3, init-value=XDIS_bt1zhn7y1ejr6qxakir4f40fx/l15, transfer-property=PENDING, to CPC DRVU(timeout 1.05 s) ECM  # Fahrprogramm Getriebe (wird auch bei TxDrvProgMan_Actv = 1 gesendet) / Actual vehicle driving program (also sent during TxDrvProgMan_Actv = 1)
          signal TxLHOM2_Stat_api97m3bibe3r5flh3ubeb8ji: little-endian, system-signal=[TxLHOM2_Gr_Hold, TxLHOM2_Gr_Lock, TxLHOM2_Stat_Clutch, TxLHOM2_Stat_Hybrid, TxLHOM2_Stat_OilPump, TxLHOM2_TX_Hydr, TxLHOM2_TX_PwrFree, TxLHOM2_TX_Tractn], transfer-property=PENDING, to CPC  # Status Getriebenotlauf (degraded) / Transmission limp-home operation mode state (degraded)
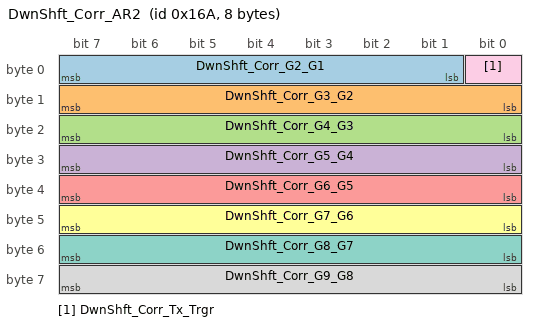
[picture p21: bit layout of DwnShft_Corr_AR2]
      frame DwnShft_Corr_AR2: id 0x16A, from CPC, to TCM, frame-length=8, can-addressing-mode=STANDARD  # Down Shift Correction
        pdu DwnShft_Corr_AR2: length=64, unused-bit-pattern=0, cyclic-timing={repeating-time=0.05, starting-time=0.03}, event-controlled-timing=number-of-repeats=0, minimum-delay=0.01  # Down Shift Correction
          signal DwnShft_Corr_G2_G1: start 1, 7 bit, little-endian, data-type=c07_0_127_1, init-value=XDIS_9261mudls0nkj1mlaum4vlelr/l0, transfer-property=PENDING, to TCM  # Rückschaltpunkt G2 zu G1 bezogen auf Getriebeabtriebsdrehzal (Faktor) / Downshift point G2 to G1 based on transmission output speed (factor)
          signal DwnShft_Corr_G3_G2: start 8, 8 bit, little-endian, data-type=c08_0_254_1, init-value=XDIS_1zhllr2xfwzb4a7tpzx4f54fs/l0, transfer-property=PENDING, to TCM  # Rückschaltpunkt G3 zu G2 bezogen auf Getriebeabtriebsdrehzal (Faktor) / Downshift point G3 to G2 based on transmission output speed (factor)
          signal DwnShft_Corr_G4_G3: start 16, 8 bit, little-endian, data-type=c08_0_254_1, init-value=XDIS_1zhllr2xfwzb4a7tpzx4f54fs/l0, transfer-property=PENDING, to TCM  # Rückschaltpunkt G4 zu G3 bezogen auf Getriebeabtriebsdrehzal (Faktor) / Downshift point G4 to G3 based on transmission output speed (factor)
          signal DwnShft_Corr_G5_G4: start 24, 8 bit, little-endian, data-type=c08_0_254_1, init-value=XDIS_1zhllr2xfwzb4a7tpzx4f54fs/l0, transfer-property=PENDING, to TCM  # Rückschaltpunkt G5 zu G4 bezogen auf Getriebeabtriebsdrehzal (Faktor) / Downshift point G5 to G4 based on transmission output speed (factor)
          signal DwnShft_Corr_G6_G5: start 32, 8 bit, little-endian, data-type=c08_0_254_1, init-value=XDIS_1zhllr2xfwzb4a7tpzx4f54fs/l0, transfer-property=PENDING, to TCM  # Rückschaltpunkt G6 zu G5 bezogen auf Getriebeabtriebsdrehzal (Faktor) / Downshift point G6 to G5 based on transmission output speed (factor)
          signal DwnShft_Corr_G7_G6: start 40, 8 bit, little-endian, data-type=c08_0_254_1, init-value=XDIS_1zhllr2xfwzb4a7tpzx4f54fs/l0, transfer-property=PENDING, to TCM  # Rückschaltpunkt G7 zu G6 bezogen auf Getriebeabtriebsdrehzal (Faktor) / Downshift point G7 to G6 based on transmission output speed (factor)
          signal DwnShft_Corr_G8_G7: start 48, 8 bit, little-endian, data-type=c08_0_254_1, init-value=XDIS_1zhllr2xfwzb4a7tpzx4f54fs/l0, transfer-property=PENDING, to TCM  # Rückschaltpunkt G8 zu G7 bezogen auf Getriebeabtriebsdrehzal (Faktor) / Downshift point G8 to G7 based on transmission output speed (factor)
          signal DwnShft_Corr_G9_G8: start 56, 8 bit, little-endian, data-type=c08_0_254_1, init-value=XDIS_1zhllr2xfwzb4a7tpzx4f54fs/l0, transfer-property=PENDING, to TCM  # Rückschaltpunkt G9 zu G8 bezogen auf Getriebeabtriebsdrehzal (Faktor) / Downshift point G9 to G8 based on transmission output speed (factor)
          signal DwnShft_Corr_Tx_Trgr: start 0, 1 bit, little-endian, data-type=DC_BOOL, init-value=XDIS_h5tcyk98kzbgrc5svasomeyt/lfalse, transfer-property=TRIGGERED-ON-CHANGE, to TCM  # Sendetrigger für die Herunterschalten PDU / Transmit Trigger for Downshift PDU
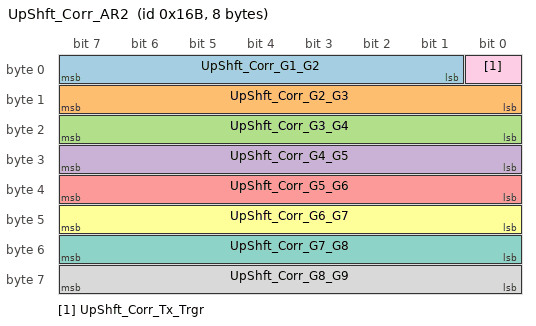
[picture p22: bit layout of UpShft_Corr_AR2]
      frame UpShft_Corr_AR2: id 0x16B, from CPC, to TCM, frame-length=8, can-addressing-mode=STANDARD  # Up Shift Correction
        pdu UpShft_Corr_AR2: length=64, unused-bit-pattern=0, cyclic-timing={repeating-time=0.05, starting-time=0.025}, event-controlled-timing=number-of-repeats=0, minimum-delay=0.01  # Up Shift Correction
          signal UpShft_Corr_G1_G2: start 1, 7 bit, little-endian, data-type=c07_0_127_1, init-value=XDIS_9261mudls0nkj1mlaum4vlelr/l0, transfer-property=PENDING, to TCM  # Hochschaltpunkt G1 zu G2 bezogen auf Getriebeabtriebsdrehzal (Faktor) / Upshift point G1 to G2 based on transmission output speed (factor)
          signal UpShft_Corr_G2_G3: start 8, 8 bit, little-endian, data-type=c08_0_254_1, init-value=XDIS_1zhllr2xfwzb4a7tpzx4f54fs/l0, transfer-property=PENDING, to TCM  # Hochschaltpunkt G2 zu G3 bezogen auf Getriebeabtriebsdrehzal (Faktor) / Upshift point G2 to G3 based on transmission output speed (factor)
          signal UpShft_Corr_G3_G4: start 16, 8 bit, little-endian, data-type=c08_0_254_1, init-value=XDIS_1zhllr2xfwzb4a7tpzx4f54fs/l0, transfer-property=PENDING, to TCM  # Hochschaltpunkt G3 zu G4 bezogen auf Getriebeabtriebsdrehzal (Faktor) / Upshift point G3 to G4 based on transmission output speed (factor)
          signal UpShft_Corr_G4_G5: start 24, 8 bit, little-endian, data-type=c08_0_254_1, init-value=XDIS_1zhllr2xfwzb4a7tpzx4f54fs/l0, transfer-property=PENDING, to TCM  # Hochschaltpunkt G4 zu G5 bezogen auf Getriebeabtriebsdrehzal (Faktor) / Upshift point G4 to G5 based on transmission output speed (factor)
          signal UpShft_Corr_G5_G6: start 32, 8 bit, little-endian, data-type=c08_0_254_1, init-value=XDIS_1zhllr2xfwzb4a7tpzx4f54fs/l0, transfer-property=PENDING, to TCM  # Hochschaltpunkt G5 zu G6 bezogen auf Getriebeabtriebsdrehzal (Faktor) / Upshift point G5 to G6 based on transmission output speed (factor)
          signal UpShft_Corr_G6_G7: start 40, 8 bit, little-endian, data-type=c08_0_254_1, init-value=XDIS_1zhllr2xfwzb4a7tpzx4f54fs/l0, transfer-property=PENDING, to TCM  # Hochschaltpunkt G6 zu G7 bezogen auf Getriebeabtriebsdrehzal (Faktor) / Upshift point G6 to G7 based on transmission output speed (factor)
          signal UpShft_Corr_G7_G8: start 48, 8 bit, little-endian, data-type=c08_0_254_1, init-value=XDIS_1zhllr2xfwzb4a7tpzx4f54fs/l0, transfer-property=PENDING, to TCM  # Hochschaltpunkt G7 zu G8 bezogen auf Getriebeabtriebsdrehzal (Faktor) / Upshift point G7 to G8 based on transmission output speed (factor)
          signal UpShft_Corr_G8_G9: start 56, 8 bit, little-endian, data-type=c08_0_254_1, init-value=XDIS_1zhllr2xfwzb4a7tpzx4f54fs/l0, transfer-property=PENDING, to TCM  # Hochschaltpunkt G8 zu G9 bezogen auf Getriebeabtriebsdrehzal (Faktor) / Upshift point G8 to G9 based on transmission output speed (factor)
          signal UpShft_Corr_Tx_Trgr: start 0, 1 bit, little-endian, data-type=DC_BOOL, init-value=XDIS_h5tcyk98kzbgrc5svasomeyt/lfalse, transfer-property=TRIGGERED-ON-CHANGE, to TCM  # Sendetrigger für die Hochschalten PDU / Transmit Trigger for Upshift PDU
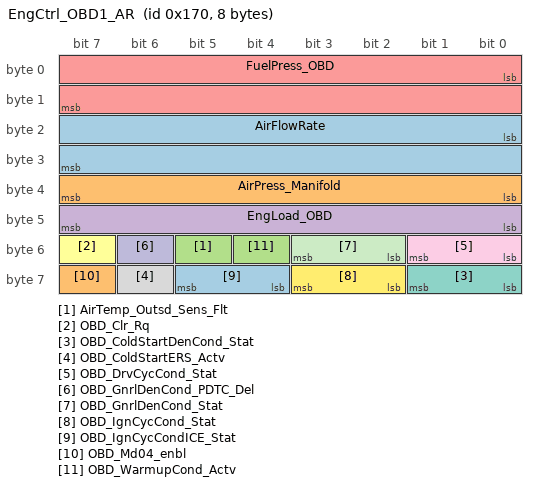
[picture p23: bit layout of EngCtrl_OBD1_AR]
      frame EngCtrl_OBD1_AR: id 0x170, from ECM, to CPC FSCM TCM, frame-length=8, can-addressing-mode=STANDARD
        pdu EngCtrl_OBD1_AR: length=64, unused-bit-pattern=0, cyclic-timing={repeating-time=0.1, starting-time=0.045}
          signal AirFlowRate: start 16, 16 bit, little-endian, data-type=c16_g_p_s_0_655k34_0k01_nSNA, init-value=XDIS_9c2ktvv4dqi4a8yers35z0afm/l0, to CPC FSCM(timeout 1.05 s) TCM  # Luftmengendurchsatz vom Luftmassenmesser / Air flow rate from mass air flow sensor
          signal AirPress_Manifold: start 32, 8 bit, little-endian, data-type=c08_kPa_0_254_1, init-value=XDIS_c5xycso0vrr1p5epixucixwbx/l0, to CPC FSCM(timeout 1.05 s) TCM  # Luftdruck in Einlasskrümmer / Air pressure in intake manifold
          signal AirTemp_Outsd_Sens_Flt: start 53, 1 bit, little-endian, data-type=DC_BOOL, init-value=XDIS_h5tcyk98kzbgrc5svasomeyt/lfalse, to CPC FSCM(timeout 1.05 s) TCM  # Fehler Außenlufttemperatur-Sensor / Outside air temperature sensor fault
          signal EngLoad_OBD: start 40, 8 bit, little-endian, data-type=c08_perc_0_100_0k3922_nSNA, init-value=XDIS_6nwcppt78y5a4afdqmccomosu/l0, to CPC FSCM(timeout 1.05 s) TCM  # Motorlast / Engine load
          signal FuelPress_OBD: start 0, 16 bit, little-endian, data-type=c16_kPa_0_655350_10_nSNA, init-value=XDIS_e9zhhnisie6tjwwjh17mqaa4r/l65535, to CPC FSCM(timeout 1.05 s) TCM  # Aktueller Kraftstoffdruck / Actual fuel pressure
          signal OBD_Clr_Rq: start 55, 1 bit, little-endian, data-type=DC_BOOL, init-value=XDIS_h5tcyk98kzbgrc5svasomeyt/lfalse, transfer-property=PENDING, to CPC  # OBD-Fehlerspeicherdaten löschen / OBD fault memory clear request
          signal OBD_ColdStartDenCond_Stat: start 56, 2 bit, little-endian, data-type=c02_OBD_Cond_Stat, init-value=XDIS_6e9q4150byqlwe23kptfa43j2/lINACT, transfer-property=PENDING, to CPC  # Status Bedingungen für Kaltstart Denominator (RBM) / Conditions for cold start denominator (RBM) state
          signal OBD_ColdStartERS_Actv: start 62, 1 bit, little-endian, data-type=DC_BOOL, init-value=XDIS_h5tcyk98kzbgrc5svasomeyt/lfalse, transfer-property=PENDING, to CPC FSCM(timeout 1.05 s) TCM  # Kaltstart Emissionsreduzierungsstrategie aktiv / Cold Start Emission Reduction Strategy active
          signal OBD_DrvCycCond_Stat: start 48, 2 bit, little-endian, data-type=c02_OBD_Cond_Stat, init-value=XDIS_6e9q4150byqlwe23kptfa43j2/lINACT, to CPC FSCM(timeout 1.05 s) TCM  # Bedingungen für OBD Fahrzyklusstatus / Conditions for OBD Driving Cycle state
          signal OBD_GnrlDenCond_PDTC_Del: start 54, 1 bit, little-endian, data-type=DC_BOOL, init-value=XDIS_h5tcyk98kzbgrc5svasomeyt/lfalse, to CPC FSCM(timeout 1.05 s) TCM  # Bedingung zum Löschen der permanenten Fehlercodes des General Denominator (RBM) erfüllt / Condition to delete permanent diagnostic trouble codes of general denominator (RBM) fulfilled
          signal OBD_GnrlDenCond_Stat: start 50, 2 bit, little-endian, data-type=c02_OBD_Cond_Stat, init-value=XDIS_6e9q4150byqlwe23kptfa43j2/lINACT, to CPC FSCM(timeout 1.05 s) TCM  # Status Bedingungen für General Denominator (RBM) / Conditions for general denominator (RBM) state
          signal OBD_IgnCycCond_Stat: start 58, 2 bit, little-endian, data-type=c02_OBD_IgnCycCond_Stat, init-value=XDIS_79kcl4xvfeg18xpfwptyrag20/lINACT, transfer-property=PENDING, to CPC FSCM(timeout 1.05 s) TCM  # Bedingungen für OBD Zündungszyklus (RBM) erfüllt / Conditions for OBD Ignition Cycle (RBM) fullfilled
          signal OBD_IgnCycCondICE_Stat: start 60, 2 bit, little-endian, data-type=c02_OBD_IgnCycCondICE_Stat, init-value=XDIS_603bz7gng9wboqmhgqjtjb9et/lINACT, transfer-property=PENDING, to CPC FSCM(timeout 1.05 s) TCM  # Vorraussetzungen für "OBD Zündungszyklus mit laufendem internem Verbrennungsmotor" erfüllt / Conditions for 'OBD Ignition Cycle with Internal Combustion Engine running' fullfilled
          signal OBD_Md04_enbl: start 63, 1 bit, little-endian, data-type=DC_BOOL, init-value=XDIS_h5tcyk98kzbgrc5svasomeyt/lfalse, transfer-property=PENDING, to CPC FSCM(timeout 1.05 s) TCM  # OBD Service 404 (Fehlerspeicher löschen) erlaubt / OBD service $04 (fault memory clear) enabled
          signal OBD_WarmupCond_Actv: start 52, 1 bit, little-endian, data-type=DC_BOOL, init-value=XDIS_h5tcyk98kzbgrc5svasomeyt/lfalse, to CPC FSCM(timeout 1.05 s) TCM  # Bedingungen für Warm-Up erfüllt / Conditions for warm-up fulfilled
          signal ECM_OBD_6qh6mjv6xjqli5tjiuho3zgjz: little-endian, system-signal=[AirFlowRate, AirPress_Manifold, AirTemp_Outsd_Sens_Flt, EngLoad_OBD, FuelPress_OBD, OBD_DrvCycCond_Stat, OBD_GnrlDenCond_PDTC_Del, OBD_GnrlDenCond_Stat, OBD_WarmupCond_Actv], transfer-property=PENDING, to CPC FSCM(timeout 1.05 s) TCM  # Motorsteuergerät OBD (degraded) / Engine control module OBD (degraded)
      frame EngCtrl_OBD4_AR2: id 0x173, from CPC, to ECM FSCM TCM, frame-length=8, can-addressing-mode=STANDARD
        pdu EngCtrl_OBD4_AR2: length=64, unused-bit-pattern=0, cyclic-timing={repeating-time=0.1, starting-time=0.01}
          signal AccelPdlPosn_OBD: start 8, 8 bit, little-endian, data-type=c08_perc_0_100_0k3922_nSNA, init-value=XDIS_6nwcppt78y5a4afdqmccomosu/l0, to ECM FSCM TCM  # Pedalwert / Accelerator pedal position
          signal AccelPdlPosn_Red_OBD: start 0, 8 bit, little-endian, data-type=c08_perc_0_100_0k3922_nSNA, init-value=XDIS_6nwcppt78y5a4afdqmccomosu/l0, to ECM FSCM TCM  # Redundanter Pedalwert / Redundant accelerator pedal position
          signal OBD_ColdStartERS_EMTrqRng_Rq: start 62, 2 bit, little-endian, data-type=c02_OBD_CSERS_EMTrqRng_Rq, init-value=lTRQ_CSERS_OFF, transfer-property=PENDING  # Drehmomentbereichanforderung an EM zur Lasterhöhung/Lastreduktion für Emissionsreduzierung bei Kaltstart / Torque range request to EM for load increase/decrease for emission reduction during cold start
          signal PdlPosn_OBD_c3ryvzr3q34rn6bg9vzbp6trj: little-endian, system-signal=[AccelPdlPosn_OBD, AccelPdlPosn_Red_OBD], transfer-property=PENDING, to ECM FSCM TCM  # Redundanter Pedalwert (degraded) / accelerator pedal position (degraded)
      frame DPC_SHW_Rq2_AR2: id 0x177, from CPC, to TCM, frame-length=8, can-addressing-mode=STANDARD  # Shift By Wire Request
        pdu DPC_SHW_Rq2_AR2: length=64, unused-bit-pattern=0, cyclic-timing={repeating-time=0.1, starting-time=0.065}, event-controlled-timing=number-of-repeats=0, minimum-delay=0.01  # Shift By Wire Request
          signal CRC_SHW_Rq2_Pr2: start 0, 8 bit, little-endian, data-type=c08_CRC_woSNA, init-value=l74, transfer-property=PENDING, to TCM  # CRC-Checksumme der Signal Gruppe gemäß AUTOSAR Profil 2 / CRC-checksum of signal group according to AUTOSAR Profile 2
          signal DPC_Md_PT_Rs: start 58, 4 bit, little-endian, data-type=c04_DPC_Md_PT, init-value=XDIS_didolfsk1r6nfzojvd6lbxo4w/lCOMFORT, transfer-property=TRIGGERED-ON-CHANGE, to TCM  # Fahrprogrammwahl: Antwort Powertrain / Driving program control: powertrain mode response
          signal DPC_Md_PwrFreeD_Plus_Rs_CPC: start 56, 2 bit, little-endian, data-type=c02_NDef_On_Off, init-value=XDIS_3y644026va6c2x8rschu8ysp4/lOFF, transfer-property=TRIGGERED-ON-CHANGE, to TCM  # Fahrprogrammwahl: Antwort "Kraftfrei in D +" / Driving program control: "Power free in D +" response
          signal DPC_Md_Tx_Rs_CPC: start 62, 2 bit, little-endian, data-type=c02_NDef_Man_Auto, init-value=lAUTO, transfer-property=TRIGGERED-ON-CHANGE, to TCM  # Fahrprogrammwahl: Antwort Getriebe (nur AMG) vom CPC / Driving program control: transmission mode response (only AMG) from CPC
          signal Key_P_Enbl_CPC: start 34, 1 bit, little-endian, data-type=DC_BOOL, init-value=XDIS_h5tcyk98kzbgrc5svasomeyt/lfalse, transfer-property=TRIGGERED-ON-CHANGE, to TCM  # Taste "P Einlegen" freigegeben von CPC / Key-P-engage enabled from CPC
          signal PARK_DrvDir_Stat_CPC: start 18, 4 bit, little-endian, data-type=c04_PARK_DrvDir_Stat_EBS, init-value=XDIS_5cef29zuo9cutic9pjz31ahco/l15, transfer-property=TRIGGERED-ON-CHANGE, to TCM  # ParkMan Status Fahrtrichtung von CPC / ParkMan driving direction state from CPC
          signal ShW_DrvPosn_PRND_Lever_CPC: start 26, 4 bit, little-endian, data-type=c04_Axl_DrvPosn, init-value=XDIS_7fuy3lbapfu6pimv173ymd816/l15, transfer-property=TRIGGERED-ON-CHANGE, to TCM  # plausibilisierte Fahrstufe Bedienelement / Driving Position of the Shifter Lever with plausibility check
          signal SHW_Emg_P_Path_Rq: start 22, 2 bit, little-endian, data-type=c02_Enable_Disable, init-value=XDIS_1k5vkm94zt4a73vdeqoa0g6c7/l3, transfer-property=TRIGGERED-ON-CHANGE, to TCM  # Fahrposition P: Notfallpfadanforderung für Hauptantriebsachse / Driving position P emergency path request for main traction axle
          signal SHW_MnTrctAxl_D_Allowed: start 38, 1 bit, little-endian, data-type=DC_BOOL, init-value=XDIS_h5tcyk98kzbgrc5svasomeyt/lfalse, transfer-property=TRIGGERED-ON-CHANGE, to TCM  # Hauptantriebsachse: Fahrposition D erlaubt / Main traction axle driving position D is allowed
          signal SHW_MnTrctAxl_DrvPosn_Imm_Rq: start 24, 2 bit, little-endian, data-type=c02_Inact_Act, init-value=XDIS_3oivp0pi6kmqha929czbczm38/l3, transfer-property=TRIGGERED-ON-CHANGE, to TCM  # Sofortige Zielsfahrstufenanforderung für Hauptantriebsachse / Immediate main traction axle driving position target request
          signal SHW_MnTrctAxl_DrvPosn_N_Actv_Rq: start 16, 2 bit, little-endian, data-type=c02_Inact_Act, init-value=XDIS_3oivp0pi6kmqha929czbczm38/l3, transfer-property=TRIGGERED-ON-CHANGE, to TCM  # Shift by Wire Fahrstufenanforderung "N" für Hauptantriebsachse / Shift by Wire main traction axle driving position N Active Request
          signal SHW_MnTrctAxl_DrvPosn_Target_Rq: start 12, 4 bit, little-endian, data-type=c04_Axl_DrvPosn, init-value=XDIS_7fuy3lbapfu6pimv173ymd816/l15, transfer-property=TRIGGERED-ON-CHANGE, to TCM  # Zielfahrstufe für Hauptantriebsachse / Driving position target for the main traction axle
          signal SHW_MnTrctAxl_N_Allowed: start 39, 1 bit, little-endian, data-type=DC_BOOL, init-value=XDIS_h5tcyk98kzbgrc5svasomeyt/lfalse, transfer-property=TRIGGERED-ON-CHANGE, to TCM  # Hauptantriebsachse: Fahrposition N erlaubt / Main traction axle driving position N is allowed
          signal SHW_MnTrctAxl_P_Allowed: start 30, 1 bit, little-endian, data-type=DC_BOOL, init-value=XDIS_h5tcyk98kzbgrc5svasomeyt/lfalse, transfer-property=TRIGGERED-ON-CHANGE, to TCM  # Hauptantriebsachse: Fahrposition P erlaubt / Main traction axle driving position P is allowed
          signal SHW_MnTrctAxl_R_Allowed: start 40, 1 bit, little-endian, data-type=DC_BOOL, init-value=XDIS_h5tcyk98kzbgrc5svasomeyt/lfalse, transfer-property=TRIGGERED-ON-CHANGE, to TCM  # Hauptantriebsachse: Fahrposition R erlaubt / Main traction axle driving position R is allowed
          signal ShW_MnTrctAxl_ShiftLk_Stat: start 36, 2 bit, little-endian, data-type=c02_TSL_ShiftLk_Stat, init-value=XDIS_7yalllmilw1ujjshxp2jku3lj/lIDLE, transfer-property=TRIGGERED-ON-CHANGE, to TCM  # Status Getriebewählhebel Shift-Lock-Sperre / Transmission selector lever shift lock state
          signal SPCR_Dsabl_Rq_CPC: start 35, 1 bit, little-endian, data-type=DC_BOOL, init-value=XDIS_h5tcyk98kzbgrc5svasomeyt/lfalse, transfer-property=TRIGGERED-ON-CHANGE, to TCM  # Anforderung Stillstandskoordinator (Hold/Stop) abschalten vom CPC / Stop coordinator (Hold/Stop) disable request from CPC
          signal SQC_SHW_Rq2_Pr2: start 8, 4 bit, little-endian, data-type=c04_0_15_1_SNA_na, init-value=XDIS_2gdok7is6uk227cngmpgf9wxb/l0, transfer-property=PENDING, to TCM  # Sequenzzähler / Sequence counter
          signal TxDrvProgMan_Actv_CPC: start 55, 1 bit, little-endian, data-type=DC_BOOL, init-value=XDIS_h5tcyk98kzbgrc5svasomeyt/lfalse, transfer-property=TRIGGERED-ON-CHANGE, to TCM  # Getriebe Manualprogramm aktiv von CPC / Transmission driving program "Manual" active from CPC
          signal TxLHOM_Stat_Rq_CPC: start 31, 3 bit, little-endian, data-type=c03_TxLHOM_Stat_Rq_CPC, init-value=lNO_REQ, transfer-property=TRIGGERED-ON-CHANGE, to TCM  # Anforderung Getriebe Notlauf von CPC / CPC request TCM limp-home mode
          signal Rsrv0_SHW_Rq2_Pr2: start 41, 7 bit, little-endian, data-type=Rsrv07, init-value=XDIS_1uvqkcvexva3vp6bv7zoxjawg/l0, transfer-property=PENDING, to TCM  # Reserviert für zukünftige Verwendung / Reserved for future use
          signal SHW_Rq2_Pr2_25eo2jxdt9eomhrgzz8hck6us: little-endian, system-signal=[CRC_SHW_Rq2_Pr2, Key_P_Enbl_CPC, PARK_DrvDir_Stat_CPC, Rsrv0_SHW_Rq2_Pr2, ShW_DrvPosn_PRND_Lever_CPC, SHW_Emg_P_Path_Rq, SHW_MnTrctAxl_D_Allowed, SHW_MnTrctAxl_DrvPosn_Imm_Rq, SHW_MnTrctAxl_DrvPosn_N_Actv_Rq, SHW_MnTrctAxl_DrvPosn_Target_Rq, SHW_MnTrctAxl_N_Allowed, SHW_MnTrctAxl_P_Allowed, SHW_MnTrctAxl_R_Allowed, ShW_MnTrctAxl_ShiftLk_Stat, SPCR_Dsabl_Rq_CPC, SQC_SHW_Rq2_Pr2, TxLHOM_Stat_Rq_CPC], to TCM  # Shift By Wire Request (degraded)
